VERSION "HNNBNNNYNNNNNNNNNNNNNNNNNNNNNNNNNNNNNNNNNN/4/%%%/4/'%**4NNN///"

NS_ :

BS_:

BU_: BAP_Tester BMS_NV_12V Gateway_Max Klima

BO_ 252 ESC_51_Auth: 64 Gateway_Max
 SG_ ESC_51_CRC : 0|8@1+ (1,0) [0|255] ""  Vector__XXX
 SG_ ESC_51_BZ : 8|4@1+ (1,0) [0|15] ""  Vector__XXX
 SG_ ESC_aktBR_Modus_02 : 12|2@1+ (1.0,0.0) [0.0|3] ""  Vector__XXX
 SG_ ESC_Blending_Solldruck : 14|10@1+ (0.25,0) [0.00|250.00] "Unit_Bar"  Vector__XXX
 SG_ ESC_aktBr_Volumenstrom : 24|16@1+ (0.0078125,-252) [-252.0000000|252.0000000] "Unit_MilliLiterPerSec"  Vector__XXX
 SG_ ESC_EBKV_Kraftblending_Modus : 40|2@1+ (1.0,0.0) [0.0|3] ""  Vector__XXX
 SG_ ESC_Bremsdruck_Modell : 42|10@1+ (0.25,0) [0.00|250.00] "Unit_Bar"  Vector__XXX
 SG_ ESC_Bremsdruck_02 : 52|10@1+ (0.3,-30) [-30.0|276.6] "Unit_Bar"  Vector__XXX
 SG_ ESC_QBit_Bremsdruck_02 : 62|1@1+ (1.0,0.0) [0.0|1] ""  Vector__XXX
 SG_ ESC_Allradverteilung_aktiv : 63|1@1+ (1.0,0.0) [0.0|1] ""  Vector__XXX
 SG_ ESP_HL_Radgeschw_02 : 64|16@1+ (0.0075,0) [0.0000|491.4900] "Unit_KiloMeterPerHour"  Vector__XXX
 SG_ ESP_HR_Radgeschw_02 : 80|16@1+ (0.0075,0) [0.0000|491.4900] "Unit_KiloMeterPerHour"  Vector__XXX
 SG_ ESP_VL_Radgeschw_02 : 96|16@1+ (0.0075,0) [0.0000|491.4900] "Unit_KiloMeterPerHour"  Vector__XXX
 SG_ ESP_VR_Radgeschw_02 : 112|16@1+ (0.0075,0) [0.0000|491.4900] "Unit_KiloMeterPerHour"  Vector__XXX
 SG_ ESP_FZR_uebersteuern : 128|8@1+ (0.004,0) [0.000|1.000] ""  Vector__XXX
 SG_ ESP_FZR_untersteuern : 136|8@1+ (0.004,0) [0.000|1.000] ""  Vector__XXX
 SG_ ESC_Anf_Mindestreku : 144|1@1+ (1.0,0.0) [0.0|1] ""  Vector__XXX
 SG_ ESC_GMV_aktiv : 145|3@1+ (1.0,0.0) [0.0|7] ""  Vector__XXX
 SG_ ESC_GMV_nicht_verfuegbar : 148|1@1+ (1.0,0.0) [0.0|1] ""  Vector__XXX
 SG_ ESC_Status_vRef_Stuetzeingriff : 149|1@1+ (1.0,0.0) [0.0|1] ""  Vector__XXX
 SG_ FDR_Allradverteilung_aktiv : 150|1@1+ (1.0,0.0) [0.0|1] ""  Vector__XXX
 SG_ FDR_Anf_Allradbetrieb : 151|1@1+ (1.0,0.0) [0.0|1] ""  Vector__XXX
 SG_ ESP_HL_Bremsmoment : 152|8@1+ (20,0) [0|5060] "Unit_NewtoMeter"  Vector__XXX
 SG_ ESP_HR_Bremsmoment : 160|8@1+ (20,0) [0|5060] "Unit_NewtoMeter"  Vector__XXX
 SG_ ESP_VR_Bremsmoment : 168|8@1+ (40,0) [0|10120] "Unit_NewtoMeter"  Vector__XXX
 SG_ ESP_VL_Bremsmoment : 176|8@1+ (40,0) [0|10120] "Unit_NewtoMeter"  Vector__XXX
 SG_ ESP_FDR_uebersteuern : 184|8@1+ (0.004,0) [0.000|1.000] ""  Vector__XXX
 SG_ ESP_FDR_untersteuern : 192|8@1+ (0.004,0) [0.000|1.000] ""  Vector__XXX
 SG_ TSMomBegrenzung : 268|12@1+ (3,-12279) [-12279|0] ""  Vector__XXX
 SG_ ESC_Allrad_Anteil_max_sek : 280|9@1+ (0.2,0) [0.0|100.0] "Unit_PerCent"  Vector__XXX
 SG_ ESC_Allrad_Anteil_min_sek : 289|9@1+ (0.2,0) [0.0|100.0] "Unit_PerCent"  Vector__XXX
 SG_ ESC_Status_Eingriff : 298|2@1+ (1.0,0.0) [0.0|3] ""  Vector__XXX
 SG_ ESC_Status_Eingriff_sek : 300|2@1+ (1.0,0.0) [0.0|3] ""  Vector__XXX
 SG_ ESC_MomRad_Eingriff : 302|13@1+ (3,-12279) [-12279|12279] "Unit_None"  Vector__XXX
 SG_ ESC_MomRad_Eingriff_sek : 315|13@1+ (3,-12279) [-12279|12279] "Unit_None"  Vector__XXX
 SG_ ESC_Achsdrehzahl_Max : 328|14@1+ (0.4,-800) [-800.0|5752.4] "Unit_MinutInver"  Vector__XXX
 SG_ ESC_Achsdrehzahl_Min : 342|14@1+ (0.4,-800) [-800.0|5752.4] "Unit_MinutInver"  Vector__XXX
 SG_ ESC_Achsdrehzahl_Max_sek : 356|14@1+ (0.4,-800) [-800.0|5752.4] "Unit_MinutInver"  Vector__XXX
 SG_ ESC_Achsdrehzahl_Min_sek : 370|14@1+ (0.4,-800) [-800.0|5752.4] "Unit_MinutInver"  Vector__XXX
 SG_ SOK_ESC_51_Signatur : 480|32@1+ (1,0) [0|4294967295] ""  Vector__XXX

BO_ 253 ESP_21: 8 Gateway_Max
 SG_ ESP_21_CRC : 0|8@1+ (1,0) [0|255] ""  Vector__XXX
 SG_ ESP_21_BZ : 8|4@1+ (1,0) [0|15] ""  Vector__XXX
 SG_ BR_Eingriffsmoment : 12|10@1+ (1,-509) [-509|509] ""  Vector__XXX
 SG_ ESP_PLA_Bremseingriff : 22|1@1+ (1.0,0.0) [0.0|1] ""  Vector__XXX
 SG_ ESP_Diagnose : 23|1@1+ (1.0,0.0) [0.0|1] ""  Vector__XXX
 SG_ ESC_Reku_Freigabe : 24|1@1+ (1.0,0.0) [0.0|1] ""  Vector__XXX
 SG_ ESC_v_Signal_Qualifier_High_Low : 25|3@1+ (1.0,0.0) [0.0|7] ""  Vector__XXX
 SG_ ESP_Vorsteuerung : 28|1@1+ (1.0,0.0) [0.0|1] ""  Vector__XXX
 SG_ ESP_AWV3_Brems_aktiv : 29|1@1+ (1.0,0.0) [0.0|1] ""  Vector__XXX
 SG_ OBD_Schlechtweg : 30|1@1+ (1.0,0.0) [0.0|1] ""  Vector__XXX
 SG_ OBD_QBit_Schlechtweg : 31|1@1+ (1.0,0.0) [0.0|1] ""  Vector__XXX
 SG_ ESP_v_Signal : 32|16@1+ (0.01,0) [0.00|655.32] "Unit_KiloMeterPerHour"  BMS_NV_12V,Klima
 SG_ ASR_Tastung_passiv : 48|1@1+ (1.0,0.0) [0.0|1] ""  Vector__XXX
 SG_ ESP_Tastung_passiv : 49|1@1+ (1.0,0.0) [0.0|1] ""  Vector__XXX
 SG_ ESP_Systemstatus : 50|1@1+ (1.0,0.0) [0.0|1] ""  Vector__XXX
 SG_ ASR_Schalteingriff : 51|2@1+ (1.0,0.0) [0.0|3] ""  Vector__XXX
 SG_ ESP_Haltebestaetigung : 53|1@1+ (1.0,0.0) [0.0|1] ""  Vector__XXX
 SG_ ESP_MKB_Abbruch_Geschw : 54|1@1+ (1.0,0.0) [0.0|1] ""  Vector__XXX
 SG_ ESP_QBit_v_Signal : 55|1@1+ (1.0,0.0) [0.0|1] ""  Klima
 SG_ ABS_Bremsung : 56|1@1+ (1.0,0.0) [0.0|1] ""  Vector__XXX
 SG_ ASR_Anf : 57|1@1+ (1.0,0.0) [0.0|1] ""  Vector__XXX
 SG_ MSR_Anf : 58|1@1+ (1.0,0.0) [0.0|1] ""  Vector__XXX
 SG_ EBV_Eingriff : 59|1@1+ (1.0,0.0) [0.0|1] ""  Vector__XXX
 SG_ EDS_Eingriff : 60|1@1+ (1.0,0.0) [0.0|1] ""  Vector__XXX
 SG_ ESP_Eingriff : 61|1@1+ (1.0,0.0) [0.0|1] ""  Vector__XXX
 SG_ ESP_ASP : 62|1@1+ (1.0,0.0) [0.0|1] ""  Vector__XXX
 SG_ ESP_Anhaltevorgang_ACC_aktiv : 63|1@1+ (1.0,0.0) [0.0|1] ""  Vector__XXX

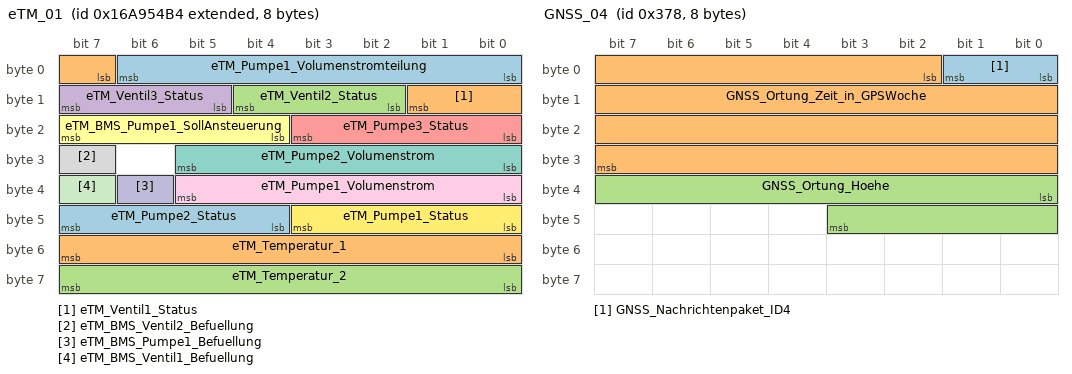
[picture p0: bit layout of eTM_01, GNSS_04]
BO_ 2527679668 eTM_01: 8 Gateway_Max
 SG_ eTM_Pumpe1_Volumenstromteilung : 0|7@1+ (0.01,0) [0.00|1.00] "Unit_None"  Vector__XXX
 SG_ eTM_Ventil1_Status : 7|3@1+ (1.0,0.0) [0.0|7] ""  Klima
 SG_ eTM_Ventil2_Status : 10|3@1+ (1.0,0.0) [0.0|7] ""  Klima
 SG_ eTM_Ventil3_Status : 13|3@1+ (1.0,0.0) [0.0|7] ""  Klima
 SG_ eTM_Pumpe3_Status : 16|4@1+ (10,0) [0|120] "Unit_PerCent"  Vector__XXX
 SG_ eTM_BMS_Pumpe1_SollAnsteuerung : 20|4@1+ (10,0) [0|130] "Unit_PerCent"  Klima
 SG_ eTM_Pumpe2_Volumenstrom : 24|6@1+ (0.5,0) [0.0|30.0] "Unit_LiterPerMinut"  Klima
 SG_ eTM_BMS_Ventil2_Befuellung : 31|1@1+ (1.0,0.0) [0.0|1] ""  Klima
 SG_ eTM_Pumpe1_Volumenstrom : 32|6@1+ (0.5,0) [0.0|30.0] "Unit_LiterPerMinut"  Klima
 SG_ eTM_BMS_Pumpe1_Befuellung : 38|1@1+ (1.0,0.0) [0.0|1] ""  Klima
 SG_ eTM_BMS_Ventil1_Befuellung : 39|1@1+ (1.0,0.0) [0.0|1] ""  Klima
 SG_ eTM_Pumpe1_Status : 40|4@1+ (10,0) [0|120] "Unit_PerCent"  Klima
 SG_ eTM_Pumpe2_Status : 44|4@1+ (10,0) [0|120] "Unit_PerCent"  Klima
 SG_ eTM_Temperatur_1 : 48|8@1+ (0.75,-40) [-40.00|149.75] "Unit_DegreCelsi"  Klima
 SG_ eTM_Temperatur_2 : 56|8@1+ (0.75,-40) [-40.00|149.00] "Unit_DegreCelsi"  Klima

BO_ 2589283684 FoD_01: 8 Gateway_Max
 SG_ GRA_FoD_Status : 58|2@1+ (1.0,0.0) [0.0|3] ""  Vector__XXX
 SG_ FoD_Transmission_Info : 60|2@1+ (1.0,0.0) [0.0|3] ""  Vector__XXX

BO_ 2549875526 FoD_Klima_Req: 8 Gateway_Max
 SG_ FoD_Klima_Req_Data : 0|64@1+ (1.0,0.0) [0.0|18446744073709551615] ""  Klima

BO_ 2550006598 FoD_Klima_Resp: 8 Klima
 SG_ FoD_Klima_Resp_Data : 0|64@1+ (1.0,0.0) [0.0|18446744073709551615] ""  Gateway_Max

BO_ 888 GNSS_04: 8 Gateway_Max
 SG_ GNSS_Nachrichtenpaket_ID4 : 0|2@1+ (1,0) [0|3] "Unit_Bit"  Vector__XXX
 SG_ GNSS_Ortung_Zeit_in_GPSWoche : 2|30@1+ (1,0) [0|604800001] "Unit_MilliSecon"  Vector__XXX
 SG_ GNSS_Ortung_Hoehe : 32|12@1+ (2,-500) [-500|7686] "Unit_Meter"  Klima

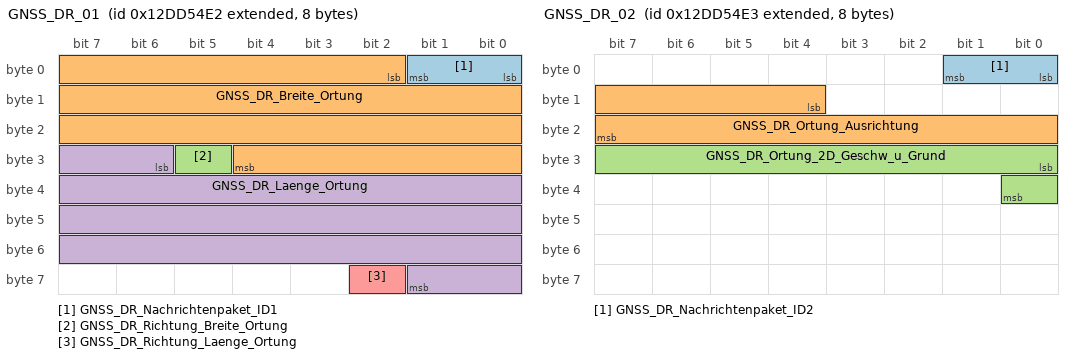
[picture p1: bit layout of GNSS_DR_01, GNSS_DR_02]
BO_ 2463978722 GNSS_DR_01: 8 Gateway_Max
 SG_ GNSS_DR_Nachrichtenpaket_ID1 : 0|2@1+ (1,0) [0|3] "Unit_Bit"  Vector__XXX
 SG_ GNSS_DR_Breite_Ortung : 2|27@1+ (0.000001,0) [0.000000|90.000000] "Unit_DegreOfArc"  Klima
 SG_ GNSS_DR_Richtung_Breite_Ortung : 29|1@1+ (1.0,0.0) [0.0|1] ""  Klima
 SG_ GNSS_DR_Laenge_Ortung : 30|28@1+ (0.000001,0) [0.000000|180.000000] "Unit_DegreOfArc"  Klima
 SG_ GNSS_DR_Richtung_Laenge_Ortung : 58|1@1+ (1.0,0.0) [0.0|1] ""  Klima

BO_ 2463978723 GNSS_DR_02: 8 Gateway_Max
 SG_ GNSS_DR_Nachrichtenpaket_ID2 : 0|2@1+ (1,0) [0|3] "Unit_Bit"  Vector__XXX
 SG_ GNSS_DR_Ortung_Ausrichtung : 12|12@1+ (0.1,0) [0.0|359.9] "Unit_DegreOfArc"  Klima
 SG_ GNSS_DR_Ortung_2D_Geschw_u_Grund : 24|9@1+ (0.25,0) [0.00|125.00] "Unit_MeterPerSecon"  Vector__XXX

BO_ 2463978726 GNSS_DR_05: 8 Gateway_Max
 SG_ GNSS_DR_UTC_Zeit : 0|32@1+ (1,0) [1|4294967295] "Unit_Secon"  Klima

BO_ 1410 HDSG_01: 4 Gateway_Max
 SG_ HD_Endstellung_oben : 0|1@1+ (1.0,0.0) [0.0|1] ""  Vector__XXX
 SG_ HD_Endstellung_unten : 1|1@1+ (1.0,0.0) [0.0|1] ""  Vector__XXX
 SG_ HD_Bewegung_auf : 2|1@1+ (1.0,0.0) [0.0|1] ""  Vector__XXX
 SG_ HD_Bewegung_zu : 3|1@1+ (1.0,0.0) [0.0|1] ""  Vector__XXX
 SG_ HD_Innentaster_betaetigt : 4|1@1+ (1.0,0.0) [0.0|1] ""  Vector__XXX
 SG_ HD_Kupp_Ma_aktiv : 5|1@1+ (1.0,0.0) [0.0|1] ""  Vector__XXX
 SG_ HD_Kupp_Sl_aktiv : 6|1@1+ (1.0,0.0) [0.0|1] ""  Vector__XXX
 SG_ HD_UeKB_erkannt : 7|1@1+ (1.0,0.0) [0.0|1] ""  Vector__XXX
 SG_ HD_Position : 8|8@1+ (1,0) [0|100] "Unit_PerCent"  Vector__XXX
 SG_ HD_SG_MA_KD_Fehler : 16|1@1+ (1.0,0.0) [0.0|1] ""  Vector__XXX
 SG_ HD_SG_SL_KD_Fehler : 17|1@1+ (1.0,0.0) [0.0|1] ""  Vector__XXX
 SG_ HD_Taster_defekt : 18|1@1+ (1.0,0.0) [0.0|1] ""  Vector__XXX
 SG_ HD_Spannung : 19|1@1+ (1.0,0.0) [0.0|1] ""  Vector__XXX
 SG_ HD_Rueckmeld_prog : 20|1@1+ (1.0,0.0) [0.0|1] ""  Vector__XXX
 SG_ HD_Verriegelungstaster_betaetigt : 21|1@1+ (1.0,0.0) [0.0|1] ""  Vector__XXX
 SG_ HD_Verr_Taster_betaetigt_inv : 22|1@1+ (1.0,0.0) [0.0|1] ""  Vector__XXX
 SG_ HD_ZZH_Schalter_S3 : 23|1@1+ (1.0,0.0) [0.0|1] ""  Vector__XXX
 SG_ HDSG_Anf_Umluftklappe : 31|1@1+ (1.0,0.0) [0.0|1] ""  Klima

BO_ 1016 HLR_02: 8 Gateway_Max
 SG_ HLR_FlHz_Freigabe_Ruhesitz : 14|2@1+ (1.0,0.0) [0.0|3] ""  Vector__XXX
 SG_ HLR_FlHz_Freigabe_VR : 16|2@1+ (1.0,0.0) [0.0|3] ""  Vector__XXX
 SG_ HLR_FlHz_Freigabe_VL : 18|2@1+ (1.0,0.0) [0.0|3] ""  Vector__XXX
 SG_ HLR_FlHz_Freigabe_HR : 20|2@1+ (1.0,0.0) [0.0|3] ""  Vector__XXX
 SG_ HLR_FlHz_Freigabe_HL : 22|2@1+ (1.0,0.0) [0.0|3] ""  Vector__XXX
 SG_ HLR_TCH_Freigabe : 24|1@1+ (1.0,0.0) [0.0|1] ""  Vector__XXX
 SG_ HLR_SIH_Freigabe_Fond : 25|1@1+ (1.0,0.0) [0.0|1] ""  Vector__XXX
 SG_ HLR_Sp_Heizung_Freigabe_BT : 26|1@1+ (1.0,0.0) [0.0|1] ""  Vector__XXX
 SG_ HLR_Sp_Heizung_Freigabe_FT : 27|1@1+ (1.0,0.0) [0.0|1] ""  Vector__XXX
 SG_ HLR_KRH_Freigabe_VL : 28|2@1+ (1.0,0.0) [0.0|3] ""  Klima
 SG_ HLR_KRH_Freigabe_VR : 30|2@1+ (1.0,0.0) [0.0|3] ""  Klima
 SG_ HLR_SIH_Freigabe_VL : 32|2@1+ (1.0,0.0) [0.0|3] ""  Klima
 SG_ HLR_SIH_Freigabe_VR : 34|2@1+ (1.0,0.0) [0.0|3] ""  Klima
 SG_ HLR_SIH_Freigabe_HL : 36|2@1+ (1.0,0.0) [0.0|3] ""  Klima
 SG_ HLR_SIH_Freigabe_HR : 38|2@1+ (1.0,0.0) [0.0|3] ""  Klima
 SG_ HLR_SIL_Freigabe_VL : 40|2@1+ (1.0,0.0) [0.0|3] ""  Klima
 SG_ HLR_SIL_Freigabe_VR : 42|2@1+ (1.0,0.0) [0.0|3] ""  Klima
 SG_ HLR_SIL_Freigabe_HL : 44|2@1+ (1.0,0.0) [0.0|3] ""  Klima
 SG_ HLR_SIL_Freigabe_HR : 46|2@1+ (1.0,0.0) [0.0|3] ""  Klima
 SG_ HLR_FSH_Freigabe : 48|6@1+ (20,0) [20|1240] "Unit_Watt"  Klima
 SG_ HLR_HSH_Freigabe : 54|1@1+ (1.0,0.0) [0.0|1] ""  Klima
 SG_ HLR_LRH_Freigabe : 55|1@1+ (1.0,0.0) [0.0|1] ""  Klima
 SG_ HLR_PTC_linear_Freigabe : 56|6@1+ (50,0) [0|3100] "Unit_Watt"  Klima
 SG_ HLR_PTC_Freigabe : 62|2@1+ (1.0,0.0) [0.0|3] ""  Klima

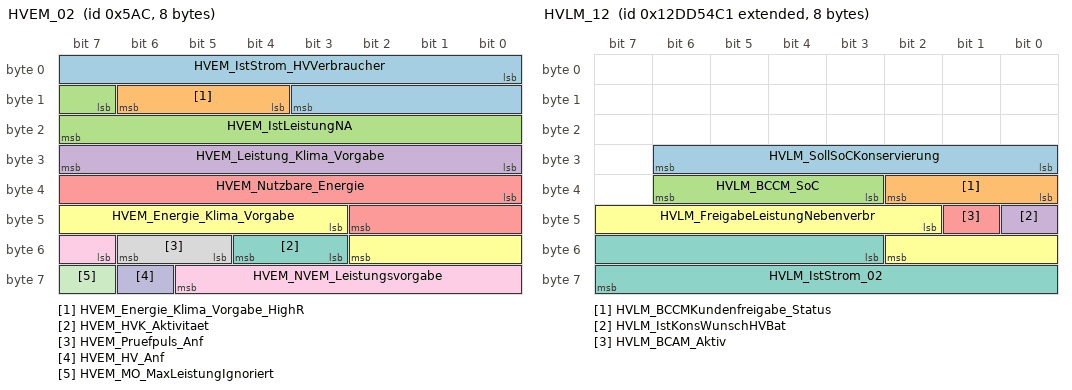
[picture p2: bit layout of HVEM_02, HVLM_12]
BO_ 1452 HVEM_02: 8 Gateway_Max
 SG_ HVEM_IstStrom_HVVerbraucher : 0|12@1+ (0.1,-204.7) [-204.7|204.6] "Unit_Amper"  Vector__XXX
 SG_ HVEM_Energie_Klima_Vorgabe_HighR : 12|3@1+ (10,0) [0|50] "Unit_WattHour"  Klima
 SG_ HVEM_IstLeistungNA : 15|9@1+ (50,0) [0|25450] "Unit_Watt"  Vector__XXX
 SG_ HVEM_Leistung_Klima_Vorgabe : 24|8@1+ (50,0) [0|12650] "Unit_Watt"  Klima
 SG_ HVEM_Nutzbare_Energie : 32|11@1+ (50,0) [0|102200] "Unit_WattHour"  Klima
 SG_ HVEM_Energie_Klima_Vorgabe : 43|8@1+ (50,0) [0|12650] "Unit_WattHour"  Klima
 SG_ HVEM_HVK_Aktivitaet : 51|2@1+ (1.0,0.0) [0.0|3] ""  Vector__XXX
 SG_ HVEM_Pruefpuls_Anf : 53|2@1+ (1.0,0.0) [0.0|3] ""  Vector__XXX
 SG_ HVEM_NVEM_Leistungsvorgabe : 55|7@1+ (50,0) [0|6250] "Unit_Watt"  Vector__XXX
 SG_ HVEM_HV_Anf : 62|1@1+ (1.0,0.0) [0.0|1] ""  Klima
 SG_ HVEM_MO_MaxLeistungIgnoriert : 63|1@1+ (1.0,0.0) [0.0|1] ""  Vector__XXX

BO_ 1385 HVEM_04: 8 Gateway_Max
 SG_ HVEM_ZusatzMinLeistungNA_Anf : 0|9@1+ (50,0) [0|25450] "Unit_Watt"  Vector__XXX
 SG_ HVEM_Betriebsart : 9|3@1+ (1.0,0.0) [0.0|7] ""  Vector__XXX
 SG_ HVEM_NVLeistungEmpf : 12|4@1+ (100,0) [0|1500] "Unit_Watt"  Vector__XXX
 SG_ HVEM_DCDC_Freigabe : 16|1@1+ (1.0,0.0) [0.0|1] ""  Vector__XXX
 SG_ HVEM_KlimaMaxHVStrom : 17|5@1+ (1,0) [0|31] "Unit_Amper"  Vector__XXX
 SG_ HVEM_Ladesteckerentr_Anf : 23|1@1+ (1.0,0.0) [0.0|1] ""  Vector__XXX
 SG_ HVEM_LeistungsAnf : 24|1@1+ (1.0,0.0) [0.0|1] ""  Vector__XXX
 SG_ HVEM_Nachlad_Status : 25|2@1+ (1.0,0.0) [0.0|3] ""  Vector__XXX
 SG_ HVEM_Abschaltstatus : 27|3@1+ (1.0,0.0) [0.0|7] ""  Vector__XXX
 SG_ HVEM_Anf_ReichweiteNV : 30|2@1+ (1.0,0.0) [0.0|3] ""  Vector__XXX
 SG_ HVEM_WunschLeistungNA_Anf : 32|9@1+ (50,0) [0|25450] "Unit_Watt"  Vector__XXX
 SG_ HVEM_Text_1 : 41|1@1+ (1.0,0.0) [0.0|1] ""  Vector__XXX
 SG_ HVEM_Nachladen_Anf : 42|1@1+ (1.0,0.0) [0.0|1] ""  Vector__XXX
 SG_ HVEM_FreigabeKlimatisierung : 43|2@1+ (1.0,0.0) [0.0|3] ""  Klima
 SG_ HVEM_FreigabeBattHeizung : 45|2@1+ (1.0,0.0) [0.0|3] ""  Vector__XXX
 SG_ HVEM_MinLeistungNA_Anf : 47|9@1+ (50,0) [0|25450] "Unit_Watt"  Vector__XXX
 SG_ HVEM_Leistung_Bat_Kond_Vorgabe : 56|8@1+ (50,0) [0|12650] "Unit_Watt"  Klima

BO_ 1283 HVK_01: 8 Gateway_Max
 SG_ HVK_01_CRC : 0|8@1+ (1,0) [0|255] ""  Klima
 SG_ HVK_01_BZ : 8|4@1+ (1,0) [0|15] ""  Klima
 SG_ HVK_Istmodus_Anf : 12|1@1+ (1.0,0.0) [0.0|1] ""  Vector__XXX
 SG_ HVK_TN1_Sollmodus : 13|2@1+ (1.0,0.0) [0.0|3] ""  Vector__XXX
 SG_ HVK_Vorladung_aktiv : 15|1@1+ (1.0,0.0) [0.0|1] ""  Klima
 SG_ HVK_BMS_Sollmodus : 24|3@1+ (1.0,0.0) [0.0|7] ""  Vector__XXX
 SG_ HVK_DCDC_Sollmodus : 27|3@1+ (1.0,0.0) [0.0|7] ""  Vector__XXX
 SG_ HVK_EKK_Sollmodus : 30|3@1+ (1.0,0.0) [0.0|7] ""  Vector__XXX
 SG_ HVK_HVPTC_Sollmodus : 33|3@1+ (1.0,0.0) [0.0|7] ""  Vector__XXX
 SG_ HVK_HVLM_Sollmodus : 36|3@1+ (1.0,0.0) [0.0|7] ""  Vector__XXX
 SG_ HVK_HV_Netz_Warnungen : 39|2@1+ (1.0,0.0) [0.0|3] ""  Klima
 SG_ HV_Bordnetz_aktiv : 41|1@1+ (1.0,0.0) [0.0|1] ""  Klima
 SG_ HV_Bordnetz_Fehler : 42|1@1+ (1.0,0.0) [0.0|1] ""  Klima
 SG_ HVK_Gesamtst_Spgfreiheit : 43|2@1+ (1.0,0.0) [0.0|3] ""  Vector__XXX
 SG_ HVK_AktiveEntladung_Anf : 45|1@1+ (1.0,0.0) [0.0|1] ""  Klima
 SG_ HVK_HVEM_Freigabe : 46|2@1+ (1.0,0.0) [0.0|3] ""  Vector__XXX
 SG_ HVK_Notabschaltung_Anf : 48|2@1+ (1.0,0.0) [0.0|3] ""  Klima
 SG_ HVK_Iso_Messung_Start : 50|3@1+ (1.0,0.0) [0.0|7] ""  Klima
 SG_ HVK_Ladebereit : 53|3@1+ (1.0,0.0) [0.0|7] ""  Vector__XXX
 SG_ HVK_PPulsFreigabe : 56|2@1+ (1.0,0.0) [0.0|3] ""  Vector__XXX

BO_ 2331595857 HVK_04: 24 Gateway_Max
 SG_ HVK_BMS_DC_Ladeschuetze_Soll : 12|3@1+ (1.0,0.0) [0.0|7] ""  Vector__XXX
 SG_ HVK_BMS_Hauptschuetze_Soll : 15|3@1+ (1.0,0.0) [0.0|7] ""  Vector__XXX
 SG_ HVK_DC_PruefpulsStatus : 18|2@1+ (1.0,0.0) [0.0|3] ""  Vector__XXX

BO_ 1428 HVLM_05: 8 Gateway_Max
 SG_ HVLM_Warnmeldungen : 0|5@1+ (1.0,0.0) [0.0|31] ""  Vector__XXX
 SG_ HVLM_Restladezeit_HV_Bat_02 : 12|9@1+ (5,0) [0|2545] "Unit_Minut"  Vector__XXX
 SG_ HVLM_Lademodus_HV_Bat : 21|2@1+ (1.0,0.0) [0.0|3] ""  Vector__XXX
 SG_ HVLM_VK_STH_Einsatz : 23|3@1+ (1.0,0.0) [0.0|7] ""  Vector__XXX
 SG_ HVLM_Anzeigetexte : 26|3@1+ (1.0,0.0) [0.0|7] ""  Vector__XXX
 SG_ HVLM_Bat_laden_aktiv : 29|1@1+ (1.0,0.0) [0.0|1] ""  Klima
 SG_ HVLM_HVEM_MaxLeistung : 30|9@1+ (50,0) [0|25450] "Unit_Watt"  Vector__XXX
 SG_ HVLM_Standklima_Timer_Status : 39|1@1+ (1.0,0.0) [0.0|1] ""  Vector__XXX
 SG_ HVLM_Fehler_Ladestecker : 40|1@1+ (1.0,0.0) [0.0|1] ""  Vector__XXX
 SG_ HVLM_Fehler_Verriegelung : 41|1@1+ (1.0,0.0) [0.0|1] ""  Vector__XXX
 SG_ HVLM_Ladeart : 42|2@1+ (1.0,0.0) [0.0|3] ""  Klima
 SG_ HVLM_Status_Netz : 44|1@1+ (1.0,0.0) [0.0|1] ""  Vector__XXX
 SG_ HVLM_HV_Anf : 45|2@1+ (1.0,0.0) [0.0|3] ""  Vector__XXX
 SG_ HVLM_VK_Anf : 47|1@1+ (1.0,0.0) [0.0|1] ""  Klima
 SG_ HVLM_Ladesystemhinweise : 48|2@1+ (1.0,0.0) [0.0|3] ""  Vector__XXX
 SG_ HVLM_VK_Modus : 50|2@1+ (1.0,0.0) [0.0|3] ""  Vector__XXX
 SG_ HVLM_Stecker_Status : 52|2@1+ (1.0,0.0) [0.0|3] ""  Vector__XXX
 SG_ HVLM_Langzeit_Laden : 54|2@1+ (1.0,0.0) [0.0|3] ""  Vector__XXX
 SG_ HVLM_Klima_Temp : 56|5@1+ (0.5,15.5) [15.5|29.5] "Unit_DegreCelsi"  Vector__XXX
 SG_ HVLM_HSH_Anf : 61|1@1+ (1.0,0.0) [0.0|1] ""  Vector__XXX
 SG_ HVLM_Bat_Konditionierung_Anf : 62|1@1+ (1.0,0.0) [0.0|1] ""  Vector__XXX
 SG_ HVLM_FSH_Anf : 63|1@1+ (1.0,0.0) [0.0|1] ""  Vector__XXX

BO_ 2463978689 HVLM_12: 8 Gateway_Max
 SG_ HVLM_SollSoCKonservierung : 24|7@1+ (1,0) [0|100] "Unit_PerCent"  Vector__XXX
 SG_ HVLM_BCCMKundenfreigabe_Status : 32|3@1+ (1.0,0.0) [0.0|7] ""  Vector__XXX
 SG_ HVLM_BCCM_SoC : 35|4@1+ (5,50) [50|100] "Unit_PerCent"  Vector__XXX
 SG_ HVLM_IstKonsWunschHVBat : 40|1@1+ (1.0,0.0) [0.0|1] ""  Vector__XXX
 SG_ HVLM_BCAM_Aktiv : 41|1@1+ (1.0,0.0) [0.0|1] ""  Vector__XXX
 SG_ HVLM_FreigabeLeistungNebenverbr : 42|9@1+ (50,0) [0|25500] "Unit_Watt"  Vector__XXX
 SG_ HVLM_IstStrom_02 : 51|13@1+ (0.1,-409.4) [-409.4|409.5] "Unit_Amper"  Vector__XXX

BO_ 625 HVLM_13: 32 Gateway_Max
 SG_ HVLM_13_CRC : 0|8@1+ (1,0) [0|255] ""  Vector__XXX
 SG_ HVLM_13_BZ : 8|4@1+ (1,0) [0|15] ""  Vector__XXX
 SG_ HVLM_Stecker_VerEntriegelnAnf_A : 12|2@1+ (1.0,0.0) [0.0|3] ""  Vector__XXX
 SG_ HVLM_Stecker_VerEntriegelnAnf_B : 14|2@1+ (1.0,0.0) [0.0|3] ""  Vector__XXX
 SG_ HVLM_DC_SollStrom : 16|11@1+ (0.1,0) [0.0|160.0] "Unit_Amper"  Vector__XXX
 SG_ HVLM_OBG_SollModus : 27|3@1+ (1.0,0.0) [0.0|7] ""  Vector__XXX
 SG_ HVLM_SF4OeffnenAnf_A : 30|1@1+ (1.0,0.0) [0.0|1] ""  Vector__XXX
 SG_ HVLM_SF4OeffnenAnf_B : 31|1@1+ (1.0,0.0) [0.0|1] ""  Vector__XXX
 SG_ HVLM_S2SchliessenAnf_A : 32|1@1+ (1.0,0.0) [0.0|1] ""  Vector__XXX
 SG_ HVLM_S2SchliessenAnf_B : 33|1@1+ (1.0,0.0) [0.0|1] ""  Vector__XXX
 SG_ HVLM_CP_Fehlerzustand_A : 34|3@1+ (1.0,0.0) [0.0|7] ""  Vector__XXX
 SG_ HVLM_CP_Fehlerzustand_B : 37|3@1+ (1.0,0.0) [0.0|7] ""  Vector__XXX
 SG_ HVLM_CP_MaxStrom_A : 40|10@1+ (0.1,0) [0.0|80.0] "Unit_Amper"  Vector__XXX
 SG_ HVLM_CP_KommProtokoll_A : 50|2@1+ (1.0,0.0) [0.0|3] ""  Vector__XXX
 SG_ HVLM_CP_State_A : 52|4@1+ (1.0,0.0) [0.0|15] ""  Vector__XXX
 SG_ HVLM_CP_MaxStrom_B : 56|10@1+ (0.1,0) [0.0|80.0] "Unit_Amper"  Vector__XXX
 SG_ HVLM_CP_KommProtokoll_B : 66|2@1+ (1.0,0.0) [0.0|3] ""  Vector__XXX
 SG_ HVLM_CP_State_B : 68|4@1+ (1.0,0.0) [0.0|15] ""  Vector__XXX
 SG_ HVLM_Max_Strom_Netz_L1 : 72|10@1+ (0.1,0) [0.0|63.0] "Unit_Amper"  Vector__XXX
 SG_ HVLM_Max_Strom_Netz_L2 : 82|10@1+ (0.1,0) [0.0|63.0] "Unit_Amper"  Vector__XXX
 SG_ HVLM_Max_Strom_Netz_L3 : 92|10@1+ (0.1,0) [0.0|63.0] "Unit_Amper"  Vector__XXX
 SG_ HVLM_MaxSpannung_OBG_HV : 102|10@1+ (1,0) [0|1021] "Unit_Volt"  Vector__XXX
 SG_ HVLM_Stecker_Notentriegeln_Anf_A : 112|2@1+ (1.0,0.0) [0.0|3] ""  Vector__XXX
 SG_ HVLM_Stecker_Notentriegeln_Anf_B : 114|2@1+ (1.0,0.0) [0.0|3] ""  Vector__XXX
 SG_ HVLM_Ladeklappe_VerEntriegeAnf_1 : 116|2@1+ (1.0,0.0) [0.0|3] ""  Vector__XXX
 SG_ HVLM_Ladeklappe_VerEntriegeAnf_2 : 118|2@1+ (1.0,0.0) [0.0|3] ""  Vector__XXX
 SG_ LVB_Ladegeschw : 120|13@1+ (1,0) [0|5000] "Unit_None"  Vector__XXX
 SG_ LVB_LadegeschwEinheit : 133|3@1+ (1.0,0.0) [0.0|7] ""  Vector__XXX
 SG_ LVB_StatusLadegeschw : 136|2@1+ (1.0,0.0) [0.0|3] ""  Vector__XXX
 SG_ LVB_StatusRestladezeit : 138|2@1+ (1.0,0.0) [0.0|3] ""  Vector__XXX
 SG_ LVB_Restladezeit : 140|12@1+ (1,0) [0|3000] "Unit_Minut"  Vector__XXX
 SG_ HVLM_LadedosenSuchlicht : 152|3@1+ (1.0,0.0) [0.0|7] ""  Vector__XXX
 SG_ LVB_Ladegeschw_VZ : 157|1@1+ (1.0,0.0) [0.0|1] ""  Vector__XXX
 SG_ HVLM_ReversierenFreigabe_Lk1 : 223|1@1+ (1.0,0.0) [0.0|1] ""  Vector__XXX
 SG_ HVLM_SchnellladeVokoManuell_Anf : 224|1@1+ (1.0,0.0) [0.0|1] ""  Vector__XXX
 SG_ HVLM_SchnellladeVokoAuto_Anf : 225|1@1+ (1.0,0.0) [0.0|1] ""  Vector__XXX
 SG_ HVLM_Ladeklappe_VerEntriegeAnf_3 : 229|2@1+ (1.0,0.0) [0.0|3] ""  Vector__XXX
 SG_ HVLM_ReversierenFreigabe_Lk2 : 231|1@1+ (1.0,0.0) [0.0|1] ""  Vector__XXX
 SG_ HVLM_elektrLk_Kommandierung_Lk2 : 232|3@1+ (1.0,0.0) [0.0|7] ""  Vector__XXX
 SG_ HVLM_elektrLk_Kommandierung_Lk1 : 235|3@1+ (1.0,0.0) [0.0|7] ""  Vector__XXX
 SG_ HVLM_elektrLk_Kommandierung_Lk3 : 240|3@1+ (1.0,0.0) [0.0|7] ""  Vector__XXX
 SG_ HVLM_ReversierenFreigabe_Lk3 : 243|1@1+ (1.0,0.0) [0.0|1] ""  Vector__XXX
 SG_ HVLM_Stecker_Notentriegeln_Anf_C : 250|2@1+ (1.0,0.0) [0.0|3] ""  Vector__XXX
 SG_ HVLM_Stecker_VerEntriegelnAnf_C : 252|2@1+ (1.0,0.0) [0.0|3] ""  Vector__XXX

BO_ 805 HVLM_13_SOK_Signatur: 4 Gateway_Max
 SG_ SOK_HVLM_13_Signatur : 0|32@1+ (1,0) [1|4294967295] "Unit_None"  Vector__XXX

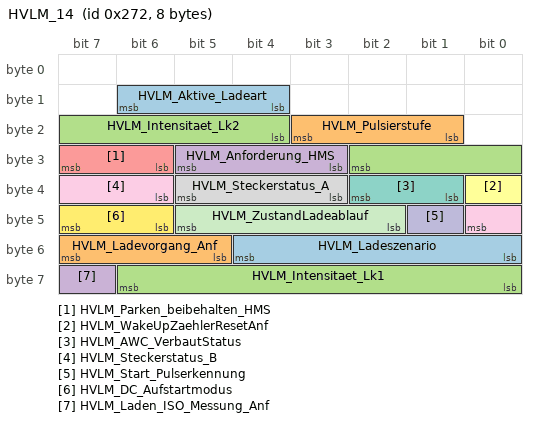
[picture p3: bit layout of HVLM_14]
BO_ 626 HVLM_14: 8 Gateway_Max
 SG_ HVLM_Aktive_Ladeart : 12|3@1+ (1.0,0.0) [0.0|7] ""  Vector__XXX
 SG_ HVLM_Pulsierstufe : 17|3@1+ (1.0,0.0) [0.0|7] ""  Vector__XXX
 SG_ HVLM_Intensitaet_Lk2 : 20|7@1+ (1,0) [0|100] "Unit_PerCent"  Vector__XXX
 SG_ HVLM_Anforderung_HMS : 27|3@1+ (1.0,0.0) [0.0|7] ""  Vector__XXX
 SG_ HVLM_Parken_beibehalten_HMS : 30|2@1+ (1.0,0.0) [0.0|3] ""  Vector__XXX
 SG_ HVLM_WakeUpZaehlerResetAnf : 32|1@1+ (1.0,0.0) [0.0|1] ""  Vector__XXX
 SG_ HVLM_AWC_VerbautStatus : 33|2@1+ (1.0,0.0) [0.0|3] ""  Vector__XXX
 SG_ HVLM_Steckerstatus_A : 35|3@1+ (1.0,0.0) [0.0|7] ""  Vector__XXX
 SG_ HVLM_Steckerstatus_B : 38|3@1+ (1.0,0.0) [0.0|7] ""  Vector__XXX
 SG_ HVLM_Start_Pulserkennung : 41|1@1+ (1.0,0.0) [0.0|1] ""  Vector__XXX
 SG_ HVLM_ZustandLadeablauf : 42|4@1+ (1.0,0.0) [0.0|15] ""  Vector__XXX
 SG_ HVLM_DC_Aufstartmodus : 46|2@1+ (1.0,0.0) [0.0|3] ""  Vector__XXX
 SG_ HVLM_Ladeszenario : 48|5@1+ (1.0,0.0) [0.0|31] ""  Vector__XXX
 SG_ HVLM_Ladevorgang_Anf : 53|3@1+ (1.0,0.0) [0.0|7] ""  Vector__XXX
 SG_ HVLM_Intensitaet_Lk1 : 56|7@1+ (1,0) [0|100] "Unit_PerCent"  Vector__XXX
 SG_ HVLM_Laden_ISO_Messung_Anf : 63|1@1+ (1.0,0.0) [0.0|1] ""  Vector__XXX

BO_ 2463978708 HVLM_CDO_01: 32 Gateway_Max
 SG_ HVLM_CDO_LsNachrichtSendenAnf : 13|1@1+ (1.0,0.0) [0.0|1] ""  Vector__XXX
 SG_ HVLM_CDO_LadeerlaubnisLm : 14|1@1+ (1.0,0.0) [0.0|1] ""  Vector__XXX
 SG_ HVLM_CDO_SteckerVerEntr_Status : 37|1@1+ (1.0,0.0) [0.0|1] ""  Vector__XXX
 SG_ HVLM_CDO_DynamischLaden_Status : 40|1@1+ (1.0,0.0) [0.0|1] ""  Vector__XXX
 SG_ HVLM_CDO_StromExt_Status : 41|1@1+ (1.0,0.0) [0.0|1] ""  Vector__XXX
 SG_ HVLM_CDO_SpannungExt_Status : 42|1@1+ (1.0,0.0) [0.0|1] ""  Vector__XXX
 SG_ HVLM_CDO_SollStromFzg_ext : 48|16@1+ (1,0) [0|1023] "Unit_Amper"  Vector__XXX
 SG_ HVLM_CDO_HvMinSpannungFzg : 72|16@1+ (1,0) [0|1200] "Unit_Volt"  Vector__XXX
 SG_ HVLM_CDO_HvMinStromFzg : 88|8@1+ (1,-1) [0|254] "Unit_Amper"  Vector__XXX
 SG_ HVLM_CDO_HvMaxSpannungFzg : 96|16@1+ (1,0) [0|1200] "Unit_Volt"  Vector__XXX
 SG_ HVLM_CDO_ReferenzLadezustandFzg : 112|8@1+ (1,0) [0|255] "Unit_PerCent"  Vector__XXX
 SG_ HVLM_CDO_MaxLadezeitFzg : 136|8@1+ (10,0) [0|2550] "Unit_Secon"  Vector__XXX
 SG_ HVLM_CDO_MaxLadezeitFzg_ext : 144|8@1+ (1,0) [0|255] "Unit_Minut"  Vector__XXX
 SG_ HVLM_CDO_RestLadedauerFzg : 152|8@1+ (1,-1) [0|254] "Unit_Minut"  Vector__XXX
 SG_ HVLM_CDO_GesamtKapazitaetHvBatt : 160|16@1+ (0.1,0) [0.0|6553.5] "Unit_KiloWattHour"  Vector__XXX
 SG_ HVLM_CDO_ProtokollVersionFzg : 192|8@1+ (1.0,0.0) [0.0|255] ""  Vector__XXX
 SG_ HVLM_CDO_ZielLadespannungFzg : 200|16@1+ (1,0) [0|1200] "Unit_Volt"  Vector__XXX
 SG_ HVLM_CDO_SollStromFzg : 216|8@1+ (1,0) [0|255] "Unit_Amper"  Vector__XXX
 SG_ HVLM_CDO_Fehler_HVBatUeberspgFzg : 224|1@1+ (1.0,0.0) [0.0|1] ""  Vector__XXX
 SG_ HVLM_CDO_Fehler_HVBatUnterspFzg : 225|1@1+ (1.0,0.0) [0.0|1] ""  Vector__XXX
 SG_ HVLM_CDO_Fehler_HVStromDiffFzg : 226|1@1+ (1.0,0.0) [0.0|1] ""  Vector__XXX
 SG_ HVLM_CDO_Fehler_HVBatUebertemp : 227|1@1+ (1.0,0.0) [0.0|1] ""  Vector__XXX
 SG_ HVLM_CDO_Fehler_HVBatSpgDiffFzg : 228|1@1+ (1.0,0.0) [0.0|1] ""  Vector__XXX
 SG_ HVLM_CDO_LadebereitFzg : 232|1@1+ (1.0,0.0) [0.0|1] ""  Vector__XXX
 SG_ HVLM_CDO_WahlhebelPosition_P_Fzg : 233|1@1+ (1.0,0.0) [0.0|1] ""  Vector__XXX
 SG_ HVLM_CDO_Fehler_Fahrzeug : 234|1@1+ (1.0,0.0) [0.0|1] ""  Vector__XXX
 SG_ HVLM_CDO_Status_Fahrzeug : 235|1@1+ (1.0,0.0) [0.0|1] ""  Vector__XXX
 SG_ HVLM_CDO_LadenBeendenAnfFzg : 236|1@1+ (1.0,0.0) [0.0|1] ""  Vector__XXX
 SG_ HVLM_CDO_HvBatIstLadezustandFzg : 240|8@1+ (1,0) [0|255] "Unit_PerCent"  Vector__XXX

BO_ 2331596000 HVLM_CJ_01: 48 Gateway_Max
 SG_ HVLM_CJ_01_Sendestatus : 12|1@1+ (1.0,0.0) [0.0|1] ""  Vector__XXX
 SG_ HVLM_CdoCj_SvsSchliessenAnf : 13|1@1+ (1.0,0.0) [0.0|1] ""  Vector__XXX
 SG_ HVLM_CJ_SendeAnf_LongMessage : 16|1@1+ (1.0,0.0) [0.0|1] ""  Vector__XXX
 SG_ HVLM_CJ_SendeAnf_Pausieren : 17|1@1+ (1.0,0.0) [0.0|1] ""  Vector__XXX
 SG_ HVLM_CJ_SendeAnf_Stoppen : 18|1@1+ (1.0,0.0) [0.0|1] ""  Vector__XXX
 SG_ HVLM_CJ_SendeAnf_EndACK : 19|1@1+ (1.0,0.0) [0.0|1] ""  Vector__XXX
 SG_ HVLM_CJ_SendeAnf_SMURM : 20|1@1+ (1.0,0.0) [0.0|1] ""  Vector__XXX
 SG_ HVLM_CJ_VerbindungAnf : 21|1@1+ (1.0,0.0) [0.0|1] ""  Vector__XXX
 SG_ HVLM_CJ_SendeAnf_ACK : 22|2@1+ (1.0,0.0) [0.0|3] ""  Vector__XXX
 SG_ HVLM_CJ_SendeAnf_SMRM : 24|1@1+ (1.0,0.0) [0.0|1] ""  Vector__XXX
 SG_ HVLM_CdoCj_SvSchliessenAnf : 25|1@1+ (1.0,0.0) [0.0|1] ""  Vector__XXX
 SG_ HVLM_CJ_SteckerVerEntr_Status : 26|1@1+ (1.0,0.0) [0.0|1] ""  Vector__XXX
 SG_ HVLM_CJ_FC1_FDC_Selection : 28|8@1+ (1,0) [0|255] "Unit_None"  Vector__XXX
 SG_ HVLM_CJ_FC2_FDC_Selection : 36|8@1+ (1,0) [0|255] "Unit_None"  Vector__XXX
 SG_ HVLM_CJ_FC3_FDC_Selection : 44|8@1+ (1,0) [0|255] "Unit_None"  Vector__XXX
 SG_ HVLM_CJ_FC4_FDC_Selection : 52|8@1+ (1,0) [0|255] "Unit_None"  Vector__XXX
 SG_ HVLM_CJ_FC5_FDC_Selection : 60|8@1+ (1,0) [0|255] "Unit_None"  Vector__XXX
 SG_ HVLM_CJ_FC6_FDC_Selection : 68|8@1+ (1,0) [0|255] "Unit_None"  Vector__XXX
 SG_ HVLM_CJ_FCFDC_CheckFzg : 76|8@1+ (1.0,0.0) [0.0|255] ""  Vector__XXX
 SG_ HVLM_CJ_IstSOC : 84|16@1+ (0.1,0) [0.0|100.0] "Unit_PerCent"  Vector__XXX
 SG_ HVLM_CJ_Lademodus : 100|8@1+ (1.0,0.0) [0.0|255] ""  Vector__XXX
 SG_ HVLM_CJ_CheckcodeFzg : 108|8@1+ (1,0) [0|255] "Unit_None"  Vector__XXX
 SG_ HVLM_CJ_CanTypFzg : 116|8@1+ (1.0,0.0) [0.0|255] ""  Vector__XXX
 SG_ HVLM_CJ_Restladezeit : 124|16@1+ (1,0) [0|600] "Unit_Minut"  Vector__XXX
 SG_ HVLM_CJ_PgiFzg : 140|8@1+ (1.0,0.0) [0.0|255] ""  Vector__XXX
 SG_ HVLM_CJ_GrundLadeendeFzg : 148|8@1+ (1.0,0.0) [0.0|255] ""  Vector__XXX
 SG_ HVLM_CJ_ProtokollVersionFzg : 156|24@1+ (1,0) [0|1] "Unit_None"  Vector__XXX
 SG_ HVLM_CJ_LadebereitschaftFzg : 180|8@1+ (1.0,0.0) [0.0|255] ""  Vector__XXX
 SG_ HVLM_CJ_StatusProtokollVerh : 188|8@1+ (1.0,0.0) [0.0|255] ""  Vector__XXX
 SG_ HVLM_CJ_MaxLadestromFzg : 196|16@1+ (0.1,0) [0.0|6553.3] "Unit_Amper"  Vector__XXX
 SG_ HVLM_CJ_SollspannungFzg : 212|16@1+ (0.1,0) [0.0|6553.3] "Unit_Volt"  Vector__XXX
 SG_ HVLM_CJ_MaxLadeernergieFzg : 228|16@1+ (0.1,0) [0.0|1000.0] "Unit_KiloWattHour"  Vector__XXX
 SG_ HVLM_CJ_IstSpannungFzg : 244|16@1+ (0.1,0) [0.0|6553.3] "Unit_Volt"  Vector__XXX
 SG_ HVLM_CJ_MaxLadspannungFzg : 260|16@1+ (0.1,0) [0.0|6553.3] "Unit_Volt"  Vector__XXX
 SG_ HVLM_CJ_SollstromFzg : 276|16@1+ (0.1,0) [0.0|6553.3] "Unit_Amper"  Vector__XXX
 SG_ HVLM_CdoCj_S2UmschaltenAnf : 292|3@1+ (1.0,0.0) [0.0|7] ""  Vector__XXX
 SG_ HVLM_CJ_LadeendeTimeoutFzg : 296|8@1+ (1.0,0.0) [0.0|255] ""  Vector__XXX
 SG_ HVLM_CJ_LadeendeFehlerFzg : 304|8@1+ (1.0,0.0) [0.0|255] ""  Vector__XXX
 SG_ HVLM_CJ_LadeendeFzg : 312|8@1+ (1.0,0.0) [0.0|255] ""  Vector__XXX

CM_ BO_ 253 "Neue Momente im MQB
Struktur ab MQB mit CRC8 entstanden aus ESP_01";
CM_ BO_ 888 "Nachricht 4 für Ortung:
Zeitstempel der Ortung.";
CM_ BO_ 1016 "Heizleistungsregelung 
MLBevo (NVEM im Gateway)";
CM_ BO_ 2463978708 "Gesendet vom HVLM";

CM_ SG_ 252 ESC_51_BZ "4bit Botschaftszähler, wird mit jeder Sendebotschaft inkrementiert";
CM_ SG_ 252 ESC_51_CRC "Für MLB:
Berechnung siehe Lastenheft 'Kommunikationsabsicherung für FlexRay und CAN'
Ab MQB und MLBevo:
Berechnung siehe Lastenheft 'End-to-End Kommunikationsabsicherung'

Endwerte siehe Begleitdokument 'S-PDU Kennungsfolgen'";
CM_ SG_ 252 ESC_Achsdrehzahl_Max "Limit Achsdrehzahl für die Primärachse";
CM_ SG_ 252 ESC_Achsdrehzahl_Max_sek "Limit Achsdrehzahl für die Sekundärachse";
CM_ SG_ 252 ESC_Achsdrehzahl_Min "Limit Achsdrehzahl für die Primärachse";
CM_ SG_ 252 ESC_Achsdrehzahl_Min_sek "Limit Achsdrehzahl für die Sekundärachse";
CM_ SG_ 252 ESC_aktBR_Modus_02 "Kontext des Signals ESC_aktBr_Modus_02:
0: AktivBremsung per eBKV nicht aktiv
1: ESC fordert eine schnelle Initialisierung vom eBKV beim Wecken
2: Aktivbremsung per eBKV aktiv
3: Aktivbremsung per eBKV aktiv ohne Begrenzung durch 'Fahrer bremst' Erken";
CM_ SG_ 252 ESC_aktBr_Volumenstrom "Volumenstromvorgabe für Aktivbremsung per eBKV,
Kontext des Volumenstroms wird im Signal ESC_aktBr_Modus übertragen";
CM_ SG_ 252 ESC_Allrad_Anteil_max_sek "Maximaler prozentualer Anteil der sekundären Antriebsachse am Gesamtmoment - wird soweit dies durch die Leistungsfähigkeit der Achse möglich ist eingehalten";
CM_ SG_ 252 ESC_Allrad_Anteil_min_sek "Minimaler prozentualer Anteil der sekundären Antriebsachse am Gesamtmoment - wird soweit dies durch die Leistungsfähigkeit der Achse möglich ist eingehalten";
CM_ SG_ 252 ESC_Allradverteilung_aktiv "Allradumverteilung aus BRS aktiv und vom ASG umzusetzen";
CM_ SG_ 252 ESC_Anf_Mindestreku "Bei Wert == 1 soll durch den Antrieb eine im Projekt definierte Mindestrekuperationsleistung des E-Antriebs zur Anforderung durch das Bremssystem schnellst möglich frei gegeben werden. Dies dient zur Entlastung der Reibbremse.";
CM_ SG_ 252 ESC_Blending_Solldruck "Zieldruck während Rekuperation. Das Signal ist spezifisch aufbereitet und wird für die Pedakraftkompensation im eBKV genutzt.

MQB/MQB2020: Wird nur von einem blendfähigen ESC unterstützt, wie es in mHEV und pHEV Fahrzeugen eingesetzt wird.";
CM_ SG_ 252 ESC_Bremsdruck_02 "Rohwert des Bremsdrucks
Für Fahrzeuge mit elektrischem Bremskraftverstärker gilt: Aus dem Signal ESC_Bremsdruck_02 lässt sich kein Fahrerbremswunsch ableiten. Das Signal bildet lediglich den hydraulischen Anteil der Fahrzeugverzögerung ab. Der Rohwert de";
CM_ SG_ 252 ESC_Bremsdruck_Modell "Virtueller, aus dem Wert 'EBKV_Stangenweg_Fahrerwunsch' berechneter Hauptzylinderdruck. Während einer hydraulischen Bremsung entspricht dieser Druck nahezu dem 'ESC_Bremsdruck_02'. Während einer Bremsung mit Rekuperation ist es ein berechneter Wert, der d";
CM_ SG_ 252 ESC_EBKV_Kraftblending_Modus "Freigabe der Pedalkraftkompensation (Funktion des eBKV)

MQB/MQB2020: Wird nur von einem blendfähigen ESC unterstützt, wie es in mHEV und pHEV Fahrzeugen eingesetzt wird.";
CM_ SG_ 252 ESC_GMV_aktiv "Rueckmeldung Giermomentvorgabe aktiv";
CM_ SG_ 252 ESC_GMV_nicht_verfuegbar "Rueckmeldung Giermomentvorgabe nicht verfuegbar";
CM_ SG_ 252 ESC_MomRad_Eingriff "Eingriffs-Momenten-Anforderung vom ESC an das ASG für die primäre Achse; auf Bezugsebene „Moment am Rad; Faktor in TS_Faktor_Radmomente beachten!";
CM_ SG_ 252 ESC_MomRad_Eingriff_sek "Eingriffs-Momenten-Anforderung vom ESC an das ASG für die sekundäre Achse; auf Bezugsebene „Moment am Rad; Faktor in TS_Faktor_Radmomente beachten! Signal ist nur relevant für mechanisch getrennte Achsantriebe (z. B. equattro)";
CM_ SG_ 252 ESC_QBit_Bremsdruck_02 "QBit des ESC_Bremsdruck_02. Gesetzt bei Ersatzwert, Init oder Fehler.";
CM_ SG_ 252 ESC_Status_Eingriff "Das Signal qualifiziert „ESC_MomRad_Eingriff“ und gibt an, wie dieses Signal umzusetzen ist";
CM_ SG_ 252 ESC_Status_Eingriff_sek "Das Signal qualifiziert „ESC_MomRad_Eingriff_sek“ und gibt an, wie dieses Signal umzusetzen ist";
CM_ SG_ 252 ESC_Status_vRef_Stuetzeingriff "Das Signal qualifiziert eine Momentenreduzierung an der Hinterachse zur Stützung der ESC Referenzgeschwindigkeit. Die Reduzierung erfolgt über die Signale ESC_MomRad_Eingriff bzw ESC_MomRad_Eingriff_sek";
CM_ SG_ 252 ESP_FDR_uebersteuern "Modularer Fahrdynamikregler erkennt Übersteuern.
Bei Integration modularer Fahrdynamikregler in ESC MEB: Verwendung durch eAllradfunktion in MSG.";
CM_ SG_ 252 ESP_FDR_untersteuern "Modularer Fahrdynamikregler erkennt Untersteuern.
Bei Integration modularer Fahrdynamikregler in ESC MEB: Verwendung durch eAllradfunktion in MSG.";
CM_ SG_ 252 ESP_FZR_uebersteuern "Fahrzeug erkennt uebersteuern";
CM_ SG_ 252 ESP_FZR_untersteuern "Fahrzeug erkennt untersteuern";
CM_ SG_ 252 ESP_HL_Bremsmoment "Bremsmoment HL
Ausgabe nach LAH: Ausgabe der internen Radbremsmomente / Radbremsdrücke / durch das ESP";
CM_ SG_ 252 ESP_HL_Radgeschw_02 "Radgeschwindigkeit hinten links";
CM_ SG_ 252 ESP_HR_Bremsmoment "Bremsmoment HR
Ausgabe nach LAH: Ausgabe der internen Radbremsmomente / Radbremsdrücke / durch das ESP";
CM_ SG_ 252 ESP_HR_Radgeschw_02 "Radgeschwindigkeit hinten rechts";
CM_ SG_ 252 ESP_VL_Bremsmoment "Bremsmoment VL
Ausgabe nach LAH: Ausgabe der internen Radbremsmomente / Radbremsdrücke / durch das ESP";
CM_ SG_ 252 ESP_VL_Radgeschw_02 "Radgeschwindigkeit vorne links";
CM_ SG_ 252 ESP_VR_Bremsmoment "Bremsmoment VR
Ausgabe nach LAH: Ausgabe der internen Radbremsmomente / Radbremsdrücke / durch das ESP";
CM_ SG_ 252 ESP_VR_Radgeschw_02 "Radgeschwindigkeit vorne rechts";
CM_ SG_ 252 FDR_Allradverteilung_aktiv "Allradumverteilung aus FDR aktiv und vom MSG umzusetzen";
CM_ SG_ 252 FDR_Anf_Allradbetrieb "Anforderung des Fahrdynamikreglers an MSG zur Aktivierung des Allradbetriebs.";
CM_ SG_ 252 SOK_ESC_51_Signatur "Signatur im Rahmen des SOK Authentic-Broadcast-Protokolls.

Geschützte Funktion: Lenkunterstützung
Geschützte Botschaft: ESC_51";
CM_ SG_ 252 TSMomBegrenzung "In MLBevo Faktor in TS_Faktor_Radmomente beachten!

Begrenzung des verzögernd wirkenden Antriebsstrangsollmomentenanteil auf Summenradebene";

CM_ SG_ 253 ABS_Bremsung "Antiblockiersystem, Bit zeigt auch Druckabbau an (z.B. ESP hat zuviel Druck aufgebaut oder ungebremste Regelung auf Bahnübergang)
Weiterführende Informationen im Lastenheft spezifiziert und in der entsprechenden Fachabteilung zu erfragen.";
CM_ SG_ 253 ASR_Anf "MLB: Die Momentenanforderung 'ASR_MSR_Moment_schnell' und 'ASR_Moment_langsam' sind auszuführen
MQB: Die Momentenanforderung 'BR_Eingriffsmoment' ist auszuführen";
CM_ SG_ 253 ASR_Schalteingriff "Wunsch an das Getriebe während einer ASR Regelung

MLB: Es wird nur 0x0 und 0x1 genutzt

";
CM_ SG_ 253 ASR_Tastung_passiv "ASR deaktiviert oder Schwellen geändert (projektabhängig)
Weiterführende Informationen im Lastenheft spezifiziert und in der entsprechenden Fachabteilung zu erfragen.
";
CM_ SG_ 253 BR_Eingriffsmoment "Einheitenloser Wert! Faktor in MO_Faktor_Momente_02 in Motor_Code_01 beachten!
Schnelle reduzierende (ASR) oder erhöhende (MSR) Momentanforderung an den Motor.";
CM_ SG_ 253 EBV_Eingriff "Elektronische Bremskraftverteilung, aktueller Eingriff (Druckhalten, Druckabbau)

Im MLB: kein ABS / ESP-Eingriff ???";
CM_ SG_ 253 EDS_Eingriff "Elektronische Differentialsperre";
CM_ SG_ 253 ESC_Reku_Freigabe "Mit diesem Bit wird die Rekuperation im Motorsteuergerät erlaubt. Bei Ausfall ESC wird Rekuperation nicht freigegeben.

MQB/MQB2020: Wird nur von einem blendfähigen ESC unterstützt, wie es in mHEV und pHEV Fahrzeugen eingesetzt wird.";
CM_ SG_ 253 ESC_v_Signal_Qualifier_High_Low "Das Qualifizerungssignal ESC_v_Signal_Qualifier_High_Low gibt eine Information über die Güte der vom Bremsregelsystem ausgegebenen Geschwindigkeitsinformation 'mittlere Geschwindigkeit', wobei Vertrauensbereiche für das ausgegebene Geschwindigkeitssignal ";
CM_ SG_ 253 ESP_21_CRC "Für MLB:
'Berechnung siehe Lastenheft 'Kommunikationsabsicherung für FlexRay und CAN''

Ab MQB und MLBevo:
'Berechnung siehe Lastenheft 'End-to-End Kommunikationsabsicherung''

Endwerte siehe Begleitdokument 'S-PDU Kennungsfolgen'";
CM_ SG_ 253 ESP_Anhaltevorgang_ACC_aktiv "Zeigt an, ob ACC-Anhaltevorgang aktiv";
CM_ SG_ 253 ESP_ASP "MLB: Anhaenger-Stabilisierungs-Programm
MQB: Gespannstabilisierung";
CM_ SG_ 253 ESP_AWV3_Brems_aktiv "Teil-, Ziel- oder Notbremsung wird im ESP für AWV3 umgesetzt (das MSG nutzt diese Info für den Abwurf der GRA-Regelung).";
CM_ SG_ 253 ESP_Diagnose "MLB: Nach Diagnoseende wird ein SW-Reset ausgelöst welcher einen Kommunikatiosausfall für max. 150ms verursacht. Dies ist bei SG mit verschärfter Timeoutüberwachung (nicht nach Konzern-LH) zu beachten.

MQB: Weiterführende Informationen im Lastenheft sp";
CM_ SG_ 253 ESP_Eingriff "Eingriff des Fahrdynamikreglers";
CM_ SG_ 253 ESP_Haltebestaetigung "Rückmeldung vom ESP-SG, dass das Fahrzeug aufgrund einer externen Bremsanforderung (z. B. ACC, PLA, ANB, o. ä.) abgebremst wurde und im Stillstand gehalten wird.";
CM_ SG_ 253 ESP_MKB_Abbruch_Geschw "Im Falle einer Multikollisionsbremsung teilt das ESP den Abbruch der MKB aufgrund der unteren Geschwindigkeitsschwelle mit.";
CM_ SG_ 253 ESP_PLA_Bremseingriff "Signalisierung des aktiven Bremseingriffes des ESP aufgrund einer Bremsanforderung vom PLA.";
CM_ SG_ 253 ESP_QBit_v_Signal "Geschwindigkeit wird vom ABS/ASR oder ESP aus Ersatzwerten errechnet, wenn Bit gesetzt ist. Güte des Signals ist verändert.";
CM_ SG_ 253 ESP_Systemstatus "Fehler steht für Stillegung ESP mit Fehlereintrag.

MLB: Flag wird bei Unterspannung im Stand bis einmalig 6km/h (AU48x) oder 10 km/h (AU641, AU57x) überschritten nicht gesetzt (Ausblendung Startvorgang)
Im AU64x, AU57x gilt ESP D4 Funktionsanforderung";
CM_ SG_ 253 ESP_Tastung_passiv "ESP deaktiviert oder Schwellen geändert (projektabhängig)
Weiterführende Informationen im Lastenheft spezifiziert und in der entsprechenden Fachabteilung zu erfragen.";
CM_ SG_ 253 ESP_v_Signal "Geschwindigkeitssignal vom ABS/ASR oder ESP. Mittelwert der angetriebenen Räder.
Bei MSR oder ABS Eingriffen wird die ABS-Referenzgeschwindigkeit für >= 200ms eingespiegelt (Zeit wird mit Aktiv-Flanke der Funktionsbits getriggert)

MQB: Bei Frontantrie";
CM_ SG_ 253 ESP_Vorsteuerung "zur Unterscheidung zwischen ESP-Vorsteuermaßnahmen und ESP-Regeleingriffen";
CM_ SG_ 253 MSR_Anf "MLB: Die Momentenanforderung 'ASR_MSR_Moment_schnell' ist auszuführen.
MQB: Die Momentenanforderung 'BR_Eingriffsmoment' ist auszuführen";
CM_ SG_ 253 OBD_Schlechtweg "Für Ausblendung der Zündaussetzererkennung im Motorsteuergerät (Otto). Bit wird gesetzt, wenn Rad-Drehbeschleunigung im ESP > Grenzwert ist. Vorteil gegenüber Radgeschwindigkeiten, dass ESP alle 2 ms dynamisch die Rad-Drehbeschleunigung errechnet und dem ";

CM_ SG_ 2527679668 eTM_BMS_Pumpe1_Befuellung "Ansteuerung BMS Pumpe1 für Befüllung aktiv";
CM_ SG_ 2527679668 eTM_BMS_Pumpe1_SollAnsteuerung "Sollwert Ansteuerung BMS Pumpe1 für Befüllung";
CM_ SG_ 2527679668 eTM_BMS_Ventil1_Befuellung "Ansteuerung BMS Ventil1 für Befüllung";
CM_ SG_ 2527679668 eTM_BMS_Ventil2_Befuellung "Ansteuerung BMS Ventil2 für Befüllung";
CM_ SG_ 2527679668 eTM_Pumpe1_Status "Ansteuerung Pumpe 1 Kühlkreis HV Komponenten";
CM_ SG_ 2527679668 eTM_Pumpe1_Volumenstrom "Soll- Kühlwasservolumenstrom von Pumpe 1 Kühlkreis HV Komponenten";
CM_ SG_ 2527679668 eTM_Pumpe1_Volumenstromteilung "Volumenstrom Aufteilungsfaktor für den Hauptzweig in der Parallelschaltung nach der Pumpe 1 im Kühlkreis HV Komponenten.

Aufteilungsfaktor für den Zusatzzweig lässt sich durch '1.0 - Verteilungsfaktor Hauptzweig' bestimmen.

Rohwert 126: init
Rohwer";
CM_ SG_ 2527679668 eTM_Pumpe2_Status "Ansteuerung Pumpe 2 Kühlkreis HV Komponenten";
CM_ SG_ 2527679668 eTM_Pumpe2_Volumenstrom "Soll- Kühlwasservolumenstrom von Pumpe 2 Kühlkreis HV Komponenten";
CM_ SG_ 2527679668 eTM_Pumpe3_Status "Ansteuerung Pumpe NT1 (Kühlkreis NT Komponenten)";
CM_ SG_ 2527679668 eTM_Temperatur_1 "Wassertemperatur 1 Kühlkreis HV Komponenten";
CM_ SG_ 2527679668 eTM_Temperatur_2 "Wassertemperatur 2 Kühlkreis HV Komponenten";
CM_ SG_ 2527679668 eTM_Ventil1_Status "Ansteuerung NT2 Kuehler-Bypassventil im Kuehlkreis HV-Komponenten";
CM_ SG_ 2527679668 eTM_Ventil2_Status "Ansteuerung Heizkreisabsperrventil im Kühlkreis HT Kreis";
CM_ SG_ 2527679668 eTM_Ventil3_Status "Ansteuerung Getriebeölkühler-Absperrventil im Kühlkreis HT Kreis";

CM_ SG_ 2589283684 FoD_Transmission_Info "Mit dem Signal zeigt der FoD-Master allen FoD-Slaves den Beginn und das Ende eines Freischaltuebertragungszykluses (FS-ID-Zyklus) an.";
CM_ SG_ 2589283684 GRA_FoD_Status "Verortung des FOD-Slaves für die Funktion GRA erfolgt im Gateway. Signal übermittelt den FOD-Status an das MSG.";

CM_ SG_ 2549875526 FoD_Klima_Req_Data "FoD - Function On Demand
ISO-TP Datenkanal - FID2NA
Request Funktion 0x03 FoD-Master

FoD-Master an Klima";

CM_ SG_ 2550006598 FoD_Klima_Resp_Data "FoD - Function On Demand
ISO-TP Datenkanal - FID2NA
Response Knoten 0x46 Klima

Klima an FoD Master";

CM_ SG_ 888 GNSS_Nachrichtenpaket_ID4 "+1 für jedes neue Paket. Zyklische ID-Vergabe (Zähler). Zur Identifizierung zusammenhängender Nachrichten, die die Daten derselben GNSS-Ortung enthalten und somit zum selben Zyklus gehören. D.h. Daten in den Nachrichten wurden zur selben Zeit erzeugt. Der";
CM_ SG_ 888 GNSS_Ortung_Hoehe "Höhe über dem Meeresspiegel";
CM_ SG_ 888 GNSS_Ortung_Zeit_in_GPSWoche "Zeitstempel für die Jitter-Prüfung aso. Zeit muss sychron zur Zeit der GNSS-Ortung sein.";

CM_ SG_ 2463978722 GNSS_DR_Breite_Ortung "Dead Reckoning Breitengrad des Ortungsergebnisses nach WGS84 als Kombination von mehreren GNSSen";
CM_ SG_ 2463978722 GNSS_DR_Laenge_Ortung "Dead Reckoning Längengrad des Ortungsergebnisses nach WGS84 als Kombination von mehreren GNSSen";
CM_ SG_ 2463978722 GNSS_DR_Nachrichtenpaket_ID1 "+1 für jedes neue Paket. Zyklische ID-Vergabe (Zähler). Zur Identifizierung zusammenhängender Nachrichten, die die Daten derselben GNSS-Ortung enthalten und somit zum selben Zyklus gehören. D.h. Daten in den Nachrichten wurden zur selben Zeit erzeugt. Der";
CM_ SG_ 2463978722 GNSS_DR_Richtung_Breite_Ortung "Dead Reckoning Richtung des Breitengrads des Ortungsergebnisses nach WGS84 als Kombination von mehreren GNSSen";
CM_ SG_ 2463978722 GNSS_DR_Richtung_Laenge_Ortung "Dead Reckoning Richtung des Längengrads des Ortungsergebnisses nach WGS84 als Kombination von mehreren GNSSen";

CM_ SG_ 2463978723 GNSS_DR_Nachrichtenpaket_ID2 "+1 für jedes neue Paket. Zyklische ID-Vergabe (Zähler). Zur Identifizierung zusammenhängender Nachrichten, die die Daten derselben GNSS-Ortung enthalten und somit zum selben Zyklus gehören. D.h. Daten in den Nachrichten wurden zur selben Zeit erzeugt. Der";
CM_ SG_ 2463978723 GNSS_DR_Ortung_2D_Geschw_u_Grund "Dead Reckoning Geschwindigkeit in m pro Sekunde";
CM_ SG_ 2463978723 GNSS_DR_Ortung_Ausrichtung "Dead Reckoning Ausrichtung (Kurswinkel) der GNSS-Messung";

CM_ SG_ 2463978726 GNSS_DR_UTC_Zeit "Dead Reckoning UTC-Zeit, Sekunden seit dem 01.01.1970 00:00";

CM_ SG_ 1410 HD_Bewegung_auf "Bewegung HD (öffnen)";
CM_ SG_ 1410 HD_Bewegung_zu "Bewegung HD (schließen)";
CM_ SG_ 1410 HD_Endstellung_oben "obere Endstellung HD
";
CM_ SG_ 1410 HD_Endstellung_unten "untere Endstellung HD";
CM_ SG_ 1410 HD_Innentaster_betaetigt "Betätigung Innentaster HD
";
CM_ SG_ 1410 HD_Position "HD Position von 0 bis 100 %";
CM_ SG_ 1410 HD_Rueckmeld_prog "Programmierung Endstellung HD 
";
CM_ SG_ 1410 HD_Taster_defekt "Anzeige ob Heckdeckeltaster defekt ist";
CM_ SG_ 1410 HD_UeKB_erkannt "Erkennung Einklemmschutz";
CM_ SG_ 1410 HD_Verr_Taster_betaetigt_inv "Inverses Bit (Fusi-Anforderung) Betätigung des Verriegelungstaster für Heckdeckel";
CM_ SG_ 1410 HD_Verriegelungstaster_betaetigt "Betätigung des Verriegelungstaster für Heckdeckel";
CM_ SG_ 1410 HD_ZZH_Schalter_S3 "Teilt den Zustand des Statusschalters in einer unidirektionalen ZZH mit.";
CM_ SG_ 1410 HDSG_Anf_Umluftklappe "Signal zur Ansteuerung der Umluftklappe Klima.";

CM_ SG_ 1016 HLR_FlHz_Freigabe_HL "Freigabe des NVEM für die Flächenheizung hinten links";
CM_ SG_ 1016 HLR_FlHz_Freigabe_HR "Freigabe des NVEM für die Flächenheizung hinten rechts";
CM_ SG_ 1016 HLR_FlHz_Freigabe_Ruhesitz "Freigabe des NVEM für die Flächenheizung des Ruhesitzes";
CM_ SG_ 1016 HLR_FlHz_Freigabe_VL "Freigabe des NVEM für die Flächenheizung vorne links";
CM_ SG_ 1016 HLR_FlHz_Freigabe_VR "Freigabe des NVEM für die Flächenheizung vorne rechts";
CM_ SG_ 1016 HLR_FSH_Freigabe "Freigabe des EEM für die Frontscheibenheizung";
CM_ SG_ 1016 HLR_HSH_Freigabe "Freigabe des EEM für die Heckscheibenheizung";
CM_ SG_ 1016 HLR_KRH_Freigabe_VL "Freigabe des EEM für die Kopfraumheizung vorne links";
CM_ SG_ 1016 HLR_KRH_Freigabe_VR "Freigabe des EEM für die Kopfraumheizung vorne rechts";
CM_ SG_ 1016 HLR_LRH_Freigabe "Freigabe für die Lenkradheizung";
CM_ SG_ 1016 HLR_PTC_Freigabe "Freigabe des elektrischen Energiemanagements für das gestufte/geregelte PTC";
CM_ SG_ 1016 HLR_PTC_linear_Freigabe "Freigabe des EEM für den linearen PTC-Zuheizer";
CM_ SG_ 1016 HLR_SIH_Freigabe_Fond "Freigabe des EM für Sitzheizungen hinten";
CM_ SG_ 1016 HLR_SIH_Freigabe_HL "Freigabe des EEM für die Sitzheizung hinten links";
CM_ SG_ 1016 HLR_SIH_Freigabe_HR "Freigabe des EEM für die Sitzheizung hinten rechts";
CM_ SG_ 1016 HLR_SIH_Freigabe_VL "Freigabe des EEM für die Sitzheizung vorne links";
CM_ SG_ 1016 HLR_SIH_Freigabe_VR "Freigabe des EEM für die Sitzheizung vorne rechts";
CM_ SG_ 1016 HLR_SIL_Freigabe_HL "Freigabe des EEM für die Sitzbelüftung hinten links";
CM_ SG_ 1016 HLR_SIL_Freigabe_HR "Freigabe des EEM für die Sitzlüftung hinten rechts";
CM_ SG_ 1016 HLR_SIL_Freigabe_VL "Freigabe des EEM für die Sitzlüftung Vorne Links";
CM_ SG_ 1016 HLR_SIL_Freigabe_VR "Freigabe des EEM für die Sitzlüftung vorne Rechts";
CM_ SG_ 1016 HLR_Sp_Heizung_Freigabe_BT "Freigabe der Außenspiegelheizung Beifahrerseite";
CM_ SG_ 1016 HLR_Sp_Heizung_Freigabe_FT "Freigabe des EEM für die Außenspiegelheizung rechtsFreigabe der Außenspiegelheizung Fahrerseite";
CM_ SG_ 1016 HLR_TCH_Freigabe "Freigabe des NVEM für den Thermocupholder";

CM_ SG_ 1452 HVEM_Energie_Klima_Vorgabe "HVEM-Energievorgabe für Klima-Vorkonditionierung";
CM_ SG_ 1452 HVEM_Energie_Klima_Vorgabe_HighR "Erweiterte Auflösung von 10Wh für Signal HVEM_Energie_Klima_Vorgabe.
Signalwert wird zu HVEM_Energie_Klima_Vorgabe Addiert";
CM_ SG_ 1452 HVEM_HV_Anf "HV Anforderung des HV Energiemanagements an das MSG";
CM_ SG_ 1452 HVEM_HVK_Aktivitaet "Dem HVEM sind HV-Komponenten zugeordnet.  Das HVEM übermittelt an den HVK ein 
Hochvolt –Aktivitätsstatus dieser HV-Komponenten.";
CM_ SG_ 1452 HVEM_IstLeistungNA "aktuelle Leistungsaufnahme der Nebenaggregate";
CM_ SG_ 1452 HVEM_IstStrom_HVVerbraucher "Iststromaufnahme der elektrischen Nebenaggregate aus dem HV Zwischenkreis";
CM_ SG_ 1452 HVEM_Leistung_Klima_Vorgabe "Leistungsvorgabe Thermo (für Kühlen und Heizen)";
CM_ SG_ 1452 HVEM_MO_MaxLeistungIgnoriert "Rueckmeldung des HVEM ob die vorgegebene MaxLeistung vom MSG eingehalten wird.";
CM_ SG_ 1452 HVEM_Nutzbare_Energie "Nutzbare Energie welche für Komfortfunktionen vom HVEM freigegeben wird.";
CM_ SG_ 1452 HVEM_NVEM_Leistungsvorgabe "Leistungsvorgabe des HVEM an das NVEM";
CM_ SG_ 1452 HVEM_Pruefpuls_Anf "Prüfpulsanforderung an den HV-Koordinator";

CM_ SG_ 1385 HVEM_Abschaltstatus "Status der Reduzierungsstufen der Klimakomponenten beim Laden

0 = 100% (keine Reduzierung)
1 = 75%
2 = 50%
3 = 25%
7 = Init";
CM_ SG_ 1385 HVEM_Anf_ReichweiteNV "Anforderung an NV-EM zur Erhöhung der Reichweite den Energieverbrauch auf der NV-Seite zu reduzieren.";
CM_ SG_ 1385 HVEM_Betriebsart "Information über die seitens HVEM aktive Betriebsart für die Leistungsverteilung";
CM_ SG_ 1385 HVEM_DCDC_Freigabe "Freigabe des DCDC wenn das Fzg nicht Fahrbereit ist.";
CM_ SG_ 1385 HVEM_FreigabeBattHeizung "Freigabe des HVEM für die Batterieheizung";
CM_ SG_ 1385 HVEM_FreigabeKlimatisierung "Klimatisierung freigeben";
CM_ SG_ 1385 HVEM_KlimaMaxHVStrom "Kommuniziert dem Klimasteuergerät den max. Aufnahmestrom";
CM_ SG_ 1385 HVEM_Ladesteckerentr_Anf "Anforderung Ladestecker entriegeln nach ZV Auf Befehl";
CM_ SG_ 1385 HVEM_Leistung_Bat_Kond_Vorgabe "elektr. Leistungsvorgabe Thermo Batterie";
CM_ SG_ 1385 HVEM_LeistungsAnf "Anforderung an NV-EM zur Erhöhung der Performance den Energieverbrauch auf der NV-Seite zu reduzieren.";
CM_ SG_ 1385 HVEM_MinLeistungNA_Anf "Leistungsanforderung des HVEM in Richtung Antrieb. Diese Leistung muss der Antrieb für hochpriorisierte HV-Funktionen vorhalten.";
CM_ SG_ 1385 HVEM_Nachlad_Status "Status der Umsetzung der Nachladeanforderung der NV-Seite.";
CM_ SG_ 1385 HVEM_Nachladen_Anf "Anforderung für HV Laden bei gestecktem Stecker und deaktivierter Ladeanforderung";
CM_ SG_ 1385 HVEM_NVLeistungEmpf "Maximaler Sollwert der aktuellen Leistung der NV-Seite des DCDC-Wandlers.";
CM_ SG_ 1385 HVEM_Text_1 "Meldung bei einem Anzeige SOC<10% ('Achtung Batterie laden. Funktionen eingeschränkt')";
CM_ SG_ 1385 HVEM_WunschLeistungNA_Anf "Niederpriorisierte Leistungsanforderung an das Antriebssystem.
Diese Wunsch-Leistung ist immer größer gleich der geforderten Min-Leistung.";
CM_ SG_ 1385 HVEM_ZusatzMinLeistungNA_Anf "Zusätzliche Leistungsanfrage des HVEM an das Antriebsystem in kritischen Energiezuständen für hoch priorisierte Systemanforderungen während der Fahrbereitschaft.";

CM_ SG_ 1283 HV_Bordnetz_aktiv "Signalisiert ein aktives Hochvoltbordnetz. Für die Belastbarkeit des HV-Netzes müssen Strom- bzw. Leistungsgrenzen eingehalten werden";
CM_ SG_ 1283 HV_Bordnetz_Fehler "Status ob im  HV-Netz ein Fehler detektiert wurde.";
CM_ SG_ 1283 HVK_01_CRC "Für MLB:
'Berechnung siehe Lastenheft 'Kommunikationsabsicherung für FlexRay und CAN''

Ab MQB und MLBevo:
'Berechnung siehe Lastenheft 'End-to-End Kommunikationsabsicherung''

Endwerte siehe Begleitdokument 'S-PDU Kennungsfolgen'";
CM_ SG_ 1283 HVK_AktiveEntladung_Anf "Anforderung zum aktiven Entladen des HV-Netzes, während der Abschaltung des HV-Netz.";
CM_ SG_ 1283 HVK_BMS_Sollmodus "Angeforderter Sollmodus der HV-Batterie:
0 : HV_Off                                
1 : HV_On (HS geschlossen)                
2 : nicht belegbar                        
3 : AC-Laden_erw (HS +AC_2-Schütze geschlossen)                         
4 : AC-";
CM_ SG_ 1283 HVK_DCDC_Sollmodus "angeforderte Soll-Betriebsart des DC/DC-Wandlers: 
0: Standby; Kommunikation aktiv
1: Zwischenkreis des HV-Netzes wird vorgeladen; HV-Netz wird aktiviert und darf nicht  
    belastet werden.
2: Tiefsetzen (HV --> BN 14,4V)
    Sollwertvorgabe projek";
CM_ SG_ 1283 HVK_EKK_Sollmodus "Sollmodus elektrischer Klimakompressor";
CM_ SG_ 1283 HVK_Gesamtst_Spgfreiheit "Status des HV-Systems";
CM_ SG_ 1283 HVK_HV_Netz_Warnungen "Anforderung Warnung/Fehler HV-System im Kombi
0: Keine Warnung/Init
1:Anforderung_Anzeige_Warnung_HV-Netz (gelbes Symbol)
2:Anforderung_Anzeige_Fehler_HV-Netz (rotes Symbol)
3:Anforderung_Anzeige_Warnung_Kein_Wiederstart_möglich";
CM_ SG_ 1283 HVK_HVEM_Freigabe "Der HVK gibt das HVEM frei, um das HV-Netz unter Einhaltung von Leistungsgrenzen in Anspruch zu nehmen.";
CM_ SG_ 1283 HVK_HVLM_Sollmodus "Angeforderter Sollmodus des Lademanagers.";
CM_ SG_ 1283 HVK_HVPTC_Sollmodus "Sollmodus HV-PTC
0 : keine Freigabe
1 : Freigabe
2 : Freigabe_ausgesetzt
3 : nicht belegbar
4 : nicht belegbar
5 : nicht belegbar
6 : nicht belegbar
7 : Init   (CAN-Initialisierung)   

Info: 'nicht belegbar' d.h. Sollmodus nicht relevant für HV";
CM_ SG_ 1283 HVK_Iso_Messung_Start "Anforderung an die isolationswiderstandsüberwachenden HV-Komponenten zur Durchführung der Isolations-Widerstandsmessung.";
CM_ SG_ 1283 HVK_Istmodus_Anf "HVK-Anforderung an alle HV-Komponenten deren Istmodus im schnellen Zyklus (Inhibitzeit) zu senden.";
CM_ SG_ 1283 HVK_Ladebereit "Information an das Lademanagement, dass das HV-System aus Sicht des HVKs bereitgestellt werden kann.";
CM_ SG_ 1283 HVK_Notabschaltung_Anf "Aufforderung zur schnellstmöglichen Abschaltung des HV-Netzes aufgrund HV-Sicherheit";
CM_ SG_ 1283 HVK_PPulsFreigabe "Prüfpuls-Freigabe seitens Hochvoltkoordinator";
CM_ SG_ 1283 HVK_TN1_Sollmodus "Angeforderter Sollmodus der Steuereinheit für das Schütze des Teilnetz1 'Ladepfad':
0 : HV_Off                                
1 : HV_On (Schütz geschlossen)                
2 : reserviert
3 : Init   (CAN-Initialisierung)";
CM_ SG_ 1283 HVK_Vorladung_aktiv "Systeminformation, dass aktiv vorgeladen wird";

CM_ SG_ 2331595857 HVK_BMS_DC_Ladeschuetze_Soll "Sollmodus DC-Ladeschütze";
CM_ SG_ 2331595857 HVK_BMS_Hauptschuetze_Soll "Sollmodus der Hauptschuetze";
CM_ SG_ 2331595857 HVK_DC_PruefpulsStatus "0 = DCDC Pruefpuls inaktiv
1 = DCDC stellt Pruefpuls ein
2 = DCDC Pruefspannung erreicht";

CM_ SG_ 1428 HVLM_Anzeigetexte "Anzeige einer offenen Ladedosenklappe";
CM_ SG_ 1428 HVLM_Bat_Konditionierung_Anf "Anforderung HV-Netz für Batteriekonditionierung (Motorsteuergerät aktiviert HV-Netz).";
CM_ SG_ 1428 HVLM_Bat_laden_aktiv "Anzeige ob die HV-Batterie geladen wird.";
CM_ SG_ 1428 HVLM_Fehler_Ladestecker "Fehler am Ladestecker erkannt";
CM_ SG_ 1428 HVLM_Fehler_Verriegelung "Fehler bei der Steckerverriegelung erkannt";
CM_ SG_ 1428 HVLM_FSH_Anf "Frontscheibenheizung anfordern";
CM_ SG_ 1428 HVLM_HSH_Anf "Heckscheibenheizung anfordern";
CM_ SG_ 1428 HVLM_HV_Anf "HV-Aktivierung Anforderung und Grund der Anforderung";
CM_ SG_ 1428 HVLM_HVEM_MaxLeistung "Maximal zulässige Leistung, die das HVEM vom Lader nutzen darf. Wenn das Fzg nicht über einen Lader mit dem AC Netz verbunden ist ist dieser Wert 0.";
CM_ SG_ 1428 HVLM_Klima_Temp "MLBevo: Gewünschte Innenraumtemperatur, auf die bei der Standklimatisierung geregelt werden soll.
MQB: Temperatur die vom Nutzer vorgewählt wurde (VW: low=15,5 °C/ high=30,0°C)";
CM_ SG_ 1428 HVLM_Ladeart "Anzeige, ob Strom in das Fzg. fließt und wofür er verwendet wird.";
CM_ SG_ 1428 HVLM_Lademodus_HV_Bat "Gibt den aktuell eingestellten Lademodus an.";
CM_ SG_ 1428 HVLM_Ladesystemhinweise "Anzeigen von Hinweisen zum Ladesystem.
Anzeigen, dass das Ladesystem defekt ist.";
CM_ SG_ 1428 HVLM_Langzeit_Laden "Anforderung den Ladezustand der HV-Batterie bis langen Standzeiten zu reduzieren";
CM_ SG_ 1428 HVLM_Restladezeit_HV_Bat_02 "Zeit, bis HV-Batterie vollständig geladen ist. Angabe in 5 Minuten Schritten. Maximum 42h 25Min";
CM_ SG_ 1428 HVLM_Standklima_Timer_Status "Signalisierung an das KBT ob mind. ein Timer zur Standklimatisierung programmiert ist";
CM_ SG_ 1428 HVLM_Status_Netz "Information, ob das Fahrzeug mit einem Stromnetz verbunden ist.";
CM_ SG_ 1428 HVLM_Stecker_Status "Status der Steckererkennung unabhängig vom Lademodus (AC oder DC)";
CM_ SG_ 1428 HVLM_VK_Anf "Anforderung des Konditionierungsmanagers (im Lademanager) zur Aktivierung der Vorkonditionierung Innenraum";
CM_ SG_ 1428 HVLM_VK_Modus "Übermittlung des aktuellen Konditionierungs-Status für HMI, Mobile Online Dienste";
CM_ SG_ 1428 HVLM_VK_STH_Einsatz "Auswahl der PHEV Standheizung";
CM_ SG_ 1428 HVLM_Warnmeldungen "Dieses Signal übermittelt Kundeninformationen vom HV-Laden zur Kombianzeige";

CM_ SG_ 2463978689 HVLM_BCAM_Aktiv "Dieses Signal gibt den Aktivierungsstatus des Battery Charging Care Modes an und gehört zum HV-Laden";
CM_ SG_ 2463978689 HVLM_BCCM_SoC "Dieser Parameter bestimmt die Ladeschwelle des Battery Charging Care Modes und gehört zum HV-Laden";
CM_ SG_ 2463978689 HVLM_BCCMKundenfreigabe_Status "Dieses Signal zeigt an, ob der Kunde der Konditionierung seiner HV-Batterie und der damit verbundenen Reduzierung deren Ladezustands zugestimmt hat.";
CM_ SG_ 2463978689 HVLM_FreigabeLeistungNebenverbr "gibt die Leistung an die durch das HVEM verteilt werden kann";
CM_ SG_ 2463978689 HVLM_IstKonsWunschHVBat "Dieses Signal zeigt an, ob der Kunde wünscht, dass die HV-Batterie für eine lange Standzeit auf einen sehr batterieschonenden Ladezustand entladen wird.";
CM_ SG_ 2463978689 HVLM_IstStrom_02 "Momentaner Ladestrom unabhängig vom Lademodus (AC oder DC) in 0,1A";
CM_ SG_ 2463978689 HVLM_SollSoCKonservierung "Dieser Parameter bestimmt den Ladezustand, auf den die HV-Batterie entladen wird, wenn der Kunde die Konservierung für eine sehr lange Standzeit wünscht.";

CM_ SG_ 625 HVLM_13_BZ "4bit Botschaftszähler, wird mit jeder Sendebotschaft inkrementiert";
CM_ SG_ 625 HVLM_13_CRC "Für MLB:
Berechnung siehe Lastenheft 'Kommunikationsabsicherung für FlexRay und CAN'
Ab MQB und MLBevo:
Berechnung siehe Lastenheft 'End-to-End Kommunikationsabsicherung'

Endwerte siehe Begleitdokument 'S-PDU Kennungsfolgen'";
CM_ SG_ 625 HVLM_CP_Fehlerzustand_A "Fehler in der CP-Kommunikation";
CM_ SG_ 625 HVLM_CP_Fehlerzustand_B "Fehler in der CP-Kommunikation";
CM_ SG_ 625 HVLM_CP_KommProtokoll_A "Kommunikationsart vom CP signalisiert";
CM_ SG_ 625 HVLM_CP_KommProtokoll_B "Kommunikationsart vom CP signalisiert";
CM_ SG_ 625 HVLM_CP_MaxStrom_A "maximaler AC-Aufnahmestrom, durch die Ladesäule vorgegeben";
CM_ SG_ 625 HVLM_CP_MaxStrom_B "maximaler AC-Aufnahmestrom, durch die Ladesäule vorgegeben";
CM_ SG_ 625 HVLM_CP_State_A "Zustand der CP-Kommunikation der Ladedose A";
CM_ SG_ 625 HVLM_CP_State_B "Zustand der CP-Kommunikation der Ladedose B";
CM_ SG_ 625 HVLM_DC_SollStrom "Sollstromanforderung für DC-Laden
0.. 160A";
CM_ SG_ 625 HVLM_elektrLk_Kommandierung_Lk1 "Ansteuerung der elektrischen Ladeklappe.";
CM_ SG_ 625 HVLM_elektrLk_Kommandierung_Lk2 "Ansteuerung der elektrischen Ladeklappe.";
CM_ SG_ 625 HVLM_elektrLk_Kommandierung_Lk3 "Ansteuerung der elektrischen Ladeklappe. Suffix 3 bezieht sich auf virtuelle Ladeklappe 3, welche die zweite Ladeklappe bei einer Ansteuerung beider Ladeklappen durch ein Steuergerät ist.";
CM_ SG_ 625 HVLM_LadedosenSuchlicht "Signal zur Ansteuerung des Suchlichtes in der Ladedose";
CM_ SG_ 625 HVLM_Ladeklappe_VerEntriegeAnf_1 "Anforderung die Ladeklappe der Ladedose 1 zu verriegeln oder zu entriegeln.";
CM_ SG_ 625 HVLM_Ladeklappe_VerEntriegeAnf_2 "Anforderung die Ladeklappe der Ladedose 2 zu verriegeln oder zu entriegeln.";
CM_ SG_ 625 HVLM_Ladeklappe_VerEntriegeAnf_3 "Anforderung die Ladeklappe der Ladedose 2 zu verriegeln oder zu entriegeln. Suffix 3 bezieht sich auf virtuelle Ladeklappe 3, welche die zweite Ladeklappe bei einer Ansteuerung beider Ladeklappen durch ein Steuergerät ist.";
CM_ SG_ 625 HVLM_Max_Strom_Netz_L1 "Gibt den maximal zulässigen Aufnahmestrom aus der Infrastruktur auf L1 an.";
CM_ SG_ 625 HVLM_Max_Strom_Netz_L2 "Gibt den maximal zulässigen Aufnahmestrom aus der Infrastruktur auf L2 an.";
CM_ SG_ 625 HVLM_Max_Strom_Netz_L3 "Gibt den maximal zulässigen Aufnahmestrom aus der Infrastruktur auf L3 an.";
CM_ SG_ 625 HVLM_MaxSpannung_OBG_HV "Maximal zulässige Ausgangsspannung des Onboardgleichrichters";
CM_ SG_ 625 HVLM_OBG_SollModus "Anforderung des Sollmodus an das Ladegerät.";
CM_ SG_ 625 HVLM_ReversierenFreigabe_Lk1 "Gibt an, ob eine Reversierung der elektrischen Ladeklappe erlaubt ist.";
CM_ SG_ 625 HVLM_ReversierenFreigabe_Lk2 "Gibt an, ob eine Reversierung der elektrischen Ladeklappe erlaubt ist.";
CM_ SG_ 625 HVLM_ReversierenFreigabe_Lk3 "Gibt an, ob eine Reversierung der elektrischen Ladeklappe erlaubt ist. Suffix 3 bezieht sich auf virtuelle Ladeklappe 3, welche die zweite Ladeklappe bei einer Ansteuerung beider Ladeklappen durch ein Steuergerät ist.";
CM_ SG_ 625 HVLM_S2SchliessenAnf_A "Anforderung zum Öffnen/Schliessen des Schalters S2 am ControlPilot Pin am Verbauort A
0= oeffnen
1= schliessen";
CM_ SG_ 625 HVLM_S2SchliessenAnf_B "Anforderung zum Öffnen/Schliessen des Schalters S2 am ControlPilot Pin am Verbauort B
0= oeffnen
1= schliessen";
CM_ SG_ 625 HVLM_SchnellladeVokoAuto_Anf "Dieses Signal dient zur Aktivierung der automatischen Batterievorkonditionierung vor Ladesäulenankunft und gehört zum HV-Laden. Die Batterievorkonditionierung bezieht sich auf den Fahrbetrieb.";
CM_ SG_ 625 HVLM_SchnellladeVokoManuell_Anf "Dieses Signal dient zur Aktivierung der manuellen Batterievorkonditionierung (Schnellladevorkonditonierung) vor Ladesäulenankunft und gehört zum HV-Laden. Die Batterievorkonditionierung bezieht sich auf den Fahrbetrieb.";
CM_ SG_ 625 HVLM_SF4OeffnenAnf_A "Anforderung zum Öffnen/Schliessen des Schalters SF4 am ControlPilot Pin am Verbauort A
0= schliessen
1= oeffnen";
CM_ SG_ 625 HVLM_SF4OeffnenAnf_B "Anforderung zum Öffnen/Schliessen des Schalters SF4 am ControlPilot Pin am Verbauort B
0= schliessen
1= oeffnen";
CM_ SG_ 625 HVLM_Stecker_Notentriegeln_Anf_A "Anforderung zur Notentriegelung des Ladesteckers in Ladedose A";
CM_ SG_ 625 HVLM_Stecker_Notentriegeln_Anf_B "Anforderung zur Notentriegelung des Ladesteckers in Ladedose B";
CM_ SG_ 625 HVLM_Stecker_Notentriegeln_Anf_C "Anforderung zur Notentriegelung des Ladesteckers in Ladedose C";
CM_ SG_ 625 HVLM_Stecker_VerEntriegelnAnf_A "Anforderung Ladestecker zu verriegeln für Ladedose A";
CM_ SG_ 625 HVLM_Stecker_VerEntriegelnAnf_B "Anforderung Ladestecker zu verriegeln für Ladedose B";
CM_ SG_ 625 HVLM_Stecker_VerEntriegelnAnf_C "Anforderung Ladestecker zu verriegeln fuer Ladedose C";
CM_ SG_ 625 LVB_Ladegeschw "Gibt die Geschwindigkeit des Ladevorgangs an. Einheit siehe Signal LVB_LadegeschwEinheit.";
CM_ SG_ 625 LVB_Ladegeschw_VZ "Vorzeichen Bit zur Wertebereichseinstellung des Signals LVB_Ladegeschw. Als Hilfsgröße zur Umschaltung in einen positiven oder negativen Wertebereich";
CM_ SG_ 625 LVB_LadegeschwEinheit "Einheit der Ladegeschwindigkeit";
CM_ SG_ 625 LVB_Restladezeit "Restladezeit des Ladevorgangs bis gewünschter Ladezustand erreicht ist.";
CM_ SG_ 625 LVB_StatusLadegeschw "Gibt Informationen über die Gültigkeit der Ladegeschwindigkeit.";
CM_ SG_ 625 LVB_StatusRestladezeit "Gibt Informationen über die Gültigkeit der Restladezeit.";

CM_ SG_ 805 SOK_HVLM_13_Signatur "Signatur im Rahmen der durch SOK geschützen Broadcast-Kommunikation

Geschützte Funktion: HV-Laden
Geschützte Signale: HVLM_DC_SollStrom
Geschützte Botschaft: HVLM_13";

CM_ SG_ 626 HVLM_Aktive_Ladeart "informs about the used charging infrastructure - AC - DC - AWC.";
CM_ SG_ 626 HVLM_Anforderung_HMS "Anforderung zur Verriegelung des Triebstrangs";
CM_ SG_ 626 HVLM_AWC_VerbautStatus "Verbausignalisierung vom HVLM der optionalen Komponente AWC";
CM_ SG_ 626 HVLM_DC_Aufstartmodus "Aufstartmodus zum Aktivieren des HV-Modus für DC-Laden";
CM_ SG_ 626 HVLM_Intensitaet_Lk1 "Über dieses Signal wird eine Information über die Beleuchtungsintensität an der LED der Ladeklappe 1 gesendet.";
CM_ SG_ 626 HVLM_Intensitaet_Lk2 "Über dieses Signal wird eine Information über die Beleuchtungsintensität an der LED der Ladeklappe 2 gesendet.";
CM_ SG_ 626 HVLM_Laden_ISO_Messung_Anf "Messung des Isolationswiderstandes des Ladesystems (Fzg und Ladesäule) während des Ladevorganges durch das Fahrzeug
0= Anforderung
1= keine_Anforderung";
CM_ SG_ 626 HVLM_Ladeszenario "Über dieses Signal wird das einzustellende Szenario für die Visualisierung gesendet.";
CM_ SG_ 626 HVLM_Ladevorgang_Anf "Art der angeforderten Ladeart 
0 = Laden_nicht_angefordert
1 = AC_Laden_Angefordert
2 = DC_Laden_Angefordert
3 = AC_und_DC_Angefordert
4 = Induktiv_Laden_Angef
5 = AC_und_Induktiv_Angef
6 = DC_und_Induktiv_Angef
7 = AC_DC_und_Induktiv_Angef";
CM_ SG_ 626 HVLM_Parken_beibehalten_HMS "Anforderung den Triebstrang verriegelt zu halten";
CM_ SG_ 626 HVLM_Pulsierstufe "Über dieses Signal wird eine Information über die Frequenz der Ladedosen LED bei verschiedenen Leuchtmustern gesendet.";
CM_ SG_ 626 HVLM_Start_Pulserkennung "Startanforderung für die Pulserkennung";
CM_ SG_ 626 HVLM_Steckerstatus_A "Gibt den Steckerstatus aus der Ladedose A an";
CM_ SG_ 626 HVLM_Steckerstatus_B "Gibt den Steckerstatus aus der Ladedose B an";
CM_ SG_ 626 HVLM_WakeUpZaehlerResetAnf "Dieses Signal kann den Wakeup-Verhinderungszähler zurücksetzen";
CM_ SG_ 626 HVLM_ZustandLadeablauf "Zustand im Ablauf des Ladevorganges
0 = Init
1 = Standby_Ladevorbedingungen erfuellt
2 = Standby_Ladevorbedingungen_nicht_erfuellt
3 = Fehler
4 = Laden_starten
5 = Laden_beenden
6 = HVBatterie_Laden
7 = HVBatterie_Entladen
8 = Erhaltungsladen";

CM_ SG_ 2463978708 HVLM_CDO_DynamischLaden_Status "Das Signal beschreibt, ob Fzg fähig ist, sich an verändertem Maxladestrom LS während des Ladens anpassen zu können (H'110.0.0)";
CM_ SG_ 2463978708 HVLM_CDO_Fehler_Fahrzeug "Anzeigen sonstiger Fehler die zum Ladeabbruch führen wenn die Normversion <=0.9 ist
0 = keine sonstigen Fehler
1 = Fehler
CAN ID (#102.5.2)";
CM_ SG_ 2463978708 HVLM_CDO_Fehler_HVBatSpgDiffFzg "Anzeige eines Fehlers aufgrund einer zu hohen Abweichung  zwischen Batterie-Istspannung und der Ladesäulen-IstSpannung über eine bestimmte Zeit 
0 = keine_Spannungsabweichung
1 = Spannungsabweichung
CAN ID (#102.4.4)";
CM_ SG_ 2463978708 HVLM_CDO_Fehler_HVBatUeberspgFzg "Anzeige eines Fehlers der zum Ladeabbruch führt.  
Batterie-Überspannung erkannt 
0 = keine Batterieüberspannung
1 = Batterieüberspannung
CAN ID (#102.4.0)";
CM_ SG_ 2463978708 HVLM_CDO_Fehler_HVBatUebertemp "Anzeige eines Fehlers aufgrund einer zu hohen Batterietemperatur
0 = keine_Batterieuebertemperatur
1 = Batterieuebertemperatur
CAN ID (#102.4.3)";
CM_ SG_ 2463978708 HVLM_CDO_Fehler_HVBatUnterspFzg "Anzeige eines Fehlers der zum Ladeabbruch führt. 
Batterie-Unterspannung erkannt
0 = keine Batterieunterspannung
1 = Batterieunterspannung
CAN ID (#102.4.1)";
CM_ SG_ 2463978708 HVLM_CDO_Fehler_HVStromDiffFzg "Anzeige eines Fehlers aufgrund einer zu hohen Abweichung  zwischen Batterie-Iststrom und Sollstromvorgabe des Fahrzeuges über eine bestimmte Zeit
0 = keine Batterie-Iststromabweichung
1 = Batterie-Iststromabweichung
CAN ID (#102.4.2)";
CM_ SG_ 2463978708 HVLM_CDO_GesamtKapazitaetHvBatt "wird benötigt, um den Wert an der Ladesäule anzuzeigen (Norm 1.1 ID: H’101.5, 101.6)";
CM_ SG_ 2463978708 HVLM_CDO_HvBatIstLadezustandFzg "aktueller Ladezustand der HV Batterie / Charged rate 
REV0.9:
aktueller Ladezustand als Energieinhalt
1 Bit = 0,1kWh
REV1.0:
aktueller Ladezustand in Prozent
1 Bit = 1%
CAN ID (#102.6)";
CM_ SG_ 2463978708 HVLM_CDO_HvMaxSpannungFzg "Maximale Ladespannung des Fahrzeugs die zum Beenden des Ladevorgangs führ (ID: H'100.4, 100.5)";
CM_ SG_ 2463978708 HVLM_CDO_HvMinSpannungFzg "Das Signal zeigt die minimale Ladespannnnung der Batterie (H'100.2, 100.3)";
CM_ SG_ 2463978708 HVLM_CDO_HvMinStromFzg "Minimale Stromanforderung an die Ladesäule, um Entladen der HV-Batterie zu vermeiden(Norm 1.1 ID: H‘100.0)
0=Leistung gleich 1,5 kW
1= keine Anforderung
2= 1A
…";
CM_ SG_ 2463978708 HVLM_CDO_LadebereitFzg "Status der Ladebereitschaft des Fahrzeugs
0 = keine Ladebereitschaft
1 = Ladebereitschaft
CAN ID (#102.5.0)";
CM_ SG_ 2463978708 HVLM_CDO_LadeerlaubnisLm "Melden der Ladebereitschaft des Fahrzeugs bei Chademo über Hardware Signal / Notify of completion of vehicle-side setup
0 = Laden nicht erlaubt
1 = Laden erlaubt
(Schalter k)";
CM_ SG_ 2463978708 HVLM_CDO_LadenBeendenAnfFzg "REV1.0:
Laden nicht anstarten bzw. normales Beenden anfordern
0 = keine Anforderung
1 = Beenden anfordern
CAN ID (#102.5.4)";
CM_ SG_ 2463978708 HVLM_CDO_LsNachrichtSendenAnf "Anforderung zur Start der CAN Kommunikation mit der Chademo Ladesäule
0 = Kein CAN-Kommunikation anfordern
1 = CAN-Kommunikation anfordern";
CM_ SG_ 2463978708 HVLM_CDO_MaxLadezeitFzg "Zur Ladesäule gesendete maximale Ladezeit in Sekunden des Fahrzeugs 
CAN ID (#101.1)";
CM_ SG_ 2463978708 HVLM_CDO_MaxLadezeitFzg_ext "Zur Ladesäule gesendete maximale erweiterte Ladezeit in Minuten des Fahrzeugs 
 CAN ID (#101.2)";
CM_ SG_ 2463978708 HVLM_CDO_ProtokollVersionFzg "CHAdeMO Protokoll- Version 
CAN ID (#102.0)";
CM_ SG_ 2463978708 HVLM_CDO_ReferenzLadezustandFzg "Referenz zum aktuellen Ladezustand des Fahrzeugs (Kundenladezustand)
REV0.9:
Gesamtladezustand als Energieinhalt
1 Bit = 0,1kWh
REV1.0:
Gesamtladezustand in Prozent
1 Bit = 1% (fest 100%)
CAN ID (#100.6)'";
CM_ SG_ 2463978708 HVLM_CDO_RestLadedauerFzg "REV1.0:
Verbleibende Zeit bis zum Ladeende
0 = Restladezeit nicht unterstützt
1 .. 255 = 0 .. 254min
CAN ID (#101.3)";
CM_ SG_ 2463978708 HVLM_CDO_SollStromFzg "Sollstromanforderung während des Ladevorgangs DC-Laden/ Charging current command value
(#102.3)";
CM_ SG_ 2463978708 HVLM_CDO_SollStromFzg_ext "Das Signal zeigt den Sollstrom an die Ladesäule (H'110.1, 110.2)";
CM_ SG_ 2463978708 HVLM_CDO_SpannungExt_Status "Das Signal beschreibt ob Fzg fähig ist, mit höherer Spannung zu laden (H'110.0.2)";
CM_ SG_ 2463978708 HVLM_CDO_Status_Fahrzeug "REV1.0:
HV-Schütz Status des Fahrzeugs bzw. 
0 = HV-Schütze geschlossen oder Welding Detection aktiv
1 = HV-Schütze offen oder Welding Detection beendet
CAN ID (#102.5.3)";
CM_ SG_ 2463978708 HVLM_CDO_SteckerVerEntr_Status "Zeigt den Status des Verriegelungsaktors des Steckers fuer die LS-Kommunikation bei ChaoJi-2";
CM_ SG_ 2463978708 HVLM_CDO_StromExt_Status "Das Signal beschreibt ob Fzg fähig ist, mit höherem Strom zu laden (H'110.0.1)";
CM_ SG_ 2463978708 HVLM_CDO_WahlhebelPosition_P_Fzg "Status ob sich der Wahlhebel für die Fahrstufe in der P Position (Parken) befindet
0 = Wahlhebel auf P (parken)
1 = Wahlhebel nicht auf P
CAN ID (#102.5.1)";
CM_ SG_ 2463978708 HVLM_CDO_ZielLadespannungFzg "Zielladespannung die zum Beenden des Ladevorgangs führt
CAN ID (#102.1, #102.2)";

CM_ SG_ 2331596000 HVLM_CdoCj_S2UmschaltenAnf "Das Signal fordert das Umschalten von S2 an";
CM_ SG_ 2331596000 HVLM_CdoCj_SvSchliessenAnf "Das Signal fordert das Oeffen oder Schliessen von Sv an";
CM_ SG_ 2331596000 HVLM_CdoCj_SvsSchliessenAnf "Das Signal fordert das Oeffen oder Schliessen von S2' an";
CM_ SG_ 2331596000 HVLM_CJ_01_Sendestatus "Gibt den Sendestatus der ChaoJi-1 Botschaft vom HVLM an (notwendig fuer IL-Unterstuetzung)";
CM_ SG_ 2331596000 HVLM_CJ_CanTypFzg "Das Signal gibt an, welche CAN Typ das Fahrzeug verwendet fuer Chaoji China";
CM_ SG_ 2331596000 HVLM_CJ_CheckcodeFzg "Gibt den Checkcode des Fahrzeugs an";
CM_ SG_ 2331596000 HVLM_CJ_FC1_FDC_Selection "Vom Fahrzeug ausgewaehlte FDC im FC1  (Authentication)";
CM_ SG_ 2331596000 HVLM_CJ_FC2_FDC_Selection "Vom Fahrzeug ausgewaehlte FDC im FC2 (Reservation)";
CM_ SG_ 2331596000 HVLM_CJ_FC3_FDC_Selection "Vom Fahrzeug ausgewaehlte FDC im FC3  (Selfcheck)";
CM_ SG_ 2331596000 HVLM_CJ_FC4_FDC_Selection "Vom Fahrzeug ausgewaehlte FDC im FC4  (Powersupplymode)";
CM_ SG_ 2331596000 HVLM_CJ_FC5_FDC_Selection "Vom Fahrzeug ausgewaehlte FDC im FC5  (Charging)";
CM_ SG_ 2331596000 HVLM_CJ_FC6_FDC_Selection "Vom Fahrzeug ausgewaehlte FDC im FC6  (End of Charging)";
CM_ SG_ 2331596000 HVLM_CJ_FCFDC_CheckFzg "Bestaetigung des Fahrzeugs fuer das naechste Funktionsmodul und Function Description Code der Ladesaeule";
CM_ SG_ 2331596000 HVLM_CJ_GrundLadeendeFzg "Das Signale gibt den Ladeendegrund des Fahrzeugs an";
CM_ SG_ 2331596000 HVLM_CJ_IstSOC "Das Signal gibt den aktuellen Ladezustnd im Laden an";
CM_ SG_ 2331596000 HVLM_CJ_IstSpannungFzg "Das Signal gibt die aktuelle Spannung der Batterie an";
CM_ SG_ 2331596000 HVLM_CJ_LadebereitschaftFzg "Das Signal zeigt, ob das Fahrzeug bereit fuers Laden ist";
CM_ SG_ 2331596000 HVLM_CJ_LadeendeFehlerFzg "Das Signal gibt den Ladeendegrund für fehlgeschlagene Funktionsmodule des Fahrzeugs an";
CM_ SG_ 2331596000 HVLM_CJ_LadeendeFzg "Das Signal gibt den Ladeendegrund für fehlgeschlagene Funktionsmodule des Fahrzeugs an";
CM_ SG_ 2331596000 HVLM_CJ_LadeendeTimeoutFzg "Das Signal gibt den Ladeendegrund für Timeout Funktionsmodule des Fahrzeugs an";
CM_ SG_ 2331596000 HVLM_CJ_Lademodus "Das Signal gibt den vom Fahrzeug ausgewaehlten Lademodus der Batterie (vor Ladebeginn) an";
CM_ SG_ 2331596000 HVLM_CJ_MaxLadeernergieFzg "Das Signal gibt die  maximale aufnimmbare Leistung des Fahrzug an";
CM_ SG_ 2331596000 HVLM_CJ_MaxLadestromFzg "Das Signal gibt den maximalen Ladestrom des Fahrzeugs an";
CM_ SG_ 2331596000 HVLM_CJ_MaxLadspannungFzg "Das Signal gibt die  maximale Ladespannung des Fahrzeugs an";
CM_ SG_ 2331596000 HVLM_CJ_PgiFzg "Das Signal kennzeichet die zu sendene Botschaft des Fahrzuegs fuer Chaoji China:";
CM_ SG_ 2331596000 HVLM_CJ_ProtokollVersionFzg "Das Signal beschreibt das Ergebnis der Versionverhandlung mit der Ladesaeule";
CM_ SG_ 2331596000 HVLM_CJ_Restladezeit "Das Signal zeigt die restliche Ladezeit bis gewuenschte Ladezsutand";
CM_ SG_ 2331596000 HVLM_CJ_SendeAnf_ACK "Das Signal fordert Senden von ACK Message an";
CM_ SG_ 2331596000 HVLM_CJ_SendeAnf_EndACK "Das Signal fordert das Senden von EndACK (bei long message) an";
CM_ SG_ 2331596000 HVLM_CJ_SendeAnf_LongMessage "Das Signal fordert Senden von LM (long message) Signale an";
CM_ SG_ 2331596000 HVLM_CJ_SendeAnf_Pausieren "Das Signal fordert Kommunikationspause an";
CM_ SG_ 2331596000 HVLM_CJ_SendeAnf_SMRM "Das Signal fordert Senden von SMRM (short message reliable message) an";
CM_ SG_ 2331596000 HVLM_CJ_SendeAnf_SMURM "Das Signal fordert Senden von SMURM (short message unreliable message) an";
CM_ SG_ 2331596000 HVLM_CJ_SendeAnf_Stoppen "Das Signal fordert Kommunikationsende";
CM_ SG_ 2331596000 HVLM_CJ_SollspannungFzg "Das Signal zeigt die Sollspannung des Ladevorgangs";
CM_ SG_ 2331596000 HVLM_CJ_SollstromFzg "Das Signal zeigt den Sollstrom des Ladevorgangs";
CM_ SG_ 2331596000 HVLM_CJ_StatusProtokollVerh "Status der Versionsverhandelung fuer Chaoji China";
CM_ SG_ 2331596000 HVLM_CJ_SteckerVerEntr_Status "Zeigt den Status des Verriegelungsaktors des Steckers fuer die LS-Kommunikation bei ChaoJi-1";
CM_ SG_ 2331596000 HVLM_CJ_VerbindungAnf "Das Signal fordert eine Verbindungsaufbau der Kommunikation an";
BA_DEF_REL_ BU_SG_REL_  "GenSigTimeoutTime" INT 0 65535;
BA_DEF_ BO_  "DiagRequest" ENUM "No", "Yes";
BA_DEF_ BO_  "DiagResponse" ENUM "No", "Yes";
BA_DEF_ BO_  "DiagState" ENUM "No", "Yes";
BA_DEF_ BO_  "GenMsgChkConstant" HEX 0 4095;
BA_DEF_ BO_  "GenMsgCycleTime" INT 0 65535;
BA_DEF_ BO_  "GenMsgCycleTimeFast" INT 0 65535;
BA_DEF_ BO_  "GenMsgDelayTime" INT 0 100000;
BA_DEF_ BO_  "GenMsgILSupport" ENUM "No", "Yes";
BA_DEF_ BO_  "GenMsgNrOfRepetition" INT 0 100;
BA_DEF_ BO_  "GenMsgPDUConstants" STRING;
BA_DEF_ BO_  "GenMsgSendType" ENUM "Cyclic", "not_used", "not_used", "not_used", "not_used", "not_used", "not_used", "IfActive", "NoMsgSendType";
BA_DEF_ BO_  "GenMsgStartDelayTime" INT 0 100000;
BA_DEF_ BO_  "NmMessage" ENUM "No", "Yes";
BA_DEF_ BO_  "NmhMessage" ENUM "No", "Yes";
BA_DEF_ BO_  "MsgType" ENUM "Application", "NM ", "NMH", "TP2.0", "ISO-TP ", "BAP", "EID", "KS", "XCP_PRE_CONFIGURED", "XCP_RUNTIME_CONFIGURED";
BA_DEF_ BO_  "VAGTP20_API" HEX 0 255;
BA_DEF_ BO_  "VAGTP20_DynConnection" ENUM "No", "Yes";
BA_DEF_ BO_  "VAGTP20_DynSetup" ENUM "No", "Yes";
BA_DEF_ BO_  "VAGTP20_StatConnection" ENUM "No", "Yes";
BA_DEF_ BO_  "CANFD_BRS" ENUM "0", "1";
BA_DEF_ BO_  "VFrameFormat" ENUM "StandardCAN", "ExtendedCAN", "reserved", "reserved", "reserved", "reserved", "reserved", "reserved", "reserved", "reserved", "reserved", "reserved", "reserved", "reserved", "StandardCAN_FD", "ExtendedCAN_FD";
BA_DEF_ SG_  "GenSigActiveRepetitions" INT -2147483648 2147483647;
BA_DEF_ SG_  "GenSigInactiveValue" INT -2147483648 2147483647;
BA_DEF_ SG_  "GenSigSendType" ENUM "Cyclic", "OnWrite", "OnWriteWithRepetition", "OnChange", "OnChangeWithRepetition", "IfActive", "IfActiveWithRepetition", "NoSigSendType", "OnChangeAndIfActive", "OnChangeAndIfActiveWithRepetition";
BA_DEF_ SG_  "GenSigStartValue" INT -2147483648 2147483647;
BA_DEF_ SG_  "NWM-WakeupAllowed" ENUM "No", "Yes";
BA_DEF_ SG_  "GenSigFuncType" ENUM "NoFunction", "MsgCounter", "CRC-8", "XOR", "XOR-2", "DatedBit", "SW-Kl15", "CHK", "Constant", "Protocol", "CRC-8-SAE_J1850", "CRC-32", "DataLength", "DataID", "MsgCounter16", "SOK-Signatur", "Cluster";
BA_DEF_ SG_  "GenSigSwitchedByIgnition" ENUM "No", "Yes";
BA_DEF_ SG_  "Fehlerwert" HEX 0 2147483647;
BA_DEF_ SG_  "GenSigMissingSourceValue" HEX 0 2147483647;
BA_DEF_DEF_REL_  "GenSigTimeoutTime" 0;
BA_DEF_DEF_  "DiagRequest" "No";
BA_DEF_DEF_  "DiagResponse" "No";
BA_DEF_DEF_  "DiagState" "No";
BA_DEF_DEF_  "GenMsgChkConstant" 0;
BA_DEF_DEF_  "GenMsgCycleTime" 0;
BA_DEF_DEF_  "GenMsgCycleTimeFast" 0;
BA_DEF_DEF_  "GenMsgDelayTime" 0;
BA_DEF_DEF_  "GenMsgILSupport" "No";
BA_DEF_DEF_  "GenMsgNrOfRepetition" 0;
BA_DEF_DEF_  "GenMsgPDUConstants" "";
BA_DEF_DEF_  "GenMsgSendType" "NoMsgSendType";
BA_DEF_DEF_  "GenMsgStartDelayTime" 0;
BA_DEF_DEF_  "NmMessage" "No";
BA_DEF_DEF_  "NmhMessage" "No";
BA_DEF_DEF_  "MsgType" "Application";
BA_DEF_DEF_  "VAGTP20_API" 0;
BA_DEF_DEF_  "VAGTP20_DynConnection" "No";
BA_DEF_DEF_  "VAGTP20_DynSetup" "No";
BA_DEF_DEF_  "VAGTP20_StatConnection" "No";
BA_DEF_DEF_  "CANFD_BRS" "1";
BA_DEF_DEF_  "VFrameFormat" "StandardCAN";
BA_DEF_DEF_  "GenSigActiveRepetitions" 0;
BA_DEF_DEF_  "GenSigInactiveValue" 0;
BA_DEF_DEF_  "GenSigSendType" "NoSigSendType";
BA_DEF_DEF_  "GenSigStartValue" 0;
BA_DEF_DEF_  "NWM-WakeupAllowed" "No";
BA_DEF_DEF_  "GenSigFuncType" "NoFunction";
BA_DEF_DEF_  "GenSigSwitchedByIgnition" "Yes";
BA_DEF_DEF_  "Fehlerwert" 0;
BA_DEF_DEF_  "GenSigMissingSourceValue" 0;
BA_ "GenMsgCycleTime" BO_ 252 10;
BA_ "GenMsgILSupport" BO_ 252 1;
BA_ "GenMsgPDUConstants" BO_ 252 "0x69,0xdc,0xf9,0x64,0x6a,0xce,0x55,0x2c,0xc4,0x38,0x8f,0xd1,0xc6,0x43,0xb4,0xb1";
BA_ "GenMsgSendType" BO_ 252 0;
BA_ "VFrameFormat" BO_ 252 14;
BA_ "GenMsgCycleTime" BO_ 253 20;
BA_ "GenMsgILSupport" BO_ 253 1;
BA_ "GenMsgPDUConstants" BO_ 253 "0xb4,0xef,0xf8,0x49,0x1e,0xe5,0xc2,0xc0,0x97,0x19,0x3c,0xc9,0xf1,0x98,0xd6,0x61";
BA_ "GenMsgSendType" BO_ 253 0;
BA_ "VFrameFormat" BO_ 253 14;
BA_ "GenMsgCycleTime" BO_ 2527679668 500;
BA_ "GenMsgDelayTime" BO_ 2527679668 100;
BA_ "GenMsgILSupport" BO_ 2527679668 1;
BA_ "GenMsgSendType" BO_ 2527679668 0;
BA_ "VFrameFormat" BO_ 2527679668 15;
BA_ "GenMsgCycleTime" BO_ 2589283684 1000;
BA_ "GenMsgCycleTimeFast" BO_ 2589283684 100;
BA_ "GenMsgDelayTime" BO_ 2589283684 100;
BA_ "GenMsgILSupport" BO_ 2589283684 1;
BA_ "GenMsgNrOfRepetition" BO_ 2589283684 3;
BA_ "GenMsgSendType" BO_ 2589283684 0;
BA_ "VFrameFormat" BO_ 2589283684 15;
BA_ "MsgType" BO_ 2549875526 4;
BA_ "VFrameFormat" BO_ 2549875526 15;
BA_ "MsgType" BO_ 2550006598 4;
BA_ "VFrameFormat" BO_ 2550006598 15;
BA_ "GenMsgCycleTime" BO_ 888 1000;
BA_ "GenMsgILSupport" BO_ 888 1;
BA_ "GenMsgSendType" BO_ 888 0;
BA_ "VFrameFormat" BO_ 888 14;
BA_ "GenMsgCycleTime" BO_ 2463978722 100;
BA_ "GenMsgILSupport" BO_ 2463978722 1;
BA_ "GenMsgSendType" BO_ 2463978722 0;
BA_ "VFrameFormat" BO_ 2463978722 15;
BA_ "GenMsgCycleTime" BO_ 2463978723 100;
BA_ "GenMsgILSupport" BO_ 2463978723 1;
BA_ "GenMsgSendType" BO_ 2463978723 0;
BA_ "VFrameFormat" BO_ 2463978723 15;
BA_ "GenMsgCycleTime" BO_ 2463978726 100;
BA_ "GenMsgILSupport" BO_ 2463978726 1;
BA_ "GenMsgSendType" BO_ 2463978726 0;
BA_ "VFrameFormat" BO_ 2463978726 15;
BA_ "GenMsgCycleTime" BO_ 1410 200;
BA_ "GenMsgDelayTime" BO_ 1410 20;
BA_ "GenMsgILSupport" BO_ 1410 1;
BA_ "GenMsgSendType" BO_ 1410 0;
BA_ "VFrameFormat" BO_ 1410 14;
BA_ "GenMsgCycleTime" BO_ 1016 500;
BA_ "GenMsgDelayTime" BO_ 1016 50;
BA_ "GenMsgILSupport" BO_ 1016 1;
BA_ "GenMsgSendType" BO_ 1016 0;
BA_ "VFrameFormat" BO_ 1016 14;
BA_ "GenMsgCycleTime" BO_ 1452 100;
BA_ "GenMsgILSupport" BO_ 1452 1;
BA_ "GenMsgSendType" BO_ 1452 0;
BA_ "VFrameFormat" BO_ 1452 14;
BA_ "GenMsgCycleTime" BO_ 1385 500;
BA_ "GenMsgDelayTime" BO_ 1385 50;
BA_ "GenMsgILSupport" BO_ 1385 1;
BA_ "GenMsgSendType" BO_ 1385 0;
BA_ "VFrameFormat" BO_ 1385 14;
BA_ "GenMsgCycleTime" BO_ 1283 100;
BA_ "GenMsgDelayTime" BO_ 1283 10;
BA_ "GenMsgILSupport" BO_ 1283 1;
BA_ "GenMsgPDUConstants" BO_ 1283 "0xed,0xd6,0x96,0x63,0xa5,0x12,0xd5,0x9a,0x1e,0x0d,0x24,0xcd,0x8c,0xa6,0x2f,0x41";
BA_ "GenMsgSendType" BO_ 1283 0;
BA_ "VFrameFormat" BO_ 1283 14;
BA_ "GenMsgCycleTime" BO_ 2331595857 100;
BA_ "GenMsgDelayTime" BO_ 2331595857 10;
BA_ "GenMsgILSupport" BO_ 2331595857 1;
BA_ "GenMsgSendType" BO_ 2331595857 0;
BA_ "VFrameFormat" BO_ 2331595857 15;
BA_ "GenMsgCycleTime" BO_ 1428 500;
BA_ "GenMsgDelayTime" BO_ 1428 50;
BA_ "GenMsgILSupport" BO_ 1428 1;
BA_ "GenMsgSendType" BO_ 1428 0;
BA_ "VFrameFormat" BO_ 1428 14;
BA_ "GenMsgCycleTime" BO_ 2463978689 100;
BA_ "GenMsgILSupport" BO_ 2463978689 1;
BA_ "GenMsgSendType" BO_ 2463978689 0;
BA_ "VFrameFormat" BO_ 2463978689 15;
BA_ "GenMsgCycleTime" BO_ 625 100;
BA_ "GenMsgDelayTime" BO_ 625 10;
BA_ "GenMsgILSupport" BO_ 625 1;
BA_ "GenMsgPDUConstants" BO_ 625 "0x5f,0x18,0xf5,0x71,0x82,0x10,0x93,0x8d,0x4c,0xd7,0x6e,0xaa,0xd6,0xb0,0xb7,0x78";
BA_ "GenMsgSendType" BO_ 625 0;
BA_ "VFrameFormat" BO_ 625 14;
BA_ "GenMsgCycleTime" BO_ 805 100;
BA_ "GenMsgDelayTime" BO_ 805 10;
BA_ "GenMsgSendType" BO_ 805 0;
BA_ "VFrameFormat" BO_ 805 14;
BA_ "GenMsgCycleTime" BO_ 626 100;
BA_ "GenMsgDelayTime" BO_ 626 10;
BA_ "GenMsgILSupport" BO_ 626 1;
BA_ "GenMsgSendType" BO_ 626 0;
BA_ "VFrameFormat" BO_ 626 14;
BA_ "GenMsgCycleTime" BO_ 2463978708 1000;
BA_ "GenMsgCycleTimeFast" BO_ 2463978708 50;
BA_ "GenMsgILSupport" BO_ 2463978708 1;
BA_ "GenMsgNrOfRepetition" BO_ 2463978708 5;
BA_ "GenMsgSendType" BO_ 2463978708 0;
BA_ "VFrameFormat" BO_ 2463978708 15;
BA_ "GenMsgCycleTime" BO_ 2331596000 1000;
BA_ "GenMsgCycleTimeFast" BO_ 2331596000 50;
BA_ "GenMsgDelayTime" BO_ 2331596000 10;
BA_ "GenMsgILSupport" BO_ 2331596000 1;
BA_ "GenMsgNrOfRepetition" BO_ 2331596000 5;
BA_ "GenMsgPDUConstants" BO_ 2331596000 "0xa2,0xc6,0x6d,0x40,0xa3,0x32,0x7e,0xbe,0xa4,0xc7,0x0d,0x76,0x98,0x16,0xb0,0x17";
BA_ "GenMsgSendType" BO_ 2331596000 0;
BA_ "VFrameFormat" BO_ 2331596000 15;
BA_ "GenSigSendType" SG_ 252 ESC_51_BZ 0;
BA_ "GenSigFuncType" SG_ 252 ESC_51_BZ 1;
BA_ "GenSigSwitchedByIgnition" SG_ 252 ESC_51_BZ 0;
BA_ "GenSigSendType" SG_ 252 ESC_51_CRC 0;
BA_ "GenSigFuncType" SG_ 252 ESC_51_CRC 2;
BA_ "GenSigSwitchedByIgnition" SG_ 252 ESC_51_CRC 0;
BA_ "GenSigSendType" SG_ 252 ESC_Achsdrehzahl_Max 0;
BA_ "GenSigStartValue" SG_ 252 ESC_Achsdrehzahl_Max 16382;
BA_ "GenSigSwitchedByIgnition" SG_ 252 ESC_Achsdrehzahl_Max 0;
BA_ "Fehlerwert" SG_ 252 ESC_Achsdrehzahl_Max 16383;
BA_ "GenSigSendType" SG_ 252 ESC_Achsdrehzahl_Max_sek 0;
BA_ "GenSigStartValue" SG_ 252 ESC_Achsdrehzahl_Max_sek 16382;
BA_ "GenSigSwitchedByIgnition" SG_ 252 ESC_Achsdrehzahl_Max_sek 0;
BA_ "Fehlerwert" SG_ 252 ESC_Achsdrehzahl_Max_sek 16383;
BA_ "GenSigSendType" SG_ 252 ESC_Achsdrehzahl_Min 0;
BA_ "GenSigStartValue" SG_ 252 ESC_Achsdrehzahl_Min 16382;
BA_ "GenSigSwitchedByIgnition" SG_ 252 ESC_Achsdrehzahl_Min 0;
BA_ "Fehlerwert" SG_ 252 ESC_Achsdrehzahl_Min 16383;
BA_ "GenSigSendType" SG_ 252 ESC_Achsdrehzahl_Min_sek 0;
BA_ "GenSigStartValue" SG_ 252 ESC_Achsdrehzahl_Min_sek 16382;
BA_ "GenSigSwitchedByIgnition" SG_ 252 ESC_Achsdrehzahl_Min_sek 0;
BA_ "Fehlerwert" SG_ 252 ESC_Achsdrehzahl_Min_sek 16383;
BA_ "GenSigSendType" SG_ 252 ESC_aktBR_Modus_02 0;
BA_ "GenSigSwitchedByIgnition" SG_ 252 ESC_aktBR_Modus_02 0;
BA_ "GenSigSendType" SG_ 252 ESC_aktBr_Volumenstrom 0;
BA_ "GenSigStartValue" SG_ 252 ESC_aktBr_Volumenstrom 32256;
BA_ "GenSigSwitchedByIgnition" SG_ 252 ESC_aktBr_Volumenstrom 0;
BA_ "GenSigSendType" SG_ 252 ESC_Allrad_Anteil_max_sek 0;
BA_ "GenSigStartValue" SG_ 252 ESC_Allrad_Anteil_max_sek 510;
BA_ "GenSigSwitchedByIgnition" SG_ 252 ESC_Allrad_Anteil_max_sek 0;
BA_ "Fehlerwert" SG_ 252 ESC_Allrad_Anteil_max_sek 511;
BA_ "GenSigSendType" SG_ 252 ESC_Allrad_Anteil_min_sek 0;
BA_ "GenSigStartValue" SG_ 252 ESC_Allrad_Anteil_min_sek 510;
BA_ "GenSigSwitchedByIgnition" SG_ 252 ESC_Allrad_Anteil_min_sek 0;
BA_ "Fehlerwert" SG_ 252 ESC_Allrad_Anteil_min_sek 511;
BA_ "GenSigSendType" SG_ 252 ESC_Allradverteilung_aktiv 0;
BA_ "GenSigSwitchedByIgnition" SG_ 252 ESC_Allradverteilung_aktiv 0;
BA_ "GenSigSendType" SG_ 252 ESC_Anf_Mindestreku 0;
BA_ "GenSigSwitchedByIgnition" SG_ 252 ESC_Anf_Mindestreku 0;
BA_ "GenSigSendType" SG_ 252 ESC_Blending_Solldruck 0;
BA_ "GenSigStartValue" SG_ 252 ESC_Blending_Solldruck 1022;
BA_ "GenSigSwitchedByIgnition" SG_ 252 ESC_Blending_Solldruck 0;
BA_ "Fehlerwert" SG_ 252 ESC_Blending_Solldruck 1023;
BA_ "GenSigSendType" SG_ 252 ESC_Bremsdruck_02 0;
BA_ "GenSigStartValue" SG_ 252 ESC_Bremsdruck_02 100;
BA_ "GenSigSwitchedByIgnition" SG_ 252 ESC_Bremsdruck_02 0;
BA_ "Fehlerwert" SG_ 252 ESC_Bremsdruck_02 1023;
BA_ "GenSigSendType" SG_ 252 ESC_Bremsdruck_Modell 0;
BA_ "GenSigStartValue" SG_ 252 ESC_Bremsdruck_Modell 1022;
BA_ "GenSigSwitchedByIgnition" SG_ 252 ESC_Bremsdruck_Modell 0;
BA_ "Fehlerwert" SG_ 252 ESC_Bremsdruck_Modell 1023;
BA_ "GenSigSendType" SG_ 252 ESC_EBKV_Kraftblending_Modus 0;
BA_ "GenSigSwitchedByIgnition" SG_ 252 ESC_EBKV_Kraftblending_Modus 0;
BA_ "GenSigSendType" SG_ 252 ESC_GMV_aktiv 0;
BA_ "GenSigSwitchedByIgnition" SG_ 252 ESC_GMV_aktiv 0;
BA_ "GenSigSendType" SG_ 252 ESC_GMV_nicht_verfuegbar 0;
BA_ "GenSigSwitchedByIgnition" SG_ 252 ESC_GMV_nicht_verfuegbar 0;
BA_ "GenSigSendType" SG_ 252 ESC_MomRad_Eingriff 0;
BA_ "GenSigStartValue" SG_ 252 ESC_MomRad_Eingriff 8190;
BA_ "GenSigSwitchedByIgnition" SG_ 252 ESC_MomRad_Eingriff 0;
BA_ "Fehlerwert" SG_ 252 ESC_MomRad_Eingriff 8191;
BA_ "GenSigSendType" SG_ 252 ESC_MomRad_Eingriff_sek 0;
BA_ "GenSigStartValue" SG_ 252 ESC_MomRad_Eingriff_sek 8190;
BA_ "GenSigSwitchedByIgnition" SG_ 252 ESC_MomRad_Eingriff_sek 0;
BA_ "Fehlerwert" SG_ 252 ESC_MomRad_Eingriff_sek 8191;
BA_ "GenSigSendType" SG_ 252 ESC_QBit_Bremsdruck_02 0;
BA_ "GenSigStartValue" SG_ 252 ESC_QBit_Bremsdruck_02 1;
BA_ "GenSigSwitchedByIgnition" SG_ 252 ESC_QBit_Bremsdruck_02 0;
BA_ "GenSigSendType" SG_ 252 ESC_Status_Eingriff 0;
BA_ "GenSigSwitchedByIgnition" SG_ 252 ESC_Status_Eingriff 0;
BA_ "GenSigSendType" SG_ 252 ESC_Status_Eingriff_sek 0;
BA_ "GenSigSwitchedByIgnition" SG_ 252 ESC_Status_Eingriff_sek 0;
BA_ "GenSigSendType" SG_ 252 ESC_Status_vRef_Stuetzeingriff 0;
BA_ "GenSigSwitchedByIgnition" SG_ 252 ESC_Status_vRef_Stuetzeingriff 0;
BA_ "GenSigSendType" SG_ 252 ESP_FDR_uebersteuern 0;
BA_ "GenSigStartValue" SG_ 252 ESP_FDR_uebersteuern 254;
BA_ "GenSigSwitchedByIgnition" SG_ 252 ESP_FDR_uebersteuern 0;
BA_ "Fehlerwert" SG_ 252 ESP_FDR_uebersteuern 255;
BA_ "GenSigSendType" SG_ 252 ESP_FDR_untersteuern 0;
BA_ "GenSigStartValue" SG_ 252 ESP_FDR_untersteuern 254;
BA_ "GenSigSwitchedByIgnition" SG_ 252 ESP_FDR_untersteuern 0;
BA_ "Fehlerwert" SG_ 252 ESP_FDR_untersteuern 255;
BA_ "GenSigSendType" SG_ 252 ESP_FZR_uebersteuern 0;
BA_ "GenSigStartValue" SG_ 252 ESP_FZR_uebersteuern 254;
BA_ "NWM-WakeupAllowed" SG_ 252 ESP_FZR_uebersteuern 1;
BA_ "GenSigSwitchedByIgnition" SG_ 252 ESP_FZR_uebersteuern 0;
BA_ "Fehlerwert" SG_ 252 ESP_FZR_uebersteuern 255;
BA_ "GenSigMissingSourceValue" SG_ 252 ESP_FZR_uebersteuern 254;
BA_ "GenSigSendType" SG_ 252 ESP_FZR_untersteuern 0;
BA_ "GenSigStartValue" SG_ 252 ESP_FZR_untersteuern 254;
BA_ "NWM-WakeupAllowed" SG_ 252 ESP_FZR_untersteuern 1;
BA_ "GenSigSwitchedByIgnition" SG_ 252 ESP_FZR_untersteuern 0;
BA_ "Fehlerwert" SG_ 252 ESP_FZR_untersteuern 255;
BA_ "GenSigMissingSourceValue" SG_ 252 ESP_FZR_untersteuern 254;
BA_ "GenSigSendType" SG_ 252 ESP_HL_Bremsmoment 0;
BA_ "GenSigStartValue" SG_ 252 ESP_HL_Bremsmoment 254;
BA_ "Fehlerwert" SG_ 252 ESP_HL_Bremsmoment 255;
BA_ "GenSigSendType" SG_ 252 ESP_HL_Radgeschw_02 0;
BA_ "GenSigStartValue" SG_ 252 ESP_HL_Radgeschw_02 65534;
BA_ "GenSigSwitchedByIgnition" SG_ 252 ESP_HL_Radgeschw_02 0;
BA_ "Fehlerwert" SG_ 252 ESP_HL_Radgeschw_02 65535;
BA_ "GenSigSendType" SG_ 252 ESP_HR_Bremsmoment 0;
BA_ "GenSigStartValue" SG_ 252 ESP_HR_Bremsmoment 254;
BA_ "Fehlerwert" SG_ 252 ESP_HR_Bremsmoment 255;
BA_ "GenSigSendType" SG_ 252 ESP_HR_Radgeschw_02 0;
BA_ "GenSigStartValue" SG_ 252 ESP_HR_Radgeschw_02 65534;
BA_ "GenSigSwitchedByIgnition" SG_ 252 ESP_HR_Radgeschw_02 0;
BA_ "Fehlerwert" SG_ 252 ESP_HR_Radgeschw_02 65535;
BA_ "GenSigSendType" SG_ 252 ESP_VL_Bremsmoment 0;
BA_ "GenSigStartValue" SG_ 252 ESP_VL_Bremsmoment 254;
BA_ "Fehlerwert" SG_ 252 ESP_VL_Bremsmoment 255;
BA_ "GenSigSendType" SG_ 252 ESP_VL_Radgeschw_02 0;
BA_ "GenSigStartValue" SG_ 252 ESP_VL_Radgeschw_02 65534;
BA_ "GenSigSwitchedByIgnition" SG_ 252 ESP_VL_Radgeschw_02 0;
BA_ "Fehlerwert" SG_ 252 ESP_VL_Radgeschw_02 65535;
BA_ "GenSigSendType" SG_ 252 ESP_VR_Bremsmoment 0;
BA_ "GenSigStartValue" SG_ 252 ESP_VR_Bremsmoment 254;
BA_ "Fehlerwert" SG_ 252 ESP_VR_Bremsmoment 255;
BA_ "GenSigSendType" SG_ 252 ESP_VR_Radgeschw_02 0;
BA_ "GenSigStartValue" SG_ 252 ESP_VR_Radgeschw_02 65534;
BA_ "GenSigSwitchedByIgnition" SG_ 252 ESP_VR_Radgeschw_02 0;
BA_ "Fehlerwert" SG_ 252 ESP_VR_Radgeschw_02 65535;
BA_ "GenSigSendType" SG_ 252 FDR_Allradverteilung_aktiv 0;
BA_ "GenSigSwitchedByIgnition" SG_ 252 FDR_Allradverteilung_aktiv 0;
BA_ "GenSigSendType" SG_ 252 FDR_Anf_Allradbetrieb 0;
BA_ "GenSigSwitchedByIgnition" SG_ 252 FDR_Anf_Allradbetrieb 0;
BA_ "GenSigSendType" SG_ 252 SOK_ESC_51_Signatur 0;
BA_ "GenSigFuncType" SG_ 252 SOK_ESC_51_Signatur 15;
BA_ "GenSigSendType" SG_ 252 TSMomBegrenzung 0;
BA_ "GenSigStartValue" SG_ 252 TSMomBegrenzung 4094;
BA_ "GenSigSwitchedByIgnition" SG_ 252 TSMomBegrenzung 0;
BA_ "Fehlerwert" SG_ 252 TSMomBegrenzung 4095;
BA_ "GenSigSendType" SG_ 253 ABS_Bremsung 0;
BA_ "GenSigSwitchedByIgnition" SG_ 253 ABS_Bremsung 0;
BA_ "GenSigSendType" SG_ 253 ASR_Anf 0;
BA_ "GenSigSwitchedByIgnition" SG_ 253 ASR_Anf 0;
BA_ "GenSigSendType" SG_ 253 ASR_Schalteingriff 0;
BA_ "GenSigSwitchedByIgnition" SG_ 253 ASR_Schalteingriff 0;
BA_ "GenSigSendType" SG_ 253 ASR_Tastung_passiv 0;
BA_ "GenSigSwitchedByIgnition" SG_ 253 ASR_Tastung_passiv 0;
BA_ "GenSigSendType" SG_ 253 BR_Eingriffsmoment 0;
BA_ "GenSigStartValue" SG_ 253 BR_Eingriffsmoment 1022;
BA_ "GenSigSwitchedByIgnition" SG_ 253 BR_Eingriffsmoment 0;
BA_ "Fehlerwert" SG_ 253 BR_Eingriffsmoment 1023;
BA_ "GenSigSendType" SG_ 253 EBV_Eingriff 0;
BA_ "GenSigSwitchedByIgnition" SG_ 253 EBV_Eingriff 0;
BA_ "GenSigSendType" SG_ 253 EDS_Eingriff 0;
BA_ "GenSigSwitchedByIgnition" SG_ 253 EDS_Eingriff 0;
BA_ "GenSigSendType" SG_ 253 ESC_Reku_Freigabe 0;
BA_ "GenSigSwitchedByIgnition" SG_ 253 ESC_Reku_Freigabe 0;
BA_ "GenSigSendType" SG_ 253 ESC_v_Signal_Qualifier_High_Low 0;
BA_ "GenSigStartValue" SG_ 253 ESC_v_Signal_Qualifier_High_Low 6;
BA_ "GenSigSwitchedByIgnition" SG_ 253 ESC_v_Signal_Qualifier_High_Low 0;
BA_ "Fehlerwert" SG_ 253 ESC_v_Signal_Qualifier_High_Low 7;
BA_ "GenSigSendType" SG_ 253 ESP_21_BZ 0;
BA_ "GenSigFuncType" SG_ 253 ESP_21_BZ 1;
BA_ "GenSigSwitchedByIgnition" SG_ 253 ESP_21_BZ 0;
BA_ "GenSigSendType" SG_ 253 ESP_21_CRC 0;
BA_ "GenSigFuncType" SG_ 253 ESP_21_CRC 2;
BA_ "GenSigSwitchedByIgnition" SG_ 253 ESP_21_CRC 0;
BA_ "GenSigSendType" SG_ 253 ESP_Anhaltevorgang_ACC_aktiv 0;
BA_ "GenSigSwitchedByIgnition" SG_ 253 ESP_Anhaltevorgang_ACC_aktiv 0;
BA_ "GenSigSendType" SG_ 253 ESP_ASP 0;
BA_ "GenSigSwitchedByIgnition" SG_ 253 ESP_ASP 0;
BA_ "GenSigSendType" SG_ 253 ESP_AWV3_Brems_aktiv 0;
BA_ "GenSigSwitchedByIgnition" SG_ 253 ESP_AWV3_Brems_aktiv 0;
BA_ "GenSigSendType" SG_ 253 ESP_Diagnose 0;
BA_ "GenSigSwitchedByIgnition" SG_ 253 ESP_Diagnose 0;
BA_ "GenSigSendType" SG_ 253 ESP_Eingriff 0;
BA_ "GenSigSwitchedByIgnition" SG_ 253 ESP_Eingriff 0;
BA_ "GenSigSendType" SG_ 253 ESP_Haltebestaetigung 0;
BA_ "GenSigSwitchedByIgnition" SG_ 253 ESP_Haltebestaetigung 0;
BA_ "GenSigSendType" SG_ 253 ESP_MKB_Abbruch_Geschw 0;
BA_ "GenSigSwitchedByIgnition" SG_ 253 ESP_MKB_Abbruch_Geschw 0;
BA_ "GenSigSendType" SG_ 253 ESP_PLA_Bremseingriff 0;
BA_ "GenSigSwitchedByIgnition" SG_ 253 ESP_PLA_Bremseingriff 0;
BA_ "GenSigSendType" SG_ 253 ESP_QBit_v_Signal 0;
BA_ "GenSigStartValue" SG_ 253 ESP_QBit_v_Signal 1;
BA_ "GenSigSwitchedByIgnition" SG_ 253 ESP_QBit_v_Signal 0;
BA_ "GenSigSendType" SG_ 253 ESP_Systemstatus 0;
BA_ "GenSigSwitchedByIgnition" SG_ 253 ESP_Systemstatus 0;
BA_ "GenSigSendType" SG_ 253 ESP_Tastung_passiv 0;
BA_ "GenSigSwitchedByIgnition" SG_ 253 ESP_Tastung_passiv 0;
BA_ "GenSigSendType" SG_ 253 ESP_v_Signal 0;
BA_ "GenSigStartValue" SG_ 253 ESP_v_Signal 65534;
BA_ "GenSigSwitchedByIgnition" SG_ 253 ESP_v_Signal 0;
BA_ "Fehlerwert" SG_ 253 ESP_v_Signal 65535;
BA_ "GenSigMissingSourceValue" SG_ 253 ESP_v_Signal 65534;
BA_ "GenSigSendType" SG_ 253 ESP_Vorsteuerung 0;
BA_ "GenSigSwitchedByIgnition" SG_ 253 ESP_Vorsteuerung 0;
BA_ "GenSigSendType" SG_ 253 MSR_Anf 0;
BA_ "GenSigSwitchedByIgnition" SG_ 253 MSR_Anf 0;
BA_ "GenSigSendType" SG_ 253 OBD_QBit_Schlechtweg 0;
BA_ "GenSigStartValue" SG_ 253 OBD_QBit_Schlechtweg 1;
BA_ "GenSigSwitchedByIgnition" SG_ 253 OBD_QBit_Schlechtweg 0;
BA_ "GenSigSendType" SG_ 253 OBD_Schlechtweg 0;
BA_ "GenSigSwitchedByIgnition" SG_ 253 OBD_Schlechtweg 0;
BA_ "GenSigSendType" SG_ 2527679668 eTM_BMS_Pumpe1_Befuellung 0;
BA_ "GenSigSwitchedByIgnition" SG_ 2527679668 eTM_BMS_Pumpe1_Befuellung 0;
BA_ "GenSigSendType" SG_ 2527679668 eTM_BMS_Pumpe1_SollAnsteuerung 0;
BA_ "GenSigStartValue" SG_ 2527679668 eTM_BMS_Pumpe1_SollAnsteuerung 14;
BA_ "GenSigSwitchedByIgnition" SG_ 2527679668 eTM_BMS_Pumpe1_SollAnsteuerung 0;
BA_ "Fehlerwert" SG_ 2527679668 eTM_BMS_Pumpe1_SollAnsteuerung 15;
BA_ "GenSigSendType" SG_ 2527679668 eTM_BMS_Ventil1_Befuellung 0;
BA_ "GenSigSwitchedByIgnition" SG_ 2527679668 eTM_BMS_Ventil1_Befuellung 0;
BA_ "GenSigSendType" SG_ 2527679668 eTM_BMS_Ventil2_Befuellung 0;
BA_ "GenSigSwitchedByIgnition" SG_ 2527679668 eTM_BMS_Ventil2_Befuellung 0;
BA_ "GenSigSendType" SG_ 2527679668 eTM_Pumpe1_Status 3;
BA_ "GenSigStartValue" SG_ 2527679668 eTM_Pumpe1_Status 14;
BA_ "GenSigSwitchedByIgnition" SG_ 2527679668 eTM_Pumpe1_Status 0;
BA_ "Fehlerwert" SG_ 2527679668 eTM_Pumpe1_Status 15;
BA_ "GenSigSendType" SG_ 2527679668 eTM_Pumpe1_Volumenstrom 0;
BA_ "GenSigStartValue" SG_ 2527679668 eTM_Pumpe1_Volumenstrom 62;
BA_ "GenSigSwitchedByIgnition" SG_ 2527679668 eTM_Pumpe1_Volumenstrom 0;
BA_ "Fehlerwert" SG_ 2527679668 eTM_Pumpe1_Volumenstrom 63;
BA_ "GenSigSendType" SG_ 2527679668 eTM_Pumpe1_Volumenstromteilung 0;
BA_ "GenSigStartValue" SG_ 2527679668 eTM_Pumpe1_Volumenstromteilung 126;
BA_ "GenSigSwitchedByIgnition" SG_ 2527679668 eTM_Pumpe1_Volumenstromteilung 0;
BA_ "GenSigSendType" SG_ 2527679668 eTM_Pumpe2_Status 3;
BA_ "GenSigStartValue" SG_ 2527679668 eTM_Pumpe2_Status 14;
BA_ "GenSigSwitchedByIgnition" SG_ 2527679668 eTM_Pumpe2_Status 0;
BA_ "Fehlerwert" SG_ 2527679668 eTM_Pumpe2_Status 15;
BA_ "GenSigSendType" SG_ 2527679668 eTM_Pumpe2_Volumenstrom 0;
BA_ "GenSigStartValue" SG_ 2527679668 eTM_Pumpe2_Volumenstrom 62;
BA_ "GenSigSwitchedByIgnition" SG_ 2527679668 eTM_Pumpe2_Volumenstrom 0;
BA_ "Fehlerwert" SG_ 2527679668 eTM_Pumpe2_Volumenstrom 63;
BA_ "GenSigSendType" SG_ 2527679668 eTM_Pumpe3_Status 3;
BA_ "GenSigStartValue" SG_ 2527679668 eTM_Pumpe3_Status 14;
BA_ "GenSigSwitchedByIgnition" SG_ 2527679668 eTM_Pumpe3_Status 0;
BA_ "Fehlerwert" SG_ 2527679668 eTM_Pumpe3_Status 15;
BA_ "GenSigSendType" SG_ 2527679668 eTM_Temperatur_1 0;
BA_ "GenSigStartValue" SG_ 2527679668 eTM_Temperatur_1 254;
BA_ "GenSigSwitchedByIgnition" SG_ 2527679668 eTM_Temperatur_1 0;
BA_ "Fehlerwert" SG_ 2527679668 eTM_Temperatur_1 255;
BA_ "GenSigSendType" SG_ 2527679668 eTM_Temperatur_2 0;
BA_ "GenSigStartValue" SG_ 2527679668 eTM_Temperatur_2 254;
BA_ "GenSigSwitchedByIgnition" SG_ 2527679668 eTM_Temperatur_2 0;
BA_ "Fehlerwert" SG_ 2527679668 eTM_Temperatur_2 255;
BA_ "GenSigSendType" SG_ 2527679668 eTM_Ventil1_Status 3;
BA_ "GenSigStartValue" SG_ 2527679668 eTM_Ventil1_Status 6;
BA_ "GenSigSwitchedByIgnition" SG_ 2527679668 eTM_Ventil1_Status 0;
BA_ "Fehlerwert" SG_ 2527679668 eTM_Ventil1_Status 7;
BA_ "GenSigSendType" SG_ 2527679668 eTM_Ventil2_Status 3;
BA_ "GenSigStartValue" SG_ 2527679668 eTM_Ventil2_Status 6;
BA_ "GenSigSwitchedByIgnition" SG_ 2527679668 eTM_Ventil2_Status 0;
BA_ "Fehlerwert" SG_ 2527679668 eTM_Ventil2_Status 7;
BA_ "GenSigSendType" SG_ 2527679668 eTM_Ventil3_Status 3;
BA_ "GenSigStartValue" SG_ 2527679668 eTM_Ventil3_Status 6;
BA_ "GenSigSwitchedByIgnition" SG_ 2527679668 eTM_Ventil3_Status 0;
BA_ "Fehlerwert" SG_ 2527679668 eTM_Ventil3_Status 7;
BA_ "GenSigSendType" SG_ 2589283684 FoD_Transmission_Info 3;
BA_ "GenSigSwitchedByIgnition" SG_ 2589283684 FoD_Transmission_Info 0;
BA_ "GenSigSendType" SG_ 2589283684 GRA_FoD_Status 4;
BA_ "GenSigSwitchedByIgnition" SG_ 2589283684 GRA_FoD_Status 0;
BA_ "GenSigSendType" SG_ 2549875526 FoD_Klima_Req_Data 3;
BA_ "GenSigFuncType" SG_ 2549875526 FoD_Klima_Req_Data 9;
BA_ "GenSigSwitchedByIgnition" SG_ 2549875526 FoD_Klima_Req_Data 0;
BA_ "GenSigSendType" SG_ 2550006598 FoD_Klima_Resp_Data 3;
BA_ "GenSigFuncType" SG_ 2550006598 FoD_Klima_Resp_Data 9;
BA_ "GenSigSwitchedByIgnition" SG_ 2550006598 FoD_Klima_Resp_Data 0;
BA_ "GenSigSendType" SG_ 888 GNSS_Nachrichtenpaket_ID4 0;
BA_ "GenSigSwitchedByIgnition" SG_ 888 GNSS_Nachrichtenpaket_ID4 0;
BA_ "GenSigSendType" SG_ 888 GNSS_Ortung_Hoehe 0;
BA_ "GenSigStartValue" SG_ 888 GNSS_Ortung_Hoehe 4094;
BA_ "GenSigSwitchedByIgnition" SG_ 888 GNSS_Ortung_Hoehe 0;
BA_ "Fehlerwert" SG_ 888 GNSS_Ortung_Hoehe 4095;
BA_ "GenSigSendType" SG_ 888 GNSS_Ortung_Zeit_in_GPSWoche 0;
BA_ "GenSigStartValue" SG_ 888 GNSS_Ortung_Zeit_in_GPSWoche 1073741822;
BA_ "GenSigSwitchedByIgnition" SG_ 888 GNSS_Ortung_Zeit_in_GPSWoche 0;
BA_ "Fehlerwert" SG_ 888 GNSS_Ortung_Zeit_in_GPSWoche 1073741823;
BA_ "GenSigSendType" SG_ 2463978722 GNSS_DR_Breite_Ortung 0;
BA_ "GenSigStartValue" SG_ 2463978722 GNSS_DR_Breite_Ortung 134217726;
BA_ "GenSigSwitchedByIgnition" SG_ 2463978722 GNSS_DR_Breite_Ortung 0;
BA_ "Fehlerwert" SG_ 2463978722 GNSS_DR_Breite_Ortung 134217727;
BA_ "GenSigSendType" SG_ 2463978722 GNSS_DR_Laenge_Ortung 0;
BA_ "GenSigStartValue" SG_ 2463978722 GNSS_DR_Laenge_Ortung 268435454;
BA_ "GenSigSwitchedByIgnition" SG_ 2463978722 GNSS_DR_Laenge_Ortung 0;
BA_ "Fehlerwert" SG_ 2463978722 GNSS_DR_Laenge_Ortung 268435455;
BA_ "GenSigSendType" SG_ 2463978722 GNSS_DR_Nachrichtenpaket_ID1 0;
BA_ "GenSigSwitchedByIgnition" SG_ 2463978722 GNSS_DR_Nachrichtenpaket_ID1 0;
BA_ "GenSigSendType" SG_ 2463978722 GNSS_DR_Richtung_Breite_Ortung 0;
BA_ "GenSigStartValue" SG_ 2463978722 GNSS_DR_Richtung_Breite_Ortung 1;
BA_ "GenSigSwitchedByIgnition" SG_ 2463978722 GNSS_DR_Richtung_Breite_Ortung 0;
BA_ "GenSigSendType" SG_ 2463978722 GNSS_DR_Richtung_Laenge_Ortung 0;
BA_ "GenSigStartValue" SG_ 2463978722 GNSS_DR_Richtung_Laenge_Ortung 1;
BA_ "GenSigSwitchedByIgnition" SG_ 2463978722 GNSS_DR_Richtung_Laenge_Ortung 0;
BA_ "GenSigSendType" SG_ 2463978723 GNSS_DR_Nachrichtenpaket_ID2 0;
BA_ "GenSigSwitchedByIgnition" SG_ 2463978723 GNSS_DR_Nachrichtenpaket_ID2 0;
BA_ "GenSigSendType" SG_ 2463978723 GNSS_DR_Ortung_2D_Geschw_u_Grund 0;
BA_ "GenSigStartValue" SG_ 2463978723 GNSS_DR_Ortung_2D_Geschw_u_Grund 510;
BA_ "GenSigSwitchedByIgnition" SG_ 2463978723 GNSS_DR_Ortung_2D_Geschw_u_Grund 0;
BA_ "Fehlerwert" SG_ 2463978723 GNSS_DR_Ortung_2D_Geschw_u_Grund 511;
BA_ "GenSigSendType" SG_ 2463978723 GNSS_DR_Ortung_Ausrichtung 0;
BA_ "GenSigStartValue" SG_ 2463978723 GNSS_DR_Ortung_Ausrichtung 4094;
BA_ "GenSigSwitchedByIgnition" SG_ 2463978723 GNSS_DR_Ortung_Ausrichtung 0;
BA_ "Fehlerwert" SG_ 2463978723 GNSS_DR_Ortung_Ausrichtung 4095;
BA_ "GenSigSendType" SG_ 2463978726 GNSS_DR_UTC_Zeit 0;
BA_ "GenSigSwitchedByIgnition" SG_ 2463978726 GNSS_DR_UTC_Zeit 0;
BA_ "GenSigSendType" SG_ 1410 HD_Bewegung_auf 0;
BA_ "GenSigSwitchedByIgnition" SG_ 1410 HD_Bewegung_auf 0;
BA_ "GenSigSendType" SG_ 1410 HD_Bewegung_zu 0;
BA_ "GenSigSwitchedByIgnition" SG_ 1410 HD_Bewegung_zu 0;
BA_ "GenSigSendType" SG_ 1410 HD_Endstellung_oben 0;
BA_ "GenSigSwitchedByIgnition" SG_ 1410 HD_Endstellung_oben 0;
BA_ "GenSigSendType" SG_ 1410 HD_Endstellung_unten 0;
BA_ "GenSigSwitchedByIgnition" SG_ 1410 HD_Endstellung_unten 0;
BA_ "GenSigSendType" SG_ 1410 HD_Innentaster_betaetigt 0;
BA_ "GenSigSwitchedByIgnition" SG_ 1410 HD_Innentaster_betaetigt 0;
BA_ "GenSigSendType" SG_ 1410 HD_Kupp_Ma_aktiv 0;
BA_ "GenSigSwitchedByIgnition" SG_ 1410 HD_Kupp_Ma_aktiv 0;
BA_ "GenSigSendType" SG_ 1410 HD_Kupp_Sl_aktiv 0;
BA_ "GenSigSwitchedByIgnition" SG_ 1410 HD_Kupp_Sl_aktiv 0;
BA_ "GenSigSendType" SG_ 1410 HD_Position 0;
BA_ "GenSigSwitchedByIgnition" SG_ 1410 HD_Position 0;
BA_ "GenSigSendType" SG_ 1410 HD_Rueckmeld_prog 0;
BA_ "GenSigSwitchedByIgnition" SG_ 1410 HD_Rueckmeld_prog 0;
BA_ "GenSigSendType" SG_ 1410 HD_SG_MA_KD_Fehler 0;
BA_ "GenSigSwitchedByIgnition" SG_ 1410 HD_SG_MA_KD_Fehler 0;
BA_ "GenSigSendType" SG_ 1410 HD_SG_SL_KD_Fehler 0;
BA_ "GenSigSwitchedByIgnition" SG_ 1410 HD_SG_SL_KD_Fehler 0;
BA_ "GenSigSendType" SG_ 1410 HD_Spannung 0;
BA_ "GenSigSwitchedByIgnition" SG_ 1410 HD_Spannung 0;
BA_ "GenSigSendType" SG_ 1410 HD_Taster_defekt 0;
BA_ "GenSigSwitchedByIgnition" SG_ 1410 HD_Taster_defekt 0;
BA_ "GenSigSendType" SG_ 1410 HD_UeKB_erkannt 0;
BA_ "GenSigSwitchedByIgnition" SG_ 1410 HD_UeKB_erkannt 0;
BA_ "GenSigSendType" SG_ 1410 HD_Verr_Taster_betaetigt_inv 0;
BA_ "GenSigSwitchedByIgnition" SG_ 1410 HD_Verr_Taster_betaetigt_inv 0;
BA_ "GenSigSendType" SG_ 1410 HD_Verriegelungstaster_betaetigt 0;
BA_ "GenSigSwitchedByIgnition" SG_ 1410 HD_Verriegelungstaster_betaetigt 0;
BA_ "GenSigSendType" SG_ 1410 HD_ZZH_Schalter_S3 3;
BA_ "GenSigSwitchedByIgnition" SG_ 1410 HD_ZZH_Schalter_S3 0;
BA_ "GenSigSendType" SG_ 1410 HDSG_Anf_Umluftklappe 3;
BA_ "GenSigSwitchedByIgnition" SG_ 1410 HDSG_Anf_Umluftklappe 0;
BA_ "GenSigSendType" SG_ 1016 HLR_FlHz_Freigabe_HL 3;
BA_ "GenSigSwitchedByIgnition" SG_ 1016 HLR_FlHz_Freigabe_HL 0;
BA_ "GenSigSendType" SG_ 1016 HLR_FlHz_Freigabe_HR 3;
BA_ "GenSigSwitchedByIgnition" SG_ 1016 HLR_FlHz_Freigabe_HR 0;
BA_ "GenSigSendType" SG_ 1016 HLR_FlHz_Freigabe_Ruhesitz 3;
BA_ "GenSigSwitchedByIgnition" SG_ 1016 HLR_FlHz_Freigabe_Ruhesitz 0;
BA_ "GenSigSendType" SG_ 1016 HLR_FlHz_Freigabe_VL 3;
BA_ "GenSigSwitchedByIgnition" SG_ 1016 HLR_FlHz_Freigabe_VL 0;
BA_ "GenSigSendType" SG_ 1016 HLR_FlHz_Freigabe_VR 3;
BA_ "GenSigSwitchedByIgnition" SG_ 1016 HLR_FlHz_Freigabe_VR 0;
BA_ "GenSigSendType" SG_ 1016 HLR_FSH_Freigabe 3;
BA_ "GenSigSwitchedByIgnition" SG_ 1016 HLR_FSH_Freigabe 0;
BA_ "Fehlerwert" SG_ 1016 HLR_FSH_Freigabe 63;
BA_ "GenSigSendType" SG_ 1016 HLR_HSH_Freigabe 3;
BA_ "GenSigSwitchedByIgnition" SG_ 1016 HLR_HSH_Freigabe 0;
BA_ "GenSigSendType" SG_ 1016 HLR_KRH_Freigabe_VL 3;
BA_ "GenSigSwitchedByIgnition" SG_ 1016 HLR_KRH_Freigabe_VL 0;
BA_ "GenSigSendType" SG_ 1016 HLR_KRH_Freigabe_VR 3;
BA_ "GenSigSwitchedByIgnition" SG_ 1016 HLR_KRH_Freigabe_VR 0;
BA_ "GenSigSendType" SG_ 1016 HLR_LRH_Freigabe 3;
BA_ "GenSigSwitchedByIgnition" SG_ 1016 HLR_LRH_Freigabe 0;
BA_ "GenSigSendType" SG_ 1016 HLR_PTC_Freigabe 3;
BA_ "GenSigStartValue" SG_ 1016 HLR_PTC_Freigabe 3;
BA_ "GenSigSwitchedByIgnition" SG_ 1016 HLR_PTC_Freigabe 0;
BA_ "GenSigSendType" SG_ 1016 HLR_PTC_linear_Freigabe 3;
BA_ "GenSigSwitchedByIgnition" SG_ 1016 HLR_PTC_linear_Freigabe 0;
BA_ "Fehlerwert" SG_ 1016 HLR_PTC_linear_Freigabe 63;
BA_ "GenSigSendType" SG_ 1016 HLR_SIH_Freigabe_Fond 3;
BA_ "GenSigSwitchedByIgnition" SG_ 1016 HLR_SIH_Freigabe_Fond 0;
BA_ "GenSigSendType" SG_ 1016 HLR_SIH_Freigabe_HL 3;
BA_ "GenSigSwitchedByIgnition" SG_ 1016 HLR_SIH_Freigabe_HL 0;
BA_ "GenSigSendType" SG_ 1016 HLR_SIH_Freigabe_HR 3;
BA_ "GenSigSwitchedByIgnition" SG_ 1016 HLR_SIH_Freigabe_HR 0;
BA_ "GenSigSendType" SG_ 1016 HLR_SIH_Freigabe_VL 3;
BA_ "GenSigSwitchedByIgnition" SG_ 1016 HLR_SIH_Freigabe_VL 0;
BA_ "GenSigSendType" SG_ 1016 HLR_SIH_Freigabe_VR 3;
BA_ "GenSigSwitchedByIgnition" SG_ 1016 HLR_SIH_Freigabe_VR 0;
BA_ "GenSigSendType" SG_ 1016 HLR_SIL_Freigabe_HL 3;
BA_ "GenSigSwitchedByIgnition" SG_ 1016 HLR_SIL_Freigabe_HL 0;
BA_ "GenSigSendType" SG_ 1016 HLR_SIL_Freigabe_HR 3;
BA_ "GenSigSwitchedByIgnition" SG_ 1016 HLR_SIL_Freigabe_HR 0;
BA_ "GenSigSendType" SG_ 1016 HLR_SIL_Freigabe_VL 3;
BA_ "GenSigSwitchedByIgnition" SG_ 1016 HLR_SIL_Freigabe_VL 0;
BA_ "GenSigSendType" SG_ 1016 HLR_SIL_Freigabe_VR 3;
BA_ "GenSigSwitchedByIgnition" SG_ 1016 HLR_SIL_Freigabe_VR 0;
BA_ "GenSigSendType" SG_ 1016 HLR_Sp_Heizung_Freigabe_BT 3;
BA_ "GenSigSwitchedByIgnition" SG_ 1016 HLR_Sp_Heizung_Freigabe_BT 0;
BA_ "GenSigSendType" SG_ 1016 HLR_Sp_Heizung_Freigabe_FT 3;
BA_ "GenSigSwitchedByIgnition" SG_ 1016 HLR_Sp_Heizung_Freigabe_FT 0;
BA_ "GenSigSendType" SG_ 1016 HLR_TCH_Freigabe 3;
BA_ "GenSigSwitchedByIgnition" SG_ 1016 HLR_TCH_Freigabe 0;
BA_ "GenSigSendType" SG_ 1452 HVEM_Energie_Klima_Vorgabe 0;
BA_ "GenSigStartValue" SG_ 1452 HVEM_Energie_Klima_Vorgabe 254;
BA_ "GenSigSwitchedByIgnition" SG_ 1452 HVEM_Energie_Klima_Vorgabe 0;
BA_ "Fehlerwert" SG_ 1452 HVEM_Energie_Klima_Vorgabe 255;
BA_ "GenSigSendType" SG_ 1452 HVEM_Energie_Klima_Vorgabe_HighR 0;
BA_ "GenSigStartValue" SG_ 1452 HVEM_Energie_Klima_Vorgabe_HighR 6;
BA_ "GenSigSwitchedByIgnition" SG_ 1452 HVEM_Energie_Klima_Vorgabe_HighR 0;
BA_ "Fehlerwert" SG_ 1452 HVEM_Energie_Klima_Vorgabe_HighR 7;
BA_ "GenSigSendType" SG_ 1452 HVEM_HV_Anf 0;
BA_ "GenSigSwitchedByIgnition" SG_ 1452 HVEM_HV_Anf 0;
BA_ "GenSigSendType" SG_ 1452 HVEM_HVK_Aktivitaet 0;
BA_ "GenSigStartValue" SG_ 1452 HVEM_HVK_Aktivitaet 2;
BA_ "GenSigSwitchedByIgnition" SG_ 1452 HVEM_HVK_Aktivitaet 0;
BA_ "GenSigSendType" SG_ 1452 HVEM_IstLeistungNA 0;
BA_ "GenSigStartValue" SG_ 1452 HVEM_IstLeistungNA 510;
BA_ "GenSigSwitchedByIgnition" SG_ 1452 HVEM_IstLeistungNA 0;
BA_ "Fehlerwert" SG_ 1452 HVEM_IstLeistungNA 511;
BA_ "GenSigSendType" SG_ 1452 HVEM_IstStrom_HVVerbraucher 0;
BA_ "GenSigStartValue" SG_ 1452 HVEM_IstStrom_HVVerbraucher 4094;
BA_ "GenSigSwitchedByIgnition" SG_ 1452 HVEM_IstStrom_HVVerbraucher 0;
BA_ "Fehlerwert" SG_ 1452 HVEM_IstStrom_HVVerbraucher 4095;
BA_ "GenSigSendType" SG_ 1452 HVEM_Leistung_Klima_Vorgabe 0;
BA_ "GenSigStartValue" SG_ 1452 HVEM_Leistung_Klima_Vorgabe 254;
BA_ "GenSigSwitchedByIgnition" SG_ 1452 HVEM_Leistung_Klima_Vorgabe 0;
BA_ "Fehlerwert" SG_ 1452 HVEM_Leistung_Klima_Vorgabe 255;
BA_ "GenSigSendType" SG_ 1452 HVEM_MO_MaxLeistungIgnoriert 0;
BA_ "GenSigSwitchedByIgnition" SG_ 1452 HVEM_MO_MaxLeistungIgnoriert 0;
BA_ "GenSigSendType" SG_ 1452 HVEM_Nutzbare_Energie 0;
BA_ "GenSigStartValue" SG_ 1452 HVEM_Nutzbare_Energie 2046;
BA_ "GenSigSwitchedByIgnition" SG_ 1452 HVEM_Nutzbare_Energie 0;
BA_ "Fehlerwert" SG_ 1452 HVEM_Nutzbare_Energie 2047;
BA_ "GenSigSendType" SG_ 1452 HVEM_NVEM_Leistungsvorgabe 0;
BA_ "GenSigStartValue" SG_ 1452 HVEM_NVEM_Leistungsvorgabe 126;
BA_ "GenSigSwitchedByIgnition" SG_ 1452 HVEM_NVEM_Leistungsvorgabe 0;
BA_ "Fehlerwert" SG_ 1452 HVEM_NVEM_Leistungsvorgabe 127;
BA_ "GenSigSendType" SG_ 1452 HVEM_Pruefpuls_Anf 0;
BA_ "GenSigStartValue" SG_ 1452 HVEM_Pruefpuls_Anf 3;
BA_ "GenSigSwitchedByIgnition" SG_ 1452 HVEM_Pruefpuls_Anf 0;
BA_ "GenSigSendType" SG_ 1385 HVEM_Abschaltstatus 3;
BA_ "GenSigStartValue" SG_ 1385 HVEM_Abschaltstatus 7;
BA_ "GenSigSwitchedByIgnition" SG_ 1385 HVEM_Abschaltstatus 0;
BA_ "GenSigSendType" SG_ 1385 HVEM_Anf_ReichweiteNV 3;
BA_ "GenSigSwitchedByIgnition" SG_ 1385 HVEM_Anf_ReichweiteNV 0;
BA_ "Fehlerwert" SG_ 1385 HVEM_Anf_ReichweiteNV 3;
BA_ "GenSigSendType" SG_ 1385 HVEM_Betriebsart 0;
BA_ "GenSigSwitchedByIgnition" SG_ 1385 HVEM_Betriebsart 0;
BA_ "GenSigSendType" SG_ 1385 HVEM_DCDC_Freigabe 0;
BA_ "GenSigSwitchedByIgnition" SG_ 1385 HVEM_DCDC_Freigabe 0;
BA_ "GenSigSendType" SG_ 1385 HVEM_FreigabeBattHeizung 3;
BA_ "GenSigSwitchedByIgnition" SG_ 1385 HVEM_FreigabeBattHeizung 0;
BA_ "Fehlerwert" SG_ 1385 HVEM_FreigabeBattHeizung 3;
BA_ "GenSigSendType" SG_ 1385 HVEM_FreigabeKlimatisierung 3;
BA_ "GenSigStartValue" SG_ 1385 HVEM_FreigabeKlimatisierung 2;
BA_ "GenSigSwitchedByIgnition" SG_ 1385 HVEM_FreigabeKlimatisierung 0;
BA_ "Fehlerwert" SG_ 1385 HVEM_FreigabeKlimatisierung 3;
BA_ "GenSigSendType" SG_ 1385 HVEM_KlimaMaxHVStrom 3;
BA_ "GenSigSwitchedByIgnition" SG_ 1385 HVEM_KlimaMaxHVStrom 0;
BA_ "GenSigSendType" SG_ 1385 HVEM_Ladesteckerentr_Anf 3;
BA_ "GenSigSwitchedByIgnition" SG_ 1385 HVEM_Ladesteckerentr_Anf 0;
BA_ "GenSigSendType" SG_ 1385 HVEM_Leistung_Bat_Kond_Vorgabe 0;
BA_ "GenSigStartValue" SG_ 1385 HVEM_Leistung_Bat_Kond_Vorgabe 254;
BA_ "GenSigSwitchedByIgnition" SG_ 1385 HVEM_Leistung_Bat_Kond_Vorgabe 0;
BA_ "GenSigSendType" SG_ 1385 HVEM_LeistungsAnf 3;
BA_ "GenSigSwitchedByIgnition" SG_ 1385 HVEM_LeistungsAnf 0;
BA_ "GenSigSendType" SG_ 1385 HVEM_MinLeistungNA_Anf 3;
BA_ "GenSigStartValue" SG_ 1385 HVEM_MinLeistungNA_Anf 510;
BA_ "GenSigSwitchedByIgnition" SG_ 1385 HVEM_MinLeistungNA_Anf 0;
BA_ "GenSigSendType" SG_ 1385 HVEM_Nachlad_Status 3;
BA_ "GenSigStartValue" SG_ 1385 HVEM_Nachlad_Status 3;
BA_ "GenSigSwitchedByIgnition" SG_ 1385 HVEM_Nachlad_Status 0;
BA_ "GenSigSendType" SG_ 1385 HVEM_Nachladen_Anf 3;
BA_ "GenSigSwitchedByIgnition" SG_ 1385 HVEM_Nachladen_Anf 0;
BA_ "GenSigSendType" SG_ 1385 HVEM_NVLeistungEmpf 3;
BA_ "GenSigSwitchedByIgnition" SG_ 1385 HVEM_NVLeistungEmpf 0;
BA_ "GenSigSendType" SG_ 1385 HVEM_Text_1 3;
BA_ "GenSigSwitchedByIgnition" SG_ 1385 HVEM_Text_1 0;
BA_ "GenSigSendType" SG_ 1385 HVEM_WunschLeistungNA_Anf 3;
BA_ "GenSigStartValue" SG_ 1385 HVEM_WunschLeistungNA_Anf 510;
BA_ "GenSigSwitchedByIgnition" SG_ 1385 HVEM_WunschLeistungNA_Anf 0;
BA_ "GenSigSendType" SG_ 1385 HVEM_ZusatzMinLeistungNA_Anf 3;
BA_ "GenSigStartValue" SG_ 1385 HVEM_ZusatzMinLeistungNA_Anf 510;
BA_ "GenSigSwitchedByIgnition" SG_ 1385 HVEM_ZusatzMinLeistungNA_Anf 0;
BA_ "GenSigSendType" SG_ 1283 HV_Bordnetz_aktiv 3;
BA_ "GenSigSwitchedByIgnition" SG_ 1283 HV_Bordnetz_aktiv 0;
BA_ "GenSigSendType" SG_ 1283 HV_Bordnetz_Fehler 3;
BA_ "GenSigSwitchedByIgnition" SG_ 1283 HV_Bordnetz_Fehler 0;
BA_ "Fehlerwert" SG_ 1283 HV_Bordnetz_Fehler 1;
BA_ "GenSigSendType" SG_ 1283 HVK_01_BZ 0;
BA_ "GenSigFuncType" SG_ 1283 HVK_01_BZ 1;
BA_ "GenSigSwitchedByIgnition" SG_ 1283 HVK_01_BZ 0;
BA_ "GenSigSendType" SG_ 1283 HVK_01_CRC 0;
BA_ "GenSigFuncType" SG_ 1283 HVK_01_CRC 2;
BA_ "GenSigSwitchedByIgnition" SG_ 1283 HVK_01_CRC 0;
BA_ "GenSigSendType" SG_ 1283 HVK_AktiveEntladung_Anf 3;
BA_ "GenSigSwitchedByIgnition" SG_ 1283 HVK_AktiveEntladung_Anf 0;
BA_ "GenSigSendType" SG_ 1283 HVK_BMS_Sollmodus 3;
BA_ "GenSigStartValue" SG_ 1283 HVK_BMS_Sollmodus 7;
BA_ "GenSigSwitchedByIgnition" SG_ 1283 HVK_BMS_Sollmodus 0;
BA_ "GenSigSendType" SG_ 1283 HVK_DCDC_Sollmodus 3;
BA_ "GenSigStartValue" SG_ 1283 HVK_DCDC_Sollmodus 7;
BA_ "GenSigSwitchedByIgnition" SG_ 1283 HVK_DCDC_Sollmodus 0;
BA_ "GenSigSendType" SG_ 1283 HVK_EKK_Sollmodus 3;
BA_ "GenSigStartValue" SG_ 1283 HVK_EKK_Sollmodus 7;
BA_ "GenSigSwitchedByIgnition" SG_ 1283 HVK_EKK_Sollmodus 0;
BA_ "GenSigSendType" SG_ 1283 HVK_Gesamtst_Spgfreiheit 0;
BA_ "GenSigSwitchedByIgnition" SG_ 1283 HVK_Gesamtst_Spgfreiheit 0;
BA_ "Fehlerwert" SG_ 1283 HVK_Gesamtst_Spgfreiheit 3;
BA_ "GenSigSendType" SG_ 1283 HVK_HV_Netz_Warnungen 3;
BA_ "GenSigSwitchedByIgnition" SG_ 1283 HVK_HV_Netz_Warnungen 0;
BA_ "GenSigSendType" SG_ 1283 HVK_HVEM_Freigabe 3;
BA_ "GenSigStartValue" SG_ 1283 HVK_HVEM_Freigabe 2;
BA_ "GenSigSwitchedByIgnition" SG_ 1283 HVK_HVEM_Freigabe 0;
BA_ "GenSigSendType" SG_ 1283 HVK_HVLM_Sollmodus 3;
BA_ "GenSigStartValue" SG_ 1283 HVK_HVLM_Sollmodus 7;
BA_ "GenSigSwitchedByIgnition" SG_ 1283 HVK_HVLM_Sollmodus 0;
BA_ "GenSigSendType" SG_ 1283 HVK_HVPTC_Sollmodus 3;
BA_ "GenSigStartValue" SG_ 1283 HVK_HVPTC_Sollmodus 7;
BA_ "GenSigSwitchedByIgnition" SG_ 1283 HVK_HVPTC_Sollmodus 0;
BA_ "GenSigSendType" SG_ 1283 HVK_Iso_Messung_Start 0;
BA_ "GenSigSwitchedByIgnition" SG_ 1283 HVK_Iso_Messung_Start 0;
BA_ "GenSigSendType" SG_ 1283 HVK_Istmodus_Anf 3;
BA_ "GenSigSwitchedByIgnition" SG_ 1283 HVK_Istmodus_Anf 0;
BA_ "GenSigSendType" SG_ 1283 HVK_Ladebereit 3;
BA_ "GenSigSwitchedByIgnition" SG_ 1283 HVK_Ladebereit 0;
BA_ "GenSigSendType" SG_ 1283 HVK_Notabschaltung_Anf 3;
BA_ "GenSigSwitchedByIgnition" SG_ 1283 HVK_Notabschaltung_Anf 0;
BA_ "GenSigSendType" SG_ 1283 HVK_PPulsFreigabe 0;
BA_ "GenSigStartValue" SG_ 1283 HVK_PPulsFreigabe 3;
BA_ "GenSigSwitchedByIgnition" SG_ 1283 HVK_PPulsFreigabe 0;
BA_ "GenSigSendType" SG_ 1283 HVK_TN1_Sollmodus 3;
BA_ "GenSigStartValue" SG_ 1283 HVK_TN1_Sollmodus 3;
BA_ "GenSigSwitchedByIgnition" SG_ 1283 HVK_TN1_Sollmodus 0;
BA_ "GenSigSendType" SG_ 1283 HVK_Vorladung_aktiv 3;
BA_ "GenSigSwitchedByIgnition" SG_ 1283 HVK_Vorladung_aktiv 0;
BA_ "GenSigSendType" SG_ 2331595857 HVK_BMS_DC_Ladeschuetze_Soll 0;
BA_ "GenSigStartValue" SG_ 2331595857 HVK_BMS_DC_Ladeschuetze_Soll 6;
BA_ "GenSigSwitchedByIgnition" SG_ 2331595857 HVK_BMS_DC_Ladeschuetze_Soll 0;
BA_ "GenSigSendType" SG_ 2331595857 HVK_BMS_Hauptschuetze_Soll 0;
BA_ "GenSigStartValue" SG_ 2331595857 HVK_BMS_Hauptschuetze_Soll 6;
BA_ "GenSigSwitchedByIgnition" SG_ 2331595857 HVK_BMS_Hauptschuetze_Soll 0;
BA_ "GenSigSendType" SG_ 2331595857 HVK_DC_PruefpulsStatus 3;
BA_ "GenSigStartValue" SG_ 2331595857 HVK_DC_PruefpulsStatus 3;
BA_ "GenSigSwitchedByIgnition" SG_ 2331595857 HVK_DC_PruefpulsStatus 0;
BA_ "GenSigSendType" SG_ 1428 HVLM_Anzeigetexte 0;
BA_ "GenSigSwitchedByIgnition" SG_ 1428 HVLM_Anzeigetexte 0;
BA_ "Fehlerwert" SG_ 1428 HVLM_Anzeigetexte 7;
BA_ "GenSigSendType" SG_ 1428 HVLM_Bat_Konditionierung_Anf 0;
BA_ "GenSigSwitchedByIgnition" SG_ 1428 HVLM_Bat_Konditionierung_Anf 0;
BA_ "GenSigSendType" SG_ 1428 HVLM_Bat_laden_aktiv 0;
BA_ "GenSigSwitchedByIgnition" SG_ 1428 HVLM_Bat_laden_aktiv 0;
BA_ "GenSigSendType" SG_ 1428 HVLM_Fehler_Ladestecker 0;
BA_ "GenSigSwitchedByIgnition" SG_ 1428 HVLM_Fehler_Ladestecker 0;
BA_ "Fehlerwert" SG_ 1428 HVLM_Fehler_Ladestecker 1;
BA_ "GenSigSendType" SG_ 1428 HVLM_Fehler_Verriegelung 0;
BA_ "GenSigSwitchedByIgnition" SG_ 1428 HVLM_Fehler_Verriegelung 0;
BA_ "Fehlerwert" SG_ 1428 HVLM_Fehler_Verriegelung 1;
BA_ "GenSigSendType" SG_ 1428 HVLM_FSH_Anf 0;
BA_ "GenSigSwitchedByIgnition" SG_ 1428 HVLM_FSH_Anf 0;
BA_ "GenSigSendType" SG_ 1428 HVLM_HSH_Anf 0;
BA_ "GenSigSwitchedByIgnition" SG_ 1428 HVLM_HSH_Anf 0;
BA_ "GenSigSendType" SG_ 1428 HVLM_HV_Anf 3;
BA_ "GenSigSwitchedByIgnition" SG_ 1428 HVLM_HV_Anf 0;
BA_ "GenSigSendType" SG_ 1428 HVLM_HVEM_MaxLeistung 0;
BA_ "GenSigStartValue" SG_ 1428 HVLM_HVEM_MaxLeistung 510;
BA_ "GenSigSwitchedByIgnition" SG_ 1428 HVLM_HVEM_MaxLeistung 0;
BA_ "Fehlerwert" SG_ 1428 HVLM_HVEM_MaxLeistung 511;
BA_ "GenSigSendType" SG_ 1428 HVLM_Klima_Temp 0;
BA_ "GenSigStartValue" SG_ 1428 HVLM_Klima_Temp 30;
BA_ "GenSigSwitchedByIgnition" SG_ 1428 HVLM_Klima_Temp 0;
BA_ "Fehlerwert" SG_ 1428 HVLM_Klima_Temp 31;
BA_ "GenSigSendType" SG_ 1428 HVLM_Ladeart 0;
BA_ "GenSigSwitchedByIgnition" SG_ 1428 HVLM_Ladeart 0;
BA_ "GenSigSendType" SG_ 1428 HVLM_Lademodus_HV_Bat 0;
BA_ "GenSigSwitchedByIgnition" SG_ 1428 HVLM_Lademodus_HV_Bat 0;
BA_ "GenSigSendType" SG_ 1428 HVLM_Ladesystemhinweise 0;
BA_ "GenSigSwitchedByIgnition" SG_ 1428 HVLM_Ladesystemhinweise 0;
BA_ "GenSigSendType" SG_ 1428 HVLM_Langzeit_Laden 0;
BA_ "GenSigSwitchedByIgnition" SG_ 1428 HVLM_Langzeit_Laden 0;
BA_ "Fehlerwert" SG_ 1428 HVLM_Langzeit_Laden 3;
BA_ "GenSigSendType" SG_ 1428 HVLM_Restladezeit_HV_Bat_02 0;
BA_ "GenSigStartValue" SG_ 1428 HVLM_Restladezeit_HV_Bat_02 510;
BA_ "GenSigSwitchedByIgnition" SG_ 1428 HVLM_Restladezeit_HV_Bat_02 0;
BA_ "Fehlerwert" SG_ 1428 HVLM_Restladezeit_HV_Bat_02 511;
BA_ "GenSigSendType" SG_ 1428 HVLM_Standklima_Timer_Status 3;
BA_ "GenSigSwitchedByIgnition" SG_ 1428 HVLM_Standklima_Timer_Status 0;
BA_ "GenSigSendType" SG_ 1428 HVLM_Status_Netz 0;
BA_ "GenSigSwitchedByIgnition" SG_ 1428 HVLM_Status_Netz 0;
BA_ "GenSigSendType" SG_ 1428 HVLM_Stecker_Status 0;
BA_ "GenSigSwitchedByIgnition" SG_ 1428 HVLM_Stecker_Status 0;
BA_ "GenSigSendType" SG_ 1428 HVLM_VK_Anf 0;
BA_ "GenSigSwitchedByIgnition" SG_ 1428 HVLM_VK_Anf 0;
BA_ "GenSigSendType" SG_ 1428 HVLM_VK_Modus 0;
BA_ "GenSigSwitchedByIgnition" SG_ 1428 HVLM_VK_Modus 0;
BA_ "Fehlerwert" SG_ 1428 HVLM_VK_Modus 3;
BA_ "GenSigSendType" SG_ 1428 HVLM_VK_STH_Einsatz 0;
BA_ "GenSigStartValue" SG_ 1428 HVLM_VK_STH_Einsatz 6;
BA_ "GenSigSwitchedByIgnition" SG_ 1428 HVLM_VK_STH_Einsatz 0;
BA_ "Fehlerwert" SG_ 1428 HVLM_VK_STH_Einsatz 7;
BA_ "GenSigSendType" SG_ 1428 HVLM_Warnmeldungen 3;
BA_ "GenSigSwitchedByIgnition" SG_ 1428 HVLM_Warnmeldungen 0;
BA_ "GenSigSendType" SG_ 2463978689 HVLM_BCAM_Aktiv 0;
BA_ "GenSigSwitchedByIgnition" SG_ 2463978689 HVLM_BCAM_Aktiv 0;
BA_ "GenSigSendType" SG_ 2463978689 HVLM_BCCM_SoC 0;
BA_ "GenSigStartValue" SG_ 2463978689 HVLM_BCCM_SoC 6;
BA_ "GenSigSwitchedByIgnition" SG_ 2463978689 HVLM_BCCM_SoC 0;
BA_ "Fehlerwert" SG_ 2463978689 HVLM_BCCM_SoC 15;
BA_ "GenSigSendType" SG_ 2463978689 HVLM_BCCMKundenfreigabe_Status 0;
BA_ "GenSigSwitchedByIgnition" SG_ 2463978689 HVLM_BCCMKundenfreigabe_Status 0;
BA_ "GenSigSendType" SG_ 2463978689 HVLM_FreigabeLeistungNebenverbr 0;
BA_ "GenSigStartValue" SG_ 2463978689 HVLM_FreigabeLeistungNebenverbr 510;
BA_ "GenSigSwitchedByIgnition" SG_ 2463978689 HVLM_FreigabeLeistungNebenverbr 0;
BA_ "Fehlerwert" SG_ 2463978689 HVLM_FreigabeLeistungNebenverbr 511;
BA_ "GenSigSendType" SG_ 2463978689 HVLM_IstKonsWunschHVBat 0;
BA_ "GenSigSwitchedByIgnition" SG_ 2463978689 HVLM_IstKonsWunschHVBat 0;
BA_ "GenSigSendType" SG_ 2463978689 HVLM_IstStrom_02 0;
BA_ "GenSigStartValue" SG_ 2463978689 HVLM_IstStrom_02 8190;
BA_ "GenSigSwitchedByIgnition" SG_ 2463978689 HVLM_IstStrom_02 0;
BA_ "Fehlerwert" SG_ 2463978689 HVLM_IstStrom_02 8191;
BA_ "GenSigSendType" SG_ 2463978689 HVLM_SollSoCKonservierung 0;
BA_ "GenSigStartValue" SG_ 2463978689 HVLM_SollSoCKonservierung 126;
BA_ "GenSigSwitchedByIgnition" SG_ 2463978689 HVLM_SollSoCKonservierung 0;
BA_ "Fehlerwert" SG_ 2463978689 HVLM_SollSoCKonservierung 127;
BA_ "GenSigSendType" SG_ 625 HVLM_13_BZ 0;
BA_ "GenSigFuncType" SG_ 625 HVLM_13_BZ 1;
BA_ "GenSigSwitchedByIgnition" SG_ 625 HVLM_13_BZ 0;
BA_ "GenSigSendType" SG_ 625 HVLM_13_CRC 0;
BA_ "GenSigFuncType" SG_ 625 HVLM_13_CRC 2;
BA_ "GenSigSwitchedByIgnition" SG_ 625 HVLM_13_CRC 0;
BA_ "GenSigSendType" SG_ 625 HVLM_CP_Fehlerzustand_A 0;
BA_ "GenSigSwitchedByIgnition" SG_ 625 HVLM_CP_Fehlerzustand_A 0;
BA_ "GenSigSendType" SG_ 625 HVLM_CP_Fehlerzustand_B 0;
BA_ "GenSigSwitchedByIgnition" SG_ 625 HVLM_CP_Fehlerzustand_B 0;
BA_ "GenSigSendType" SG_ 625 HVLM_CP_KommProtokoll_A 0;
BA_ "GenSigSwitchedByIgnition" SG_ 625 HVLM_CP_KommProtokoll_A 0;
BA_ "GenSigSendType" SG_ 625 HVLM_CP_KommProtokoll_B 0;
BA_ "GenSigSwitchedByIgnition" SG_ 625 HVLM_CP_KommProtokoll_B 0;
BA_ "GenSigSendType" SG_ 625 HVLM_CP_MaxStrom_A 0;
BA_ "GenSigStartValue" SG_ 625 HVLM_CP_MaxStrom_A 1022;
BA_ "GenSigSwitchedByIgnition" SG_ 625 HVLM_CP_MaxStrom_A 0;
BA_ "GenSigSendType" SG_ 625 HVLM_CP_MaxStrom_B 0;
BA_ "GenSigStartValue" SG_ 625 HVLM_CP_MaxStrom_B 1022;
BA_ "GenSigSwitchedByIgnition" SG_ 625 HVLM_CP_MaxStrom_B 0;
BA_ "GenSigSendType" SG_ 625 HVLM_CP_State_A 0;
BA_ "GenSigSwitchedByIgnition" SG_ 625 HVLM_CP_State_A 0;
BA_ "GenSigSendType" SG_ 625 HVLM_CP_State_B 0;
BA_ "GenSigSwitchedByIgnition" SG_ 625 HVLM_CP_State_B 0;
BA_ "GenSigSendType" SG_ 625 HVLM_DC_SollStrom 0;
BA_ "GenSigStartValue" SG_ 625 HVLM_DC_SollStrom 2046;
BA_ "GenSigSwitchedByIgnition" SG_ 625 HVLM_DC_SollStrom 0;
BA_ "Fehlerwert" SG_ 625 HVLM_DC_SollStrom 2047;
BA_ "GenSigSendType" SG_ 625 HVLM_elektrLk_Kommandierung_Lk1 0;
BA_ "GenSigSwitchedByIgnition" SG_ 625 HVLM_elektrLk_Kommandierung_Lk1 0;
BA_ "GenSigSendType" SG_ 625 HVLM_elektrLk_Kommandierung_Lk2 0;
BA_ "GenSigSwitchedByIgnition" SG_ 625 HVLM_elektrLk_Kommandierung_Lk2 0;
BA_ "GenSigSendType" SG_ 625 HVLM_elektrLk_Kommandierung_Lk3 0;
BA_ "GenSigStartValue" SG_ 625 HVLM_elektrLk_Kommandierung_Lk3 7;
BA_ "GenSigSwitchedByIgnition" SG_ 625 HVLM_elektrLk_Kommandierung_Lk3 0;
BA_ "GenSigSendType" SG_ 625 HVLM_LadedosenSuchlicht 3;
BA_ "GenSigSwitchedByIgnition" SG_ 625 HVLM_LadedosenSuchlicht 0;
BA_ "GenSigSendType" SG_ 625 HVLM_Ladeklappe_VerEntriegeAnf_1 3;
BA_ "GenSigSwitchedByIgnition" SG_ 625 HVLM_Ladeklappe_VerEntriegeAnf_1 0;
BA_ "GenSigSendType" SG_ 625 HVLM_Ladeklappe_VerEntriegeAnf_2 3;
BA_ "GenSigSwitchedByIgnition" SG_ 625 HVLM_Ladeklappe_VerEntriegeAnf_2 0;
BA_ "GenSigSendType" SG_ 625 HVLM_Ladeklappe_VerEntriegeAnf_3 3;
BA_ "GenSigSwitchedByIgnition" SG_ 625 HVLM_Ladeklappe_VerEntriegeAnf_3 0;
BA_ "GenSigSendType" SG_ 625 HVLM_Max_Strom_Netz_L1 0;
BA_ "GenSigStartValue" SG_ 625 HVLM_Max_Strom_Netz_L1 1022;
BA_ "GenSigSwitchedByIgnition" SG_ 625 HVLM_Max_Strom_Netz_L1 0;
BA_ "Fehlerwert" SG_ 625 HVLM_Max_Strom_Netz_L1 1023;
BA_ "GenSigSendType" SG_ 625 HVLM_Max_Strom_Netz_L2 0;
BA_ "GenSigStartValue" SG_ 625 HVLM_Max_Strom_Netz_L2 1022;
BA_ "GenSigSwitchedByIgnition" SG_ 625 HVLM_Max_Strom_Netz_L2 0;
BA_ "Fehlerwert" SG_ 625 HVLM_Max_Strom_Netz_L2 1023;
BA_ "GenSigSendType" SG_ 625 HVLM_Max_Strom_Netz_L3 0;
BA_ "GenSigStartValue" SG_ 625 HVLM_Max_Strom_Netz_L3 1022;
BA_ "GenSigSwitchedByIgnition" SG_ 625 HVLM_Max_Strom_Netz_L3 0;
BA_ "Fehlerwert" SG_ 625 HVLM_Max_Strom_Netz_L3 1023;
BA_ "GenSigSendType" SG_ 625 HVLM_MaxSpannung_OBG_HV 3;
BA_ "GenSigStartValue" SG_ 625 HVLM_MaxSpannung_OBG_HV 1022;
BA_ "GenSigSwitchedByIgnition" SG_ 625 HVLM_MaxSpannung_OBG_HV 0;
BA_ "Fehlerwert" SG_ 625 HVLM_MaxSpannung_OBG_HV 1023;
BA_ "GenSigSendType" SG_ 625 HVLM_OBG_SollModus 0;
BA_ "GenSigSwitchedByIgnition" SG_ 625 HVLM_OBG_SollModus 0;
BA_ "GenSigSendType" SG_ 625 HVLM_ReversierenFreigabe_Lk1 0;
BA_ "GenSigSwitchedByIgnition" SG_ 625 HVLM_ReversierenFreigabe_Lk1 0;
BA_ "GenSigSendType" SG_ 625 HVLM_ReversierenFreigabe_Lk2 0;
BA_ "GenSigSwitchedByIgnition" SG_ 625 HVLM_ReversierenFreigabe_Lk2 0;
BA_ "GenSigSendType" SG_ 625 HVLM_ReversierenFreigabe_Lk3 0;
BA_ "GenSigSwitchedByIgnition" SG_ 625 HVLM_ReversierenFreigabe_Lk3 0;
BA_ "GenSigSendType" SG_ 625 HVLM_S2SchliessenAnf_A 3;
BA_ "GenSigSwitchedByIgnition" SG_ 625 HVLM_S2SchliessenAnf_A 0;
BA_ "GenSigSendType" SG_ 625 HVLM_S2SchliessenAnf_B 3;
BA_ "GenSigSwitchedByIgnition" SG_ 625 HVLM_S2SchliessenAnf_B 0;
BA_ "GenSigSendType" SG_ 625 HVLM_SchnellladeVokoAuto_Anf 0;
BA_ "GenSigSwitchedByIgnition" SG_ 625 HVLM_SchnellladeVokoAuto_Anf 0;
BA_ "GenSigSendType" SG_ 625 HVLM_SchnellladeVokoManuell_Anf 0;
BA_ "GenSigSwitchedByIgnition" SG_ 625 HVLM_SchnellladeVokoManuell_Anf 0;
BA_ "GenSigSendType" SG_ 625 HVLM_SF4OeffnenAnf_A 3;
BA_ "GenSigSwitchedByIgnition" SG_ 625 HVLM_SF4OeffnenAnf_A 0;
BA_ "GenSigSendType" SG_ 625 HVLM_SF4OeffnenAnf_B 3;
BA_ "GenSigSwitchedByIgnition" SG_ 625 HVLM_SF4OeffnenAnf_B 0;
BA_ "GenSigSendType" SG_ 625 HVLM_Stecker_Notentriegeln_Anf_A 3;
BA_ "GenSigSwitchedByIgnition" SG_ 625 HVLM_Stecker_Notentriegeln_Anf_A 0;
BA_ "GenSigSendType" SG_ 625 HVLM_Stecker_Notentriegeln_Anf_B 3;
BA_ "GenSigSwitchedByIgnition" SG_ 625 HVLM_Stecker_Notentriegeln_Anf_B 0;
BA_ "GenSigSendType" SG_ 625 HVLM_Stecker_Notentriegeln_Anf_C 3;
BA_ "GenSigSwitchedByIgnition" SG_ 625 HVLM_Stecker_Notentriegeln_Anf_C 0;
BA_ "GenSigSendType" SG_ 625 HVLM_Stecker_VerEntriegelnAnf_A 3;
BA_ "GenSigSwitchedByIgnition" SG_ 625 HVLM_Stecker_VerEntriegelnAnf_A 0;
BA_ "GenSigSendType" SG_ 625 HVLM_Stecker_VerEntriegelnAnf_B 3;
BA_ "GenSigSwitchedByIgnition" SG_ 625 HVLM_Stecker_VerEntriegelnAnf_B 0;
BA_ "GenSigSendType" SG_ 625 HVLM_Stecker_VerEntriegelnAnf_C 3;
BA_ "GenSigSwitchedByIgnition" SG_ 625 HVLM_Stecker_VerEntriegelnAnf_C 0;
BA_ "GenSigSendType" SG_ 625 LVB_Ladegeschw 0;
BA_ "GenSigStartValue" SG_ 625 LVB_Ladegeschw 8190;
BA_ "GenSigSwitchedByIgnition" SG_ 625 LVB_Ladegeschw 0;
BA_ "GenSigSendType" SG_ 625 LVB_Ladegeschw_VZ 0;
BA_ "GenSigStartValue" SG_ 625 LVB_Ladegeschw_VZ 1;
BA_ "GenSigSwitchedByIgnition" SG_ 625 LVB_Ladegeschw_VZ 0;
BA_ "GenSigSendType" SG_ 625 LVB_LadegeschwEinheit 0;
BA_ "GenSigSwitchedByIgnition" SG_ 625 LVB_LadegeschwEinheit 0;
BA_ "GenSigSendType" SG_ 625 LVB_Restladezeit 0;
BA_ "GenSigStartValue" SG_ 625 LVB_Restladezeit 4094;
BA_ "GenSigSwitchedByIgnition" SG_ 625 LVB_Restladezeit 0;
BA_ "Fehlerwert" SG_ 625 LVB_Restladezeit 4095;
BA_ "GenSigSendType" SG_ 625 LVB_StatusLadegeschw 0;
BA_ "GenSigStartValue" SG_ 625 LVB_StatusLadegeschw 2;
BA_ "GenSigSwitchedByIgnition" SG_ 625 LVB_StatusLadegeschw 0;
BA_ "GenSigSendType" SG_ 625 LVB_StatusRestladezeit 0;
BA_ "GenSigStartValue" SG_ 625 LVB_StatusRestladezeit 2;
BA_ "GenSigSwitchedByIgnition" SG_ 625 LVB_StatusRestladezeit 0;
BA_ "GenSigSendType" SG_ 805 SOK_HVLM_13_Signatur 0;
BA_ "GenSigFuncType" SG_ 805 SOK_HVLM_13_Signatur 15;
BA_ "GenSigSwitchedByIgnition" SG_ 805 SOK_HVLM_13_Signatur 0;
BA_ "GenSigSendType" SG_ 626 HVLM_Aktive_Ladeart 3;
BA_ "GenSigSwitchedByIgnition" SG_ 626 HVLM_Aktive_Ladeart 0;
BA_ "Fehlerwert" SG_ 626 HVLM_Aktive_Ladeart 7;
BA_ "GenSigSendType" SG_ 626 HVLM_Anforderung_HMS 0;
BA_ "GenSigSwitchedByIgnition" SG_ 626 HVLM_Anforderung_HMS 0;
BA_ "GenSigSendType" SG_ 626 HVLM_AWC_VerbautStatus 0;
BA_ "GenSigSwitchedByIgnition" SG_ 626 HVLM_AWC_VerbautStatus 0;
BA_ "Fehlerwert" SG_ 626 HVLM_AWC_VerbautStatus 3;
BA_ "GenSigSendType" SG_ 626 HVLM_DC_Aufstartmodus 0;
BA_ "GenSigSwitchedByIgnition" SG_ 626 HVLM_DC_Aufstartmodus 0;
BA_ "GenSigSendType" SG_ 626 HVLM_Intensitaet_Lk1 3;
BA_ "GenSigStartValue" SG_ 626 HVLM_Intensitaet_Lk1 126;
BA_ "GenSigSwitchedByIgnition" SG_ 626 HVLM_Intensitaet_Lk1 0;
BA_ "Fehlerwert" SG_ 626 HVLM_Intensitaet_Lk1 127;
BA_ "GenSigSendType" SG_ 626 HVLM_Intensitaet_Lk2 3;
BA_ "GenSigStartValue" SG_ 626 HVLM_Intensitaet_Lk2 126;
BA_ "GenSigSwitchedByIgnition" SG_ 626 HVLM_Intensitaet_Lk2 0;
BA_ "Fehlerwert" SG_ 626 HVLM_Intensitaet_Lk2 127;
BA_ "GenSigSendType" SG_ 626 HVLM_Laden_ISO_Messung_Anf 0;
BA_ "GenSigStartValue" SG_ 626 HVLM_Laden_ISO_Messung_Anf 1;
BA_ "GenSigSwitchedByIgnition" SG_ 626 HVLM_Laden_ISO_Messung_Anf 0;
BA_ "GenSigSendType" SG_ 626 HVLM_Ladeszenario 3;
BA_ "GenSigStartValue" SG_ 626 HVLM_Ladeszenario 30;
BA_ "GenSigSwitchedByIgnition" SG_ 626 HVLM_Ladeszenario 0;
BA_ "Fehlerwert" SG_ 626 HVLM_Ladeszenario 31;
BA_ "GenSigSendType" SG_ 626 HVLM_Ladevorgang_Anf 0;
BA_ "GenSigSwitchedByIgnition" SG_ 626 HVLM_Ladevorgang_Anf 0;
BA_ "GenSigSendType" SG_ 626 HVLM_Parken_beibehalten_HMS 0;
BA_ "GenSigStartValue" SG_ 626 HVLM_Parken_beibehalten_HMS 2;
BA_ "GenSigSwitchedByIgnition" SG_ 626 HVLM_Parken_beibehalten_HMS 0;
BA_ "Fehlerwert" SG_ 626 HVLM_Parken_beibehalten_HMS 3;
BA_ "GenSigSendType" SG_ 626 HVLM_Pulsierstufe 3;
BA_ "GenSigSwitchedByIgnition" SG_ 626 HVLM_Pulsierstufe 0;
BA_ "GenSigSendType" SG_ 626 HVLM_Start_Pulserkennung 0;
BA_ "GenSigSwitchedByIgnition" SG_ 626 HVLM_Start_Pulserkennung 0;
BA_ "GenSigSendType" SG_ 626 HVLM_Steckerstatus_A 3;
BA_ "GenSigSwitchedByIgnition" SG_ 626 HVLM_Steckerstatus_A 0;
BA_ "Fehlerwert" SG_ 626 HVLM_Steckerstatus_A 7;
BA_ "GenSigSendType" SG_ 626 HVLM_Steckerstatus_B 3;
BA_ "GenSigSwitchedByIgnition" SG_ 626 HVLM_Steckerstatus_B 0;
BA_ "Fehlerwert" SG_ 626 HVLM_Steckerstatus_B 7;
BA_ "GenSigSendType" SG_ 626 HVLM_WakeUpZaehlerResetAnf 0;
BA_ "GenSigSwitchedByIgnition" SG_ 626 HVLM_WakeUpZaehlerResetAnf 0;
BA_ "GenSigSendType" SG_ 626 HVLM_ZustandLadeablauf 0;
BA_ "GenSigSwitchedByIgnition" SG_ 626 HVLM_ZustandLadeablauf 0;
BA_ "Fehlerwert" SG_ 626 HVLM_ZustandLadeablauf 3;
BA_ "GenSigSendType" SG_ 2463978708 HVLM_CDO_DynamischLaden_Status 0;
BA_ "GenSigSwitchedByIgnition" SG_ 2463978708 HVLM_CDO_DynamischLaden_Status 0;
BA_ "GenSigSendType" SG_ 2463978708 HVLM_CDO_Fehler_Fahrzeug 0;
BA_ "GenSigSwitchedByIgnition" SG_ 2463978708 HVLM_CDO_Fehler_Fahrzeug 0;
BA_ "Fehlerwert" SG_ 2463978708 HVLM_CDO_Fehler_Fahrzeug 1;
BA_ "GenSigSendType" SG_ 2463978708 HVLM_CDO_Fehler_HVBatSpgDiffFzg 0;
BA_ "GenSigSwitchedByIgnition" SG_ 2463978708 HVLM_CDO_Fehler_HVBatSpgDiffFzg 0;
BA_ "GenSigSendType" SG_ 2463978708 HVLM_CDO_Fehler_HVBatUeberspgFzg 0;
BA_ "GenSigSwitchedByIgnition" SG_ 2463978708 HVLM_CDO_Fehler_HVBatUeberspgFzg 0;
BA_ "GenSigSendType" SG_ 2463978708 HVLM_CDO_Fehler_HVBatUebertemp 0;
BA_ "GenSigSwitchedByIgnition" SG_ 2463978708 HVLM_CDO_Fehler_HVBatUebertemp 0;
BA_ "GenSigSendType" SG_ 2463978708 HVLM_CDO_Fehler_HVBatUnterspFzg 0;
BA_ "GenSigSwitchedByIgnition" SG_ 2463978708 HVLM_CDO_Fehler_HVBatUnterspFzg 0;
BA_ "GenSigSendType" SG_ 2463978708 HVLM_CDO_Fehler_HVStromDiffFzg 0;
BA_ "GenSigSwitchedByIgnition" SG_ 2463978708 HVLM_CDO_Fehler_HVStromDiffFzg 0;
BA_ "GenSigSendType" SG_ 2463978708 HVLM_CDO_GesamtKapazitaetHvBatt 0;
BA_ "GenSigSwitchedByIgnition" SG_ 2463978708 HVLM_CDO_GesamtKapazitaetHvBatt 0;
BA_ "GenSigSendType" SG_ 2463978708 HVLM_CDO_HvBatIstLadezustandFzg 0;
BA_ "GenSigSwitchedByIgnition" SG_ 2463978708 HVLM_CDO_HvBatIstLadezustandFzg 0;
BA_ "GenSigSendType" SG_ 2463978708 HVLM_CDO_HvMaxSpannungFzg 0;
BA_ "GenSigSwitchedByIgnition" SG_ 2463978708 HVLM_CDO_HvMaxSpannungFzg 0;
BA_ "GenSigSendType" SG_ 2463978708 HVLM_CDO_HvMinSpannungFzg 0;
BA_ "GenSigSwitchedByIgnition" SG_ 2463978708 HVLM_CDO_HvMinSpannungFzg 0;
BA_ "GenSigSendType" SG_ 2463978708 HVLM_CDO_HvMinStromFzg 0;
BA_ "GenSigStartValue" SG_ 2463978708 HVLM_CDO_HvMinStromFzg 1;
BA_ "GenSigSwitchedByIgnition" SG_ 2463978708 HVLM_CDO_HvMinStromFzg 0;
BA_ "GenSigSendType" SG_ 2463978708 HVLM_CDO_LadebereitFzg 0;
BA_ "GenSigSwitchedByIgnition" SG_ 2463978708 HVLM_CDO_LadebereitFzg 0;
BA_ "GenSigSendType" SG_ 2463978708 HVLM_CDO_LadeerlaubnisLm 0;
BA_ "GenSigSwitchedByIgnition" SG_ 2463978708 HVLM_CDO_LadeerlaubnisLm 0;
BA_ "GenSigSendType" SG_ 2463978708 HVLM_CDO_LadenBeendenAnfFzg 0;
BA_ "GenSigSwitchedByIgnition" SG_ 2463978708 HVLM_CDO_LadenBeendenAnfFzg 0;
BA_ "GenSigSendType" SG_ 2463978708 HVLM_CDO_LsNachrichtSendenAnf 6;
BA_ "GenSigSwitchedByIgnition" SG_ 2463978708 HVLM_CDO_LsNachrichtSendenAnf 0;
BA_ "GenSigSendType" SG_ 2463978708 HVLM_CDO_MaxLadezeitFzg 0;
BA_ "GenSigSwitchedByIgnition" SG_ 2463978708 HVLM_CDO_MaxLadezeitFzg 0;
BA_ "GenSigSendType" SG_ 2463978708 HVLM_CDO_MaxLadezeitFzg_ext 0;
BA_ "GenSigSwitchedByIgnition" SG_ 2463978708 HVLM_CDO_MaxLadezeitFzg_ext 0;
BA_ "GenSigSendType" SG_ 2463978708 HVLM_CDO_ProtokollVersionFzg 0;
BA_ "GenSigSwitchedByIgnition" SG_ 2463978708 HVLM_CDO_ProtokollVersionFzg 0;
BA_ "GenSigSendType" SG_ 2463978708 HVLM_CDO_ReferenzLadezustandFzg 0;
BA_ "GenSigSwitchedByIgnition" SG_ 2463978708 HVLM_CDO_ReferenzLadezustandFzg 0;
BA_ "GenSigSendType" SG_ 2463978708 HVLM_CDO_RestLadedauerFzg 0;
BA_ "GenSigSwitchedByIgnition" SG_ 2463978708 HVLM_CDO_RestLadedauerFzg 0;
BA_ "GenSigSendType" SG_ 2463978708 HVLM_CDO_SollStromFzg 0;
BA_ "GenSigSwitchedByIgnition" SG_ 2463978708 HVLM_CDO_SollStromFzg 0;
BA_ "GenSigSendType" SG_ 2463978708 HVLM_CDO_SollStromFzg_ext 0;
BA_ "GenSigSwitchedByIgnition" SG_ 2463978708 HVLM_CDO_SollStromFzg_ext 0;
BA_ "GenSigSendType" SG_ 2463978708 HVLM_CDO_SpannungExt_Status 0;
BA_ "GenSigSwitchedByIgnition" SG_ 2463978708 HVLM_CDO_SpannungExt_Status 0;
BA_ "GenSigSendType" SG_ 2463978708 HVLM_CDO_Status_Fahrzeug 0;
BA_ "GenSigSwitchedByIgnition" SG_ 2463978708 HVLM_CDO_Status_Fahrzeug 0;
BA_ "GenSigSendType" SG_ 2463978708 HVLM_CDO_SteckerVerEntr_Status 3;
BA_ "GenSigSwitchedByIgnition" SG_ 2463978708 HVLM_CDO_SteckerVerEntr_Status 0;
BA_ "GenSigSendType" SG_ 2463978708 HVLM_CDO_StromExt_Status 0;
BA_ "GenSigSwitchedByIgnition" SG_ 2463978708 HVLM_CDO_StromExt_Status 0;
BA_ "GenSigSendType" SG_ 2463978708 HVLM_CDO_WahlhebelPosition_P_Fzg 0;
BA_ "GenSigSwitchedByIgnition" SG_ 2463978708 HVLM_CDO_WahlhebelPosition_P_Fzg 0;
BA_ "GenSigSendType" SG_ 2463978708 HVLM_CDO_ZielLadespannungFzg 0;
BA_ "GenSigSwitchedByIgnition" SG_ 2463978708 HVLM_CDO_ZielLadespannungFzg 0;
BA_ "GenSigSendType" SG_ 2331596000 HVLM_CdoCj_S2UmschaltenAnf 3;
BA_ "GenSigSwitchedByIgnition" SG_ 2331596000 HVLM_CdoCj_S2UmschaltenAnf 0;
BA_ "GenSigSendType" SG_ 2331596000 HVLM_CdoCj_SvSchliessenAnf 3;
BA_ "GenSigSwitchedByIgnition" SG_ 2331596000 HVLM_CdoCj_SvSchliessenAnf 0;
BA_ "GenSigSendType" SG_ 2331596000 HVLM_CdoCj_SvsSchliessenAnf 3;
BA_ "GenSigSwitchedByIgnition" SG_ 2331596000 HVLM_CdoCj_SvsSchliessenAnf 0;
BA_ "GenSigActiveRepetitions" SG_ 2331596000 HVLM_CJ_01_Sendestatus 5;
BA_ "GenSigSendType" SG_ 2331596000 HVLM_CJ_01_Sendestatus 6;
BA_ "GenSigSwitchedByIgnition" SG_ 2331596000 HVLM_CJ_01_Sendestatus 0;
BA_ "GenSigSendType" SG_ 2331596000 HVLM_CJ_CanTypFzg 0;
BA_ "GenSigStartValue" SG_ 2331596000 HVLM_CJ_CanTypFzg 255;
BA_ "GenSigSwitchedByIgnition" SG_ 2331596000 HVLM_CJ_CanTypFzg 0;
BA_ "GenSigSendType" SG_ 2331596000 HVLM_CJ_CheckcodeFzg 0;
BA_ "GenSigSwitchedByIgnition" SG_ 2331596000 HVLM_CJ_CheckcodeFzg 0;
BA_ "GenSigSendType" SG_ 2331596000 HVLM_CJ_FC1_FDC_Selection 0;
BA_ "GenSigSwitchedByIgnition" SG_ 2331596000 HVLM_CJ_FC1_FDC_Selection 0;
BA_ "GenSigSendType" SG_ 2331596000 HVLM_CJ_FC2_FDC_Selection 0;
BA_ "GenSigSwitchedByIgnition" SG_ 2331596000 HVLM_CJ_FC2_FDC_Selection 0;
BA_ "GenSigSendType" SG_ 2331596000 HVLM_CJ_FC3_FDC_Selection 0;
BA_ "GenSigSwitchedByIgnition" SG_ 2331596000 HVLM_CJ_FC3_FDC_Selection 0;
BA_ "GenSigSendType" SG_ 2331596000 HVLM_CJ_FC4_FDC_Selection 0;
BA_ "GenSigSwitchedByIgnition" SG_ 2331596000 HVLM_CJ_FC4_FDC_Selection 0;
BA_ "GenSigSendType" SG_ 2331596000 HVLM_CJ_FC5_FDC_Selection 0;
BA_ "GenSigSwitchedByIgnition" SG_ 2331596000 HVLM_CJ_FC5_FDC_Selection 0;
BA_ "GenSigSendType" SG_ 2331596000 HVLM_CJ_FC6_FDC_Selection 0;
BA_ "GenSigSwitchedByIgnition" SG_ 2331596000 HVLM_CJ_FC6_FDC_Selection 0;
BA_ "GenSigSendType" SG_ 2331596000 HVLM_CJ_FCFDC_CheckFzg 0;
BA_ "GenSigStartValue" SG_ 2331596000 HVLM_CJ_FCFDC_CheckFzg 255;
BA_ "GenSigSwitchedByIgnition" SG_ 2331596000 HVLM_CJ_FCFDC_CheckFzg 0;
BA_ "GenSigSendType" SG_ 2331596000 HVLM_CJ_GrundLadeendeFzg 0;
BA_ "GenSigStartValue" SG_ 2331596000 HVLM_CJ_GrundLadeendeFzg 255;
BA_ "GenSigSwitchedByIgnition" SG_ 2331596000 HVLM_CJ_GrundLadeendeFzg 0;
BA_ "GenSigSendType" SG_ 2331596000 HVLM_CJ_IstSOC 0;
BA_ "GenSigStartValue" SG_ 2331596000 HVLM_CJ_IstSOC 65534;
BA_ "GenSigSwitchedByIgnition" SG_ 2331596000 HVLM_CJ_IstSOC 0;
BA_ "Fehlerwert" SG_ 2331596000 HVLM_CJ_IstSOC 65535;
BA_ "GenSigSendType" SG_ 2331596000 HVLM_CJ_IstSpannungFzg 0;
BA_ "GenSigStartValue" SG_ 2331596000 HVLM_CJ_IstSpannungFzg 65534;
BA_ "GenSigSwitchedByIgnition" SG_ 2331596000 HVLM_CJ_IstSpannungFzg 0;
BA_ "Fehlerwert" SG_ 2331596000 HVLM_CJ_IstSpannungFzg 65535;
BA_ "GenSigSendType" SG_ 2331596000 HVLM_CJ_LadebereitschaftFzg 0;
BA_ "GenSigSwitchedByIgnition" SG_ 2331596000 HVLM_CJ_LadebereitschaftFzg 0;
BA_ "GenSigSendType" SG_ 2331596000 HVLM_CJ_LadeendeFehlerFzg 0;
BA_ "GenSigStartValue" SG_ 2331596000 HVLM_CJ_LadeendeFehlerFzg 255;
BA_ "GenSigSwitchedByIgnition" SG_ 2331596000 HVLM_CJ_LadeendeFehlerFzg 0;
BA_ "GenSigSendType" SG_ 2331596000 HVLM_CJ_LadeendeFzg 0;
BA_ "GenSigStartValue" SG_ 2331596000 HVLM_CJ_LadeendeFzg 255;
BA_ "GenSigSwitchedByIgnition" SG_ 2331596000 HVLM_CJ_LadeendeFzg 0;
BA_ "GenSigSendType" SG_ 2331596000 HVLM_CJ_LadeendeTimeoutFzg 0;
BA_ "GenSigStartValue" SG_ 2331596000 HVLM_CJ_LadeendeTimeoutFzg 255;
BA_ "GenSigSwitchedByIgnition" SG_ 2331596000 HVLM_CJ_LadeendeTimeoutFzg 0;
BA_ "GenSigSendType" SG_ 2331596000 HVLM_CJ_Lademodus 0;
BA_ "GenSigStartValue" SG_ 2331596000 HVLM_CJ_Lademodus 255;
BA_ "GenSigSwitchedByIgnition" SG_ 2331596000 HVLM_CJ_Lademodus 0;
BA_ "GenSigSendType" SG_ 2331596000 HVLM_CJ_MaxLadeernergieFzg 0;
BA_ "GenSigStartValue" SG_ 2331596000 HVLM_CJ_MaxLadeernergieFzg 65534;
BA_ "GenSigSwitchedByIgnition" SG_ 2331596000 HVLM_CJ_MaxLadeernergieFzg 0;
BA_ "Fehlerwert" SG_ 2331596000 HVLM_CJ_MaxLadeernergieFzg 65535;
BA_ "GenSigSendType" SG_ 2331596000 HVLM_CJ_MaxLadestromFzg 0;
BA_ "GenSigStartValue" SG_ 2331596000 HVLM_CJ_MaxLadestromFzg 65534;
BA_ "GenSigSwitchedByIgnition" SG_ 2331596000 HVLM_CJ_MaxLadestromFzg 0;
BA_ "Fehlerwert" SG_ 2331596000 HVLM_CJ_MaxLadestromFzg 65535;
BA_ "GenSigSendType" SG_ 2331596000 HVLM_CJ_MaxLadspannungFzg 0;
BA_ "GenSigStartValue" SG_ 2331596000 HVLM_CJ_MaxLadspannungFzg 65534;
BA_ "GenSigSwitchedByIgnition" SG_ 2331596000 HVLM_CJ_MaxLadspannungFzg 0;
BA_ "Fehlerwert" SG_ 2331596000 HVLM_CJ_MaxLadspannungFzg 65535;
BA_ "GenSigSendType" SG_ 2331596000 HVLM_CJ_PgiFzg 0;
BA_ "GenSigStartValue" SG_ 2331596000 HVLM_CJ_PgiFzg 255;
BA_ "GenSigSwitchedByIgnition" SG_ 2331596000 HVLM_CJ_PgiFzg 0;
BA_ "GenSigSendType" SG_ 2331596000 HVLM_CJ_ProtokollVersionFzg 0;
BA_ "GenSigSwitchedByIgnition" SG_ 2331596000 HVLM_CJ_ProtokollVersionFzg 0;
BA_ "GenSigSendType" SG_ 2331596000 HVLM_CJ_Restladezeit 0;
BA_ "GenSigStartValue" SG_ 2331596000 HVLM_CJ_Restladezeit 65534;
BA_ "GenSigSwitchedByIgnition" SG_ 2331596000 HVLM_CJ_Restladezeit 0;
BA_ "Fehlerwert" SG_ 2331596000 HVLM_CJ_Restladezeit 65535;
BA_ "GenSigSendType" SG_ 2331596000 HVLM_CJ_SendeAnf_ACK 0;
BA_ "GenSigSwitchedByIgnition" SG_ 2331596000 HVLM_CJ_SendeAnf_ACK 0;
BA_ "GenSigSendType" SG_ 2331596000 HVLM_CJ_SendeAnf_EndACK 0;
BA_ "GenSigSwitchedByIgnition" SG_ 2331596000 HVLM_CJ_SendeAnf_EndACK 0;
BA_ "GenSigSendType" SG_ 2331596000 HVLM_CJ_SendeAnf_LongMessage 0;
BA_ "GenSigSwitchedByIgnition" SG_ 2331596000 HVLM_CJ_SendeAnf_LongMessage 0;
BA_ "GenSigSendType" SG_ 2331596000 HVLM_CJ_SendeAnf_Pausieren 0;
BA_ "GenSigSwitchedByIgnition" SG_ 2331596000 HVLM_CJ_SendeAnf_Pausieren 0;
BA_ "GenSigSendType" SG_ 2331596000 HVLM_CJ_SendeAnf_SMRM 0;
BA_ "GenSigSwitchedByIgnition" SG_ 2331596000 HVLM_CJ_SendeAnf_SMRM 0;
BA_ "GenSigSendType" SG_ 2331596000 HVLM_CJ_SendeAnf_SMURM 0;
BA_ "GenSigSwitchedByIgnition" SG_ 2331596000 HVLM_CJ_SendeAnf_SMURM 0;
BA_ "GenSigSendType" SG_ 2331596000 HVLM_CJ_SendeAnf_Stoppen 0;
BA_ "GenSigSwitchedByIgnition" SG_ 2331596000 HVLM_CJ_SendeAnf_Stoppen 0;
BA_ "GenSigSendType" SG_ 2331596000 HVLM_CJ_SollspannungFzg 0;
BA_ "GenSigStartValue" SG_ 2331596000 HVLM_CJ_SollspannungFzg 65534;
BA_ "GenSigSwitchedByIgnition" SG_ 2331596000 HVLM_CJ_SollspannungFzg 0;
BA_ "Fehlerwert" SG_ 2331596000 HVLM_CJ_SollspannungFzg 65535;
BA_ "GenSigSendType" SG_ 2331596000 HVLM_CJ_SollstromFzg 0;
BA_ "GenSigStartValue" SG_ 2331596000 HVLM_CJ_SollstromFzg 65534;
BA_ "GenSigSwitchedByIgnition" SG_ 2331596000 HVLM_CJ_SollstromFzg 0;
BA_ "Fehlerwert" SG_ 2331596000 HVLM_CJ_SollstromFzg 65535;
BA_ "GenSigSendType" SG_ 2331596000 HVLM_CJ_StatusProtokollVerh 0;
BA_ "GenSigStartValue" SG_ 2331596000 HVLM_CJ_StatusProtokollVerh 255;
BA_ "GenSigSwitchedByIgnition" SG_ 2331596000 HVLM_CJ_StatusProtokollVerh 0;
BA_ "GenSigSendType" SG_ 2331596000 HVLM_CJ_SteckerVerEntr_Status 0;
BA_ "GenSigSwitchedByIgnition" SG_ 2331596000 HVLM_CJ_SteckerVerEntr_Status 0;
BA_ "GenSigSendType" SG_ 2331596000 HVLM_CJ_VerbindungAnf 0;
BA_ "GenSigSwitchedByIgnition" SG_ 2331596000 HVLM_CJ_VerbindungAnf 0;
BA_REL_ "GenSigTimeoutTime" BU_SG_REL_ BMS_NV_12V SG_ 253 ESP_v_Signal 500;
BA_REL_ "GenSigTimeoutTime" BU_SG_REL_ Klima SG_ 253 ESP_v_Signal 500;
BA_REL_ "GenSigTimeoutTime" BU_SG_REL_ Klima SG_ 253 ESP_QBit_v_Signal 500;
BA_REL_ "GenSigTimeoutTime" BU_SG_REL_ Klima SG_ 2527679668 eTM_Ventil1_Status 5000;
BA_REL_ "GenSigTimeoutTime" BU_SG_REL_ Klima SG_ 2527679668 eTM_Ventil2_Status 5000;
BA_REL_ "GenSigTimeoutTime" BU_SG_REL_ Klima SG_ 2527679668 eTM_Ventil3_Status 5000;
BA_REL_ "GenSigTimeoutTime" BU_SG_REL_ Klima SG_ 2527679668 eTM_BMS_Pumpe1_SollAnsteuerung 5000;
BA_REL_ "GenSigTimeoutTime" BU_SG_REL_ Klima SG_ 2527679668 eTM_Pumpe2_Volumenstrom 5000;
BA_REL_ "GenSigTimeoutTime" BU_SG_REL_ Klima SG_ 2527679668 eTM_BMS_Ventil2_Befuellung 5000;
BA_REL_ "GenSigTimeoutTime" BU_SG_REL_ Klima SG_ 2527679668 eTM_Pumpe1_Volumenstrom 5000;
BA_REL_ "GenSigTimeoutTime" BU_SG_REL_ Klima SG_ 2527679668 eTM_BMS_Pumpe1_Befuellung 5000;
BA_REL_ "GenSigTimeoutTime" BU_SG_REL_ Klima SG_ 2527679668 eTM_BMS_Ventil1_Befuellung 5000;
BA_REL_ "GenSigTimeoutTime" BU_SG_REL_ Klima SG_ 2527679668 eTM_Pumpe1_Status 5000;
BA_REL_ "GenSigTimeoutTime" BU_SG_REL_ Klima SG_ 2527679668 eTM_Pumpe2_Status 5000;
BA_REL_ "GenSigTimeoutTime" BU_SG_REL_ Klima SG_ 2527679668 eTM_Temperatur_1 5000;
BA_REL_ "GenSigTimeoutTime" BU_SG_REL_ Klima SG_ 2527679668 eTM_Temperatur_2 5000;
BA_REL_ "GenSigTimeoutTime" BU_SG_REL_ Klima SG_ 888 GNSS_Ortung_Hoehe 5000;
BA_REL_ "GenSigTimeoutTime" BU_SG_REL_ Klima SG_ 2463978722 GNSS_DR_Breite_Ortung 1000;
BA_REL_ "GenSigTimeoutTime" BU_SG_REL_ Klima SG_ 2463978722 GNSS_DR_Richtung_Breite_Ortung 1000;
BA_REL_ "GenSigTimeoutTime" BU_SG_REL_ Klima SG_ 2463978722 GNSS_DR_Laenge_Ortung 1000;
BA_REL_ "GenSigTimeoutTime" BU_SG_REL_ Klima SG_ 2463978722 GNSS_DR_Richtung_Laenge_Ortung 1000;
BA_REL_ "GenSigTimeoutTime" BU_SG_REL_ Klima SG_ 2463978723 GNSS_DR_Ortung_Ausrichtung 1000;
BA_REL_ "GenSigTimeoutTime" BU_SG_REL_ Klima SG_ 2463978726 GNSS_DR_UTC_Zeit 1000;
BA_REL_ "GenSigTimeoutTime" BU_SG_REL_ Klima SG_ 1410 HDSG_Anf_Umluftklappe 2000;
BA_REL_ "GenSigTimeoutTime" BU_SG_REL_ Klima SG_ 1016 HLR_KRH_Freigabe_VL 5000;
BA_REL_ "GenSigTimeoutTime" BU_SG_REL_ Klima SG_ 1016 HLR_KRH_Freigabe_VR 5000;
BA_REL_ "GenSigTimeoutTime" BU_SG_REL_ Klima SG_ 1016 HLR_SIH_Freigabe_VL 5000;
BA_REL_ "GenSigTimeoutTime" BU_SG_REL_ Klima SG_ 1016 HLR_SIH_Freigabe_VR 5000;
BA_REL_ "GenSigTimeoutTime" BU_SG_REL_ Klima SG_ 1016 HLR_SIH_Freigabe_HL 5000;
BA_REL_ "GenSigTimeoutTime" BU_SG_REL_ Klima SG_ 1016 HLR_SIH_Freigabe_HR 5000;
BA_REL_ "GenSigTimeoutTime" BU_SG_REL_ Klima SG_ 1016 HLR_SIL_Freigabe_VL 5000;
BA_REL_ "GenSigTimeoutTime" BU_SG_REL_ Klima SG_ 1016 HLR_SIL_Freigabe_VR 5000;
BA_REL_ "GenSigTimeoutTime" BU_SG_REL_ Klima SG_ 1016 HLR_SIL_Freigabe_HL 5000;
BA_REL_ "GenSigTimeoutTime" BU_SG_REL_ Klima SG_ 1016 HLR_SIL_Freigabe_HR 5000;
BA_REL_ "GenSigTimeoutTime" BU_SG_REL_ Klima SG_ 1016 HLR_FSH_Freigabe 5000;
BA_REL_ "GenSigTimeoutTime" BU_SG_REL_ Klima SG_ 1016 HLR_HSH_Freigabe 5000;
BA_REL_ "GenSigTimeoutTime" BU_SG_REL_ Klima SG_ 1016 HLR_LRH_Freigabe 5000;
BA_REL_ "GenSigTimeoutTime" BU_SG_REL_ Klima SG_ 1016 HLR_PTC_linear_Freigabe 5000;
BA_REL_ "GenSigTimeoutTime" BU_SG_REL_ Klima SG_ 1016 HLR_PTC_Freigabe 5000;
BA_REL_ "GenSigTimeoutTime" BU_SG_REL_ Klima SG_ 1452 HVEM_Energie_Klima_Vorgabe_HighR 1000;
BA_REL_ "GenSigTimeoutTime" BU_SG_REL_ Klima SG_ 1452 HVEM_Leistung_Klima_Vorgabe 1000;
BA_REL_ "GenSigTimeoutTime" BU_SG_REL_ Klima SG_ 1452 HVEM_Nutzbare_Energie 1000;
BA_REL_ "GenSigTimeoutTime" BU_SG_REL_ Klima SG_ 1452 HVEM_Energie_Klima_Vorgabe 1000;
BA_REL_ "GenSigTimeoutTime" BU_SG_REL_ Klima SG_ 1452 HVEM_HV_Anf 1000;
BA_REL_ "GenSigTimeoutTime" BU_SG_REL_ Klima SG_ 1385 HVEM_FreigabeKlimatisierung 5000;
BA_REL_ "GenSigTimeoutTime" BU_SG_REL_ Klima SG_ 1385 HVEM_Leistung_Bat_Kond_Vorgabe 5000;
BA_REL_ "GenSigTimeoutTime" BU_SG_REL_ Klima SG_ 1283 HVK_01_CRC 1000;
BA_REL_ "GenSigTimeoutTime" BU_SG_REL_ Klima SG_ 1283 HVK_01_BZ 1000;
BA_REL_ "GenSigTimeoutTime" BU_SG_REL_ Klima SG_ 1283 HVK_Vorladung_aktiv 1000;
BA_REL_ "GenSigTimeoutTime" BU_SG_REL_ Klima SG_ 1283 HVK_HV_Netz_Warnungen 1000;
BA_REL_ "GenSigTimeoutTime" BU_SG_REL_ Klima SG_ 1283 HV_Bordnetz_aktiv 1000;
BA_REL_ "GenSigTimeoutTime" BU_SG_REL_ Klima SG_ 1283 HV_Bordnetz_Fehler 1000;
BA_REL_ "GenSigTimeoutTime" BU_SG_REL_ Klima SG_ 1283 HVK_AktiveEntladung_Anf 1000;
BA_REL_ "GenSigTimeoutTime" BU_SG_REL_ Klima SG_ 1283 HVK_Notabschaltung_Anf 1000;
BA_REL_ "GenSigTimeoutTime" BU_SG_REL_ Klima SG_ 1283 HVK_Iso_Messung_Start 1000;
BA_REL_ "GenSigTimeoutTime" BU_SG_REL_ Klima SG_ 1428 HVLM_Bat_laden_aktiv 5000;
BA_REL_ "GenSigTimeoutTime" BU_SG_REL_ Klima SG_ 1428 HVLM_Ladeart 5000;
BA_REL_ "GenSigTimeoutTime" BU_SG_REL_ Klima SG_ 1428 HVLM_VK_Anf 5000;
VAL_ 252 ESC_aktBR_Modus_02 0 "Aktivbremsung_Aus" 1 "Aktivbremsung_FastInit" 2 "Aktivbremsung_Aktiv" 3 "Aktivbremsung_NoLimitAktiv" ;
VAL_ 252 ESC_Blending_Solldruck 1022 "Init" 1023 "Fehler" ;
VAL_ 252 ESC_EBKV_Kraftblending_Modus 0 "Inactive" 1 "Hold" 2 "Active" ;
VAL_ 252 ESC_Bremsdruck_Modell 1022 "Init" 1023 "Fehler" ;
VAL_ 252 ESC_Bremsdruck_02 1023 "Fehler" ;
VAL_ 252 ESC_QBit_Bremsdruck_02 0 "gueltiger_Wert" 1 "Ersatz_Init_oder_Fehlerwert" ;
VAL_ 252 ESC_Allradverteilung_aktiv 0 "kein_Eingriff" 1 "Allradeingriff_aktiv" ;
VAL_ 252 ESP_HL_Radgeschw_02 65533 "Unterspannung" 65534 "Init" 65535 "Fehler" ;
VAL_ 252 ESP_HR_Radgeschw_02 65533 "Unterspannung" 65534 "Init" 65535 "Fehler" ;
VAL_ 252 ESP_VL_Radgeschw_02 65533 "Unterspannung" 65534 "Init" 65535 "Fehler" ;
VAL_ 252 ESP_VR_Radgeschw_02 65533 "Unterspannung" 65534 "Init" 65535 "Fehler" ;
VAL_ 252 ESP_FZR_uebersteuern 254 "Init" 255 "Fehler" ;
VAL_ 252 ESP_FZR_untersteuern 254 "Init" 255 "Fehler" ;
VAL_ 252 ESC_Anf_Mindestreku 0 "nicht_angefordert" 1 "angefordert" ;
VAL_ 252 ESC_GMV_aktiv 0 "keine_Aktivitaet" 1 "Aktivitaet_durch_AWA" ;
VAL_ 252 ESC_GMV_nicht_verfuegbar 0 "verfuegbar" 1 "nicht_verfuegbar" ;
VAL_ 252 ESC_Status_vRef_Stuetzeingriff 0 "kein_Eingriff" 1 "Stuetzungseingriff" ;
VAL_ 252 FDR_Allradverteilung_aktiv 0 "kein_Eingriff" 1 "Allradeingriff_aktiv" ;
VAL_ 252 FDR_Anf_Allradbetrieb 0 "keine_Anforderung" 1 "Kraftschluss_an_beiden_Achsen_herstellen" ;
VAL_ 252 ESP_HL_Bremsmoment 254 "Init" 255 "Fehler" ;
VAL_ 252 ESP_HR_Bremsmoment 254 "Init" 255 "Fehler" ;
VAL_ 252 ESP_VR_Bremsmoment 254 "Init" 255 "Fehler" ;
VAL_ 252 ESP_VL_Bremsmoment 254 "Init" 255 "Fehler" ;
VAL_ 252 ESP_FDR_uebersteuern 254 "Init" 255 "Fehler" ;
VAL_ 252 ESP_FDR_untersteuern 254 "Init" 255 "Fehler" ;
VAL_ 252 TSMomBegrenzung 4094 "Init" 4095 "Fehler" ;
VAL_ 252 ESC_Allrad_Anteil_max_sek 510 "Init" 511 "Fehler" ;
VAL_ 252 ESC_Allrad_Anteil_min_sek 510 "Init" 511 "Fehler" ;
VAL_ 252 ESC_Status_Eingriff 0 "kein Eingriff" 1 "ASR-Eingriff" 2 "MSR-Eingriff" 3 "nicht belegt " ;
VAL_ 252 ESC_Status_Eingriff_sek 0 "kein Eingriff" 1 "ASR-Eingriff" 2 "MSR-Eingriff" 3 "nicht belegt " ;
VAL_ 252 ESC_MomRad_Eingriff 8190 "Init" 8191 "Fehler" ;
VAL_ 252 ESC_MomRad_Eingriff_sek 8190 "Init" 8191 "Fehler" ;
VAL_ 252 ESC_Achsdrehzahl_Max 16382 "Init" 16383 "Fehler" ;
VAL_ 252 ESC_Achsdrehzahl_Min 16382 "Init" 16383 "Fehler" ;
VAL_ 252 ESC_Achsdrehzahl_Max_sek 16382 "Init" 16383 "Fehler" ;
VAL_ 252 ESC_Achsdrehzahl_Min_sek 16382 "Init" 16383 "Fehler" ;
VAL_ 253 BR_Eingriffsmoment 1022 "Init" 1023 "Fehler" ;
VAL_ 253 ESP_PLA_Bremseingriff 0 "inaktiv" 1 "aktiv" ;
VAL_ 253 ESP_Diagnose 0 "ESP_nicht_in_Diagnose" 1 "ESP_in_Diagnose" ;
VAL_ 253 ESC_Reku_Freigabe 0 "keine_Freigabe_der_Rekuperation" 1 "Freigabe_der_Rekuperation" ;
VAL_ 253 ESC_v_Signal_Qualifier_High_Low 0 "Gueteschwelle_kleiner_1kmh" 1 "Gueteschwelle_kleiner_3kmh" 2 "Gueteschwelle_kleiner_5kmh" 3 "Gueteschwelle_kleiner_10kmh" 4 "Gueteschwelle_kleiner_20kmh" 5 "Gueteschwelle_groessergleich_20kmh" 6 "Init" 7 "Fehler" ;
VAL_ 253 ESP_Vorsteuerung 0 "keine_Vorsteuerung_aktiv" 1 "Vorsteuerung_aktiv" ;
VAL_ 253 ESP_AWV3_Brems_aktiv 0 "inaktiv" 1 "aktiv" ;
VAL_ 253 OBD_Schlechtweg 0 "kein_Schlechtweg_erkannt" 1 "Schlechtweg_erkannt" ;
VAL_ 253 OBD_QBit_Schlechtweg 0 "gueltiger_Wert" 1 "Ersatz_Init_oder_Fehlerwert" ;
VAL_ 253 ESP_v_Signal 65533 "Unterspannung" 65534 "Init" 65535 "Fehler" ;
VAL_ 253 ASR_Tastung_passiv 0 "ASR_aktiviert" 1 "ASR_passiv_getastet_oder_Schwellen_geaendert" ;
VAL_ 253 ESP_Tastung_passiv 0 "ESP_aktiviert" 1 "ESP_passiv_getastet_oder_Schwellen_geaendert" ;
VAL_ 253 ESP_Systemstatus 0 "iO" 1 "Fehler" ;
VAL_ 253 ASR_Schalteingriff 0 "keine_Anforderung" 1 "ASR_Schaltkennfeld" 2 "Rueckschaltung" 3 "Schaltverbot" ;
VAL_ 253 ESP_Haltebestaetigung 0 "kein_sicheres_Halten" 1 "sicheres_Halten" ;
VAL_ 253 ESP_MKB_Abbruch_Geschw 0 "MKB_nicht_beendet_wg_v_Schwelle" 1 "MKB_beendet_wg_v_Schwelle" ;
VAL_ 253 ESP_QBit_v_Signal 0 "gueltiger_Wert" 1 "Ersatz_Init_oder_Fehlerwert" ;
VAL_ 253 ABS_Bremsung 0 "keine_ABS_Regelung" 1 "ABS_Regelung_aktiv" ;
VAL_ 253 ASR_Anf 0 "keine_Anforderung" 1 "ASR_Anforderung" ;
VAL_ 253 MSR_Anf 0 "keine Anfoderung" 1 "MSR-Anforderung" ;
VAL_ 253 EBV_Eingriff 0 "kein_EBV_Eingriff" 1 "EBV_Eingriff" ;
VAL_ 253 EDS_Eingriff 0 "kein_EDS_Eingriff" 1 "EDS_Eingriff" ;
VAL_ 253 ESP_Eingriff 0 "kein_ESP_Eingriff" 1 "ESP_Eingriff_aktiv" ;
VAL_ 253 ESP_ASP 0 "inaktiv" 1 "aktiv" ;
VAL_ 253 ESP_Anhaltevorgang_ACC_aktiv 0 "inaktiv" 1 "aktiv" ;
VAL_ 2527679668 eTM_Pumpe1_Volumenstromteilung 126 "Init" 127 "keine_Parallelschaltung" ;
VAL_ 2527679668 eTM_Ventil1_Status 0 "Ventil_nicht_angesteuert" 1 "Ventil_angesteuert" 5 "Ventil_nicht_verbaut" 6 "Init" 7 "Fehler" ;
VAL_ 2527679668 eTM_Ventil2_Status 0 "Ventil_nicht_angesteuert" 1 "Ventil_angesteuert" 5 "Ventil_nicht_verbaut" 6 "Init" 7 "Fehler" ;
VAL_ 2527679668 eTM_Ventil3_Status 0 "Ventil_nicht_angesteuert" 1 "Ventil_angesteuert" 5 "Ventil_nicht_verbaut" 6 "Init" 7 "Fehler" ;
VAL_ 2527679668 eTM_Pumpe3_Status 13 "nicht_verbaut" 14 "Init" 15 "Fehler" ;
VAL_ 2527679668 eTM_BMS_Pumpe1_SollAnsteuerung 14 "Init" 15 "Fehler" ;
VAL_ 2527679668 eTM_Pumpe2_Volumenstrom 61 "nicht_verbaut" 62 "Init" 63 "Fehler" ;
VAL_ 2527679668 eTM_BMS_Ventil2_Befuellung 0 "false" 1 "true" ;
VAL_ 2527679668 eTM_Pumpe1_Volumenstrom 61 "nicht_verbaut" 62 "Init" 63 "Fehler" ;
VAL_ 2527679668 eTM_BMS_Pumpe1_Befuellung 0 "false" 1 "true" ;
VAL_ 2527679668 eTM_BMS_Ventil1_Befuellung 0 "false" 1 "true" ;
VAL_ 2527679668 eTM_Pumpe1_Status 13 "nicht_verbaut" 14 "Init" 15 "Fehler" ;
VAL_ 2527679668 eTM_Pumpe2_Status 13 "nicht_verbaut" 14 "Init" 15 "Fehler" ;
VAL_ 2527679668 eTM_Temperatur_1 254 "Init" 255 "Fehler" ;
VAL_ 2527679668 eTM_Temperatur_2 253 "nicht_verbaut" 254 "Init" 255 "Fehler" ;
VAL_ 2589283684 GRA_FoD_Status 0 "Init" 1 "Funktion_inaktiv" 2 "Funktion_aktiv" ;
VAL_ 2589283684 FoD_Transmission_Info 0 "Initwert" 1 "start_transmission" 2 "finish_transmission" ;
VAL_ 888 GNSS_Ortung_Zeit_in_GPSWoche 1073741822 "Init" 1073741823 "Fehler" ;
VAL_ 888 GNSS_Ortung_Hoehe 4094 "Init" 4095 "Fehler" ;
VAL_ 2463978722 GNSS_DR_Breite_Ortung 134217726 "Init" 134217727 "Fehler" ;
VAL_ 2463978722 GNSS_DR_Richtung_Breite_Ortung 0 "Nord" 1 "Sued" ;
VAL_ 2463978722 GNSS_DR_Laenge_Ortung 268435454 "Init" 268435455 "Fehler" ;
VAL_ 2463978722 GNSS_DR_Richtung_Laenge_Ortung 0 "Ost" 1 "West" ;
VAL_ 2463978723 GNSS_DR_Ortung_Ausrichtung 4094 "Init" 4095 "Fehler" ;
VAL_ 2463978723 GNSS_DR_Ortung_2D_Geschw_u_Grund 510 "Init" 511 "Fehler" ;
VAL_ 2463978726 GNSS_DR_UTC_Zeit 0 "Init" ;
VAL_ 1410 HD_Endstellung_oben 1 "HD in Endstellung oben (offen)" ;
VAL_ 1410 HD_Endstellung_unten 0 "Init" 1 "HD in Endstellung unten (geschlossen)" ;
VAL_ 1410 HD_Bewegung_auf 0 "Init" 1 "HD in Bewegung auf" ;
VAL_ 1410 HD_Bewegung_zu 0 "Init" 1 "HD in Bewegung zu" ;
VAL_ 1410 HD_Innentaster_betaetigt 0 "HD_Innentaster_nicht_betaetigt" 1 "HD_Innentaster_betaetigt" ;
VAL_ 1410 HD_Kupp_Ma_aktiv 1 "Kupplung 1 ein" ;
VAL_ 1410 HD_Kupp_Sl_aktiv 1 "Kupplung 2 aktiv" ;
VAL_ 1410 HD_UeKB_erkannt 0 "Init" 1 "Einklemmschutz aktiv" ;
VAL_ 1410 HD_SG_MA_KD_Fehler 0 "SG_funktionsfaehig" 1 "SG_defekt" ;
VAL_ 1410 HD_SG_SL_KD_Fehler 0 "SG_funktionsfaehig" 1 "SG_defekt" ;
VAL_ 1410 HD_Taster_defekt 0 "Taster_funktionsfähig" 1 "Taster defekt" ;
VAL_ 1410 HD_Rueckmeld_prog 0 "keine Rueckmeldung" 1 "Rueckmeldung zur Programmierung Endstellung aktiv" ;
VAL_ 1410 HD_Verriegelungstaster_betaetigt 0 "Taster_nicht_betaetigt" 1 "Taster_betaetigt" ;
VAL_ 1410 HD_Verr_Taster_betaetigt_inv 0 "Taster_betaetigt" 1 "Taster_nicht_betaetigt" ;
VAL_ 1410 HD_ZZH_Schalter_S3 0 "nicht_betaetigt" 1 "betaetigt" ;
VAL_ 1410 HDSG_Anf_Umluftklappe 0 "aus" 1 "an" ;
VAL_ 1016 HLR_FlHz_Freigabe_Ruhesitz 0 "0_Prozent" 1 "33_Prozent" 2 "66_Prozent" 3 "100_Prozent" ;
VAL_ 1016 HLR_FlHz_Freigabe_VR 0 "0_Prozent" 1 "33_Prozent" 2 "66_Prozent" 3 "100_Prozent" ;
VAL_ 1016 HLR_FlHz_Freigabe_VL 0 "0_Prozent" 1 "33_Prozent" 2 "66_Prozent" 3 "100_Prozent" ;
VAL_ 1016 HLR_FlHz_Freigabe_HR 0 "0_Prozent" 1 "33_Prozent" 2 "66_Prozent" 3 "100_Prozent" ;
VAL_ 1016 HLR_FlHz_Freigabe_HL 0 "0_Prozent" 1 "33_Prozent" 2 "66_Prozent" 3 "100_Prozent" ;
VAL_ 1016 HLR_TCH_Freigabe 0 "keine_Freigabe" 1 "Freigabe" ;
VAL_ 1016 HLR_SIH_Freigabe_Fond 0 "keine_Freigabe" 1 "Freigabe" ;
VAL_ 1016 HLR_Sp_Heizung_Freigabe_BT 0 "keine_Freigabe" 1 "Freigabe" ;
VAL_ 1016 HLR_Sp_Heizung_Freigabe_FT 0 "keine_Freigabe" 1 "Freigabe" ;
VAL_ 1016 HLR_KRH_Freigabe_VL 0 "0_Prozent" 1 "33_Prozent" 2 "66_Prozent" 3 "100_Prozent" ;
VAL_ 1016 HLR_KRH_Freigabe_VR 0 "0_Prozent" 1 "33_Prozent" 2 "66_Prozent" 3 "100_Prozent" ;
VAL_ 1016 HLR_SIH_Freigabe_VL 0 "0_Prozent" 1 "33_Prozent" 2 "66_Prozent" 3 "100_Prozent" ;
VAL_ 1016 HLR_SIH_Freigabe_VR 0 "0_Prozent" 1 "33_Prozent" 2 "66_Prozent" 3 "100_Prozent" ;
VAL_ 1016 HLR_SIH_Freigabe_HL 0 "0_Prozent" 1 "33_Prozent" 2 "66_Prozent" 3 "100_Prozent" ;
VAL_ 1016 HLR_SIH_Freigabe_HR 0 "0_Prozent" 1 "33_Prozent" 2 "66_Prozent" 3 "100_Prozent" ;
VAL_ 1016 HLR_SIL_Freigabe_VL 0 "0_Prozent" 1 "33_Prozent" 2 "66_Prozent" 3 "100_Prozent" ;
VAL_ 1016 HLR_SIL_Freigabe_VR 0 "0_Prozent" 1 "33_Prozent" 2 "66_Prozent" 3 "100_Prozent" ;
VAL_ 1016 HLR_SIL_Freigabe_HL 0 "0_Prozent" 1 "33_Prozent" 2 "66_Prozent" 3 "100_Prozent" ;
VAL_ 1016 HLR_SIL_Freigabe_HR 0 "0_Prozent" 1 "33_Prozent" 2 "66_Prozent" 3 "100_Prozent" ;
VAL_ 1016 HLR_FSH_Freigabe 0 "AUS" 63 "Fehler" ;
VAL_ 1016 HLR_HSH_Freigabe 0 "keine_Freigabe" 1 "Freigabe" ;
VAL_ 1016 HLR_LRH_Freigabe 0 "keine_Freigabe" 1 "Freigabe" ;
VAL_ 1016 HLR_PTC_linear_Freigabe 63 "Fehler" ;
VAL_ 1016 HLR_PTC_Freigabe 0 "Aus" 1 "Stufe_1" 2 "Stufe_2" 3 "Stufe_3" ;
VAL_ 1452 HVEM_IstStrom_HVVerbraucher 4094 "Init" 4095 "Fehler" ;
VAL_ 1452 HVEM_Energie_Klima_Vorgabe_HighR 6 "Init" 7 "Fehler" ;
VAL_ 1452 HVEM_IstLeistungNA 510 "Init" 511 "Fehler" ;
VAL_ 1452 HVEM_Leistung_Klima_Vorgabe 254 "Init" 255 "Fehler" ;
VAL_ 1452 HVEM_Nutzbare_Energie 2045 "Max" 2046 "Init" 2047 "Fehler" ;
VAL_ 1452 HVEM_Energie_Klima_Vorgabe 254 "Init" 255 "Fehler" ;
VAL_ 1452 HVEM_HVK_Aktivitaet 0 "keine_Aktivitaet" 1 "Aktivitaet" 2 "Init" ;
VAL_ 1452 HVEM_Pruefpuls_Anf 0 "Keine_Anforderung" 1 "Anforderung" 2 "Reserved" 3 "Init" ;
VAL_ 1452 HVEM_NVEM_Leistungsvorgabe 126 "Init" 127 "Fehler" ;
VAL_ 1452 HVEM_HV_Anf 0 "keine_Anforderung" 1 "HV_angefordert" ;
VAL_ 1452 HVEM_MO_MaxLeistungIgnoriert 0 "Max_Leistung_nicht_ignoriert" 1 "Max_Leistung_ignoriert" ;
VAL_ 1385 HVEM_ZusatzMinLeistungNA_Anf 510 "Init" ;
VAL_ 1385 HVEM_Betriebsart 0 "Standby" 1 "HV_Aktiv" 3 "Fahrbereit" 4 "HV_Laden" 5 "Autonom" ;
VAL_ 1385 HVEM_DCDC_Freigabe 0 "keine_Freigabe" 1 "Freigabe" ;
VAL_ 1385 HVEM_Ladesteckerentr_Anf 0 "keine_Anforderung" 1 "Anf_Ladestecker_Entr" ;
VAL_ 1385 HVEM_LeistungsAnf 0 "nicht_angefordert" 1 "angefordert" ;
VAL_ 1385 HVEM_Nachlad_Status 0 "nicht_moeglich__Fehler" 1 "moeglich__begonnen" 2 "Beendet" 3 "Init" ;
VAL_ 1385 HVEM_Abschaltstatus 0 "100" 1 "75" 2 "50" 3 "25" 7 "Init" ;
VAL_ 1385 HVEM_Anf_ReichweiteNV 0 "keine_Massnahme_notwendig" 1 "Reduktion_Stufe_1" 2 "Reduktion_Stufe_2" 3 "Fehler" ;
VAL_ 1385 HVEM_WunschLeistungNA_Anf 510 "Init" ;
VAL_ 1385 HVEM_Text_1 0 "kein_Text" 1 "Text" ;
VAL_ 1385 HVEM_Nachladen_Anf 0 "keine_Anforderung" 1 "Nachladen_angefordert" ;
VAL_ 1385 HVEM_FreigabeKlimatisierung 0 "keine_Freigabe" 1 "Freigabe" 2 "Init" 3 "Fehler" ;
VAL_ 1385 HVEM_FreigabeBattHeizung 0 "keine_Freigabe" 1 "Freigabe" 2 "Init" 3 "Fehler" ;
VAL_ 1385 HVEM_MinLeistungNA_Anf 510 "Init" ;
VAL_ 1385 HVEM_Leistung_Bat_Kond_Vorgabe 254 "Init" ;
VAL_ 1283 HVK_Istmodus_Anf 0 "nicht_angefordert" 1 "angefordert" ;
VAL_ 1283 HVK_TN1_Sollmodus 0 "HV_Off" 1 "HV_On" 2 "reserviert" 3 "Initialisierung" ;
VAL_ 1283 HVK_Vorladung_aktiv 0 "Vorladung_nicht_aktiv" 1 "Vorladung_aktiv" ;
VAL_ 1283 HVK_BMS_Sollmodus 0 "HV_Off" 1 "HV_On" 3 "AC_Laden_erw" 4 "AC_Laden" 6 "DC_Laden" 7 "Init" ;
VAL_ 1283 HVK_DCDC_Sollmodus 0 "Standby" 1 "HV_On_Vorladen" 2 "Tiefsetzen" 3 "Hochsetzen" 4 "Pruefpuls_12V" 6 "Pruefpuls_DC_Laden" 7 "Initialisierung" ;
VAL_ 1283 HVK_EKK_Sollmodus 0 "Keine_Freigabe" 1 "Freigabe" 2 "Freigabe_ausgesetzt" 7 "Init" ;
VAL_ 1283 HVK_HVPTC_Sollmodus 0 "Keine_Freigabe" 1 "Freigabe" 2 "Freigabe_ausgesetzt" 7 "Init" ;
VAL_ 1283 HVK_HVLM_Sollmodus 0 "keine_Freigabe" 1 "Freigabe_Lademanager" 2 "Vorladung_AC_Pfad" 7 "Init" ;
VAL_ 1283 HVK_HV_Netz_Warnungen 0 "Keine_Warnung" 1 "Warntext_HV_Netz_Anf" 2 "Fehlertext_HV_Netz_Anf" 3 "Warnung_Kein_Wiederstart_moeglich" ;
VAL_ 1283 HV_Bordnetz_aktiv 0 "inaktiv" 1 "aktiv" ;
VAL_ 1283 HV_Bordnetz_Fehler 0 "kein_Fehler" 1 "Fehler" ;
VAL_ 1283 HVK_Gesamtst_Spgfreiheit 0 "Funktion_Init__ohne_Funktion" 1 "HV_System_spannungsfrei" 2 "HV_System_nicht_spannungsfrei" 3 "Fehler" ;
VAL_ 1283 HVK_AktiveEntladung_Anf 0 "nicht_angefordert" 1 "angefordert" ;
VAL_ 1283 HVK_HVEM_Freigabe 0 "keine_Freigabe" 1 "Freigabe" 2 "Init" ;
VAL_ 1283 HVK_Notabschaltung_Anf 0 "keine_Anforderung_Notabschaltung" 1 "Anforderung_Notabschaltung" 2 "Reserve" 3 "Init" ;
VAL_ 1283 HVK_Iso_Messung_Start 0 "keine_Messung" 1 "Messung_HV_Netz_1" 2 "Messung_HV_Netz_2" 4 "deaktiviert" ;
VAL_ 1283 HVK_Ladebereit 0 "Init_oder_nicht_Ladebereit" 1 "AC_Ladebereit" 2 "DC_Ladebereit" 3 "AC_und_DC_Ladebereit" 4 "Induktiv_Ladebereit" 5 "AC_und_Induktiv_Ladebereit" 6 "DC_und_Induktiv_Ladebereit" 7 "AC_DC_und_Induktiv_Ladebereit" ;
VAL_ 1283 HVK_PPulsFreigabe 0 "keine_Freigabe" 1 "Freigabe" 2 "Reserve" 3 "Init" ;
VAL_ 2331595857 HVK_BMS_DC_Ladeschuetze_Soll 0 "auf" 1 "zu" 2 "reserviert" 3 "reserviert" 4 "reserviert" 5 "reserviert" 6 "Init" 7 "reserviert" ;
VAL_ 2331595857 HVK_BMS_Hauptschuetze_Soll 0 "auf" 1 "zu" 2 "reserviert" 3 "reserviert" 4 "reserviert" 5 "reserviert" 6 "Init" 7 "reserviert" ;
VAL_ 2331595857 HVK_DC_PruefpulsStatus 0 "Pruefpuls_inaktiv" 1 "Pruefpuls_aktiv" 2 "Pruefspannung_erreicht" 3 "Init" ;
VAL_ 1428 HVLM_Warnmeldungen 0 "keine_Anzeige" 1 "Nachladewarnung_Batterieschutz" 2 "Vollst_Laden_nicht_moeglich" 3 "Ladeverlaengerung_Notladen" 4 "Fehler_Ladedose_Sensor_Temp" 5 "Fehler_Steckerverriegelung" 6 "Fehler_Ladesaeule" 7 "Hinweis_Ladestecker_Temp" 8 "Hinweis_Notentriegeln" 9 "Hinweis_Temperatur_niedrig" 10 "Hinweis_laden_klimatisieren" 11 "Fehler_kein_PnC_verfuegbar_Fzg" 12 "Fehler_kein_PnC_verfuegbar_LS" 13 "reserve" 14 "reserve" 15 "reserve" 16 "reserve" 17 "reserve" 18 "reserve" 19 "reserve" 20 "reserve" 21 "reserve" ;
VAL_ 1428 HVLM_Restladezeit_HV_Bat_02 510 "Init" 511 "Fehler" ;
VAL_ 1428 HVLM_Lademodus_HV_Bat 0 "Sofortlademodus" 1 "zeitversetztes_Laden" ;
VAL_ 1428 HVLM_VK_STH_Einsatz 0 "Verbrennerstandheizung verbieten" 1 "Automatik (Verbrennerstandheizung erlauben)" 2 "Verbrennerstandheizung erzwingen" 3 "reserviert" 4 "reserviert" 5 "reserviert" 6 "Init" 7 "Fehler" ;
VAL_ 1428 HVLM_Anzeigetexte 0 "keine_Anzeige" 1 "Klappe_hinten_offen" 2 "Klappe_vorn_offen" 3 "Klappe_hinten_und_vorn_offen" 4 "oeffnen_nicht_moeglich" 5 "Stoerung_Ladeklappe" 7 "Fehler" ;
VAL_ 1428 HVLM_Bat_laden_aktiv 0 "inaktiv" 1 "aktiv" ;
VAL_ 1428 HVLM_HVEM_MaxLeistung 510 "Init" 511 "Fehler" ;
VAL_ 1428 HVLM_Standklima_Timer_Status 0 "Standklimatimer_nicht_aktiv" 1 "Standklimatimer_aktiv" ;
VAL_ 1428 HVLM_Fehler_Ladestecker 0 "kein_Fehler" 1 "Fehler" ;
VAL_ 1428 HVLM_Fehler_Verriegelung 0 "kein_Fehler" 1 "Fehler" ;
VAL_ 1428 HVLM_Ladeart 0 "keine_Auswahl" 1 "AC_Laden" 2 "DC_Laden" 3 "Konditionierung" ;
VAL_ 1428 HVLM_Status_Netz 0 "Fzg_nicht_am_Netz" 1 "Fzg_ist_am_Stromnetz" ;
VAL_ 1428 HVLM_HV_Anf 0 "keine_Anforderung" 1 "Laden_angefordert" 2 "Batteriekonditionierung_angefordert" 3 "Standklimatisierung_angefordert" ;
VAL_ 1428 HVLM_VK_Anf 0 "nicht_angefordert" 1 "angefordert" ;
VAL_ 1428 HVLM_Ladesystemhinweise 0 "kein_Hinweis" 1 "Ladesystem_defekt" 2 "Ladesaeule_inkompatibel" 3 "DC_Laden_nicht_moeglich" ;
VAL_ 1428 HVLM_VK_Modus 0 "keine Vorkonditionierung" 1 "Sofort-Konditionierung" 2 "zeitversetzte Konditionierung" 3 "Fehler" ;
VAL_ 1428 HVLM_Stecker_Status 0 "Init" 1 "kein_Stecker_gesteckt" 2 "Stecker_erkannt_nicht_verriegelt" 3 "Stecker_erkannt_und_verriegelt" ;
VAL_ 1428 HVLM_Langzeit_Laden 0 "keine_Anforderung" 1 "Anforderung_Reduzierung_Batterie_SOC_auf_Stufe_1" 2 "Anforderung_Reduzierung_Batterie_SOC_auf_Stufe_2" 3 "Fehler" ;
VAL_ 1428 HVLM_Klima_Temp 29 "VW_high_30C" 30 "Init" 31 "Fehler" ;
VAL_ 1428 HVLM_HSH_Anf 0 "keine_Anforderung" 1 "Heckscheibenheizung_Anf" ;
VAL_ 1428 HVLM_Bat_Konditionierung_Anf 0 "keine_Anforderung" 1 "HV_Bat_Konditionierung_Anf" ;
VAL_ 1428 HVLM_FSH_Anf 0 "keine_Anforderung" 1 "Frontscheibenheizung_Anf" ;
VAL_ 2463978689 HVLM_SollSoCKonservierung 126 "Init" 127 "Fehler" ;
VAL_ 2463978689 HVLM_BCCMKundenfreigabe_Status 0 "keine_Freigabe" 1 "Freigabe_alle_Stufen" 2 "Freigabe_eine_Stufe" 3 "Freigabe_zwei_Stufen" 4 "Freigabe_drei_Stufen" 5 "Reserve" 6 "Reserve" 7 "In_Funktion_nicht_enthalten" ;
VAL_ 2463978689 HVLM_BCCM_SoC 14 "Init" 15 "Fehler" ;
VAL_ 2463978689 HVLM_IstKonsWunschHVBat 0 "kein_Konservierungswunsch" 1 "Konservierungswunsch" ;
VAL_ 2463978689 HVLM_BCAM_Aktiv 0 "inaktiv" 1 "aktiv" ;
VAL_ 2463978689 HVLM_FreigabeLeistungNebenverbr 511 "Fehler" ;
VAL_ 2463978689 HVLM_IstStrom_02 8190 "Init" 8191 "Fehler" ;
VAL_ 625 HVLM_Stecker_VerEntriegelnAnf_A 0 "keine_Anforderung" 1 "Ladestecker_verriegeln" 2 "Ladestecker_entriegeln" 3 "reserve" ;
VAL_ 625 HVLM_Stecker_VerEntriegelnAnf_B 0 "keine_Anforderung" 1 "Ladestecker_verriegeln" 2 "Ladestecker_entriegeln" 3 "reserve" ;
VAL_ 625 HVLM_DC_SollStrom 2046 "Init" 2047 "Fehler" ;
VAL_ 625 HVLM_OBG_SollModus 0 "Standby" 1 "Netzladung_Anforderung" 2 "Rueckspeisung_solo" 3 "Rueckspeisung_grid" 4 "Vorladen_Anforderung" ;
VAL_ 625 HVLM_SF4OeffnenAnf_A 0 "schliessen" 1 "oeffnen" ;
VAL_ 625 HVLM_SF4OeffnenAnf_B 0 "schliessen" 1 "oeffnen" ;
VAL_ 625 HVLM_S2SchliessenAnf_A 0 "oeffnen" 1 "schliessen" ;
VAL_ 625 HVLM_S2SchliessenAnf_B 0 "oeffnen" 1 "schliessen" ;
VAL_ 625 HVLM_CP_Fehlerzustand_A 0 "Init" 1 "kein_Fehler" 2 "Spannung_niO" 3 "Frequenz_niO" 4 "Tastgrad_niO" 5 "State_niO" ;
VAL_ 625 HVLM_CP_Fehlerzustand_B 0 "Init" 1 "kein_Fehler" 2 "Spannung_niO" 3 "Frequenz_niO" 4 "Tastgrad_niO" 5 "State_niO" ;
VAL_ 625 HVLM_CP_MaxStrom_A 1021 "nicht_bekannt" 1022 "Init" ;
VAL_ 625 HVLM_CP_KommProtokoll_A 0 "Init" 1 "Basis_PWM" 2 "HLC_Datenkommunikation" 3 "unbekannt" ;
VAL_ 625 HVLM_CP_State_A 0 "Init" 1 "A" 2 "B1" 3 "B2" 4 "C1" 5 "C2" 6 "E" 7 "F" 8 "kein_Zustand_erkannt" ;
VAL_ 625 HVLM_CP_MaxStrom_B 1021 "nicht_bekannt" 1022 "Init" ;
VAL_ 625 HVLM_CP_KommProtokoll_B 0 "Init" 1 "Basis_PWM" 2 "HLC_Datenkommunikation" 3 "unbekannt" ;
VAL_ 625 HVLM_CP_State_B 0 "Init" 1 "A" 2 "B1" 3 "B2" 4 "C1" 5 "C2" 6 "E" 7 "F" 8 "kein_Zustand_erkannt" ;
VAL_ 625 HVLM_Max_Strom_Netz_L1 1022 "Init" 1023 "Fehler" ;
VAL_ 625 HVLM_Max_Strom_Netz_L2 1022 "Init" 1023 "Fehler" ;
VAL_ 625 HVLM_Max_Strom_Netz_L3 1022 "Init" 1023 "Fehler" ;
VAL_ 625 HVLM_MaxSpannung_OBG_HV 1022 "Init" 1023 "Fehler" ;
VAL_ 625 HVLM_Stecker_Notentriegeln_Anf_A 0 "Init" 1 "keine_Notentriegelung" 2 "Ladestecker_notentriegeln" ;
VAL_ 625 HVLM_Stecker_Notentriegeln_Anf_B 0 "Init" 1 "keine_Notentriegelung" 2 "Ladestecker_notentriegeln" ;
VAL_ 625 HVLM_Ladeklappe_VerEntriegeAnf_1 0 "Init" 1 "Ladeklappe_verriegeln" 2 "Ladeklappe_entriegeln" 3 "keine_Anforderung" ;
VAL_ 625 HVLM_Ladeklappe_VerEntriegeAnf_2 0 "Init" 1 "Ladeklappe_verriegeln" 2 "Ladeklappe_entriegeln" 3 "keine_Anforderung" ;
VAL_ 625 LVB_Ladegeschw 8190 "Init" ;
VAL_ 625 LVB_LadegeschwEinheit 0 "Init" 1 "Kilometer_pro_Minute" 2 "Kilometer_pro_Stunde" 3 "Meilen_pro_Minute" 4 "Meilen_pro_Stunde" ;
VAL_ 625 LVB_StatusLadegeschw 0 "calculating" 1 "valid" 2 "invalid" ;
VAL_ 625 LVB_StatusRestladezeit 0 "calculating" 1 "valid" 2 "invalid" ;
VAL_ 625 LVB_Restladezeit 4094 "Init" 4095 "Fehler" ;
VAL_ 625 HVLM_LadedosenSuchlicht 0 "Suchlicht_aus" 1 "Suchlicht_an" 2 "Stecker_erkannt" ;
VAL_ 625 LVB_Ladegeschw_VZ 0 "Wertebereich_positiv" 1 "Wertebereich_negativ" ;
VAL_ 625 HVLM_ReversierenFreigabe_Lk1 0 "erlaubt" 1 "nicht_erlaubt" ;
VAL_ 625 HVLM_SchnellladeVokoManuell_Anf 0 "inaktiv" 1 "aktiv" ;
VAL_ 625 HVLM_SchnellladeVokoAuto_Anf 0 "inaktiv" 1 "aktiv" ;
VAL_ 625 HVLM_Ladeklappe_VerEntriegeAnf_3 0 "Init" 1 "Ladeklappe_verriegeln" 2 "Ladeklappe_entriegeln" 3 "keine_Anforderung" ;
VAL_ 625 HVLM_ReversierenFreigabe_Lk2 0 "erlaubt" 1 "nicht_erlaubt" ;
VAL_ 625 HVLM_elektrLk_Kommandierung_Lk2 0 "Sperren" 1 "Oeffnen" 2 "Schliessen" 3 "Referenzfahrt" 7 "Init" ;
VAL_ 625 HVLM_elektrLk_Kommandierung_Lk1 0 "Sperren" 1 "Oeffnen" 2 "Schliessen" 3 "Referenzfahrt" 7 "Init" ;
VAL_ 625 HVLM_elektrLk_Kommandierung_Lk3 0 "Sperren" 1 "Oeffnen" 2 "Schliessen" 3 "Referenzfahrt" 7 "Init" ;
VAL_ 625 HVLM_ReversierenFreigabe_Lk3 0 "erlaubt" 1 "nicht_erlaubt" ;
VAL_ 625 HVLM_Stecker_Notentriegeln_Anf_C 0 "Init" 1 "keine_Notentriegelung" 2 "Ladestecker_notentriegeln" ;
VAL_ 625 HVLM_Stecker_VerEntriegelnAnf_C 0 "keine_Anforderung" 1 "Ladestecker_verriegeln" 2 "Ladestecker_entriegeln" ;
VAL_ 626 HVLM_Aktive_Ladeart 0 "Kein_Laden_aktiv" 1 "AC_Laden_aktiv" 2 "DC_Laden_aktiv" 3 "AWC" 4 "Reserve" 5 "Reserve" 6 "Reserve" 7 "Fehler" ;
VAL_ 626 HVLM_Pulsierstufe 0 "keine_Anforderung" 1 "Stufe_0" 2 "Stufe_1" 3 "Stufe_2" 4 "Stufe_3" 5 "Stufe_4" 6 "Stufe_5" 7 "Stufe_6" ;
VAL_ 626 HVLM_Intensitaet_Lk2 126 "Init" 127 "Fehler" ;
VAL_ 626 HVLM_Anforderung_HMS 0 "keine_Anforderung" 1 "halten" 2 "parken" 3 "halten_Standby" 4 "anfahren" 5 "Loesen_ueber_Rampe" ;
VAL_ 626 HVLM_Parken_beibehalten_HMS 0 "Parken_nicht_beibehalten" 1 "Parken_beibehalten" 2 "Init" 3 "Fehler" ;
VAL_ 626 HVLM_WakeUpZaehlerResetAnf 0 "keine_Anforderung" 1 "Reset_Zaehler" ;
VAL_ 626 HVLM_AWC_VerbautStatus 0 "Init" 1 "nicht_verbaut" 2 "verbaut" 3 "Fehler" ;
VAL_ 626 HVLM_Steckerstatus_A 0 "Init" 1 "kein_Stecker_erkannt" 2 "Stecker_steckt_nicht_verriegelt" 3 "Stecker_steckt_und_verriegelt" 7 "Fehler" ;
VAL_ 626 HVLM_Steckerstatus_B 0 "Init" 1 "kein_Stecker_erkannt" 2 "Stecker_steckt_nicht_verriegelt" 3 "Stecker_steckt_und_verriegelt" 7 "Fehler" ;
VAL_ 626 HVLM_Start_Pulserkennung 0 "keine_Anforderung" 1 "Pulserkennung_starten" ;
VAL_ 626 HVLM_ZustandLadeablauf 0 "Init" 1 "Stby_Ladevorbed_erfuellt" 2 "Stby_Ladevorbed_nicht_erfuellt" 3 "Fehler" 4 "Laden_starten" 5 "Laden_beenden" 6 "HVBatterie_Laden" 7 "HVBatterie_Entladen" 8 "Erhaltungsladen" ;
VAL_ 626 HVLM_DC_Aufstartmodus 0 "keine_Anforderung" 1 "Angleich_Fahrzeug" 2 "Angleich_LS_1" 3 "Angleich_LS_2" ;
VAL_ 626 HVLM_Ladeszenario 0 "Aus" 1 "Timerladen_abgeschlossen" 2 "Sofortladen_abgeschlossen" 3 "Optimiertes_Laden_abgeschlossen" 4 "Timerladen_aktiv" 5 "Sofortladen_aktiv" 6 "Optimiertes_Laden_aktiv" 7 "Timerladen_warten" 8 "Optimiertes_Laden_warten" 9 "Keine_Netzspannung" 10 "Fehler_Verriegelung" 11 "Fehler_Ladesytem" 12 "Init_Ladekommunikation" 15 "Notladen" 16 "Ladeunterbrechung_Kunde" 17 "Stecker_abziehbar" 18 "Kompatibilitaets_Umschaltung_aktiv" 30 "Init" 31 "Fehler" ;
VAL_ 626 HVLM_Ladevorgang_Anf 0 "Laden_nicht_angefordert" 1 "AC_Laden_Angefordert" 2 "DC_Laden_Angefordert" 3 "AC_und_DC_Angefordert" 4 "Induktiv_Laden_Angef" 5 "AC_und_Induktiv_Angef" 6 "DC_und_Induktiv_Angef" 7 "AC_DC_und_Induktiv_Angef" ;
VAL_ 626 HVLM_Intensitaet_Lk1 126 "Init" 127 "Fehler" ;
VAL_ 626 HVLM_Laden_ISO_Messung_Anf 0 "Anforderung" 1 "keine_Anforderung" ;
VAL_ 2463978708 HVLM_CDO_LsNachrichtSendenAnf 0 "Keine_Anforderung_LCAN_Komm" 1 "Anforderung_LSCAN_Komm" ;
VAL_ 2463978708 HVLM_CDO_LadeerlaubnisLm 0 "LadenNichtErlaubt" 1 "LadenErlaubt" ;
VAL_ 2463978708 HVLM_CDO_SteckerVerEntr_Status 0 "nicht_verriegelt" 1 "verriegelt" ;
VAL_ 2463978708 HVLM_CDO_DynamischLaden_Status 0 "nicht_kompatibel" 1 "kompatibel" ;
VAL_ 2463978708 HVLM_CDO_StromExt_Status 0 "nicht_kompatibel" 1 "kompatibel" ;
VAL_ 2463978708 HVLM_CDO_SpannungExt_Status 0 "nicht_kompatibel" 1 "kompatibel" ;
VAL_ 2463978708 HVLM_CDO_HvMinStromFzg 0 "Leistung_eins_und_halb_kW" ;
VAL_ 2463978708 HVLM_CDO_RestLadedauerFzg 0 "Restladezeit_nicht_unterstuetzt" ;
VAL_ 2463978708 HVLM_CDO_ProtokollVersionFzg 0 "Version_vor_0_9" 1 "Version_0_9_und_0_9_1" 2 "Version_1_0_und_1_1_und_1_2" 3 "Version_2_0" 168 "Version_3_0" ;
VAL_ 2463978708 HVLM_CDO_Fehler_HVBatUeberspgFzg 0 "keine_Batterieueberspannung" 1 "Batterieueberspannung" ;
VAL_ 2463978708 HVLM_CDO_Fehler_HVBatUnterspFzg 0 "keine_Batterieunterspannung" 1 "Batterieunterspannung" ;
VAL_ 2463978708 HVLM_CDO_Fehler_HVStromDiffFzg 0 "keine_Bat_Iststromabweichung" 1 "Batterie_Iststromabweichung" ;
VAL_ 2463978708 HVLM_CDO_Fehler_HVBatUebertemp 0 "keine_Batterieuebertemperatur" 1 "Batterieuebertemperatur" ;
VAL_ 2463978708 HVLM_CDO_Fehler_HVBatSpgDiffFzg 0 "keine_Spannungsabweichung" 1 "Spannungsabweichung" ;
VAL_ 2463978708 HVLM_CDO_LadebereitFzg 0 "keine_Ladebereitschaft" 1 "Ladebereitschaft" ;
VAL_ 2463978708 HVLM_CDO_WahlhebelPosition_P_Fzg 0 "Wahlhebel_in_P" 1 "Wahlhebel_nicht_in_P" ;
VAL_ 2463978708 HVLM_CDO_Fehler_Fahrzeug 0 "keine_sonstigen_Fehler" 1 "Fehler" ;
VAL_ 2463978708 HVLM_CDO_Status_Fahrzeug 0 "HVSchuetze_geschl_o_Weld_Det" 1 "HVSchuetze_offen_o_Weld_Det" ;
VAL_ 2463978708 HVLM_CDO_LadenBeendenAnfFzg 0 "keine_Anforderung" 1 "Beenden_anfordern" ;
VAL_ 2331596000 HVLM_CJ_01_Sendestatus 0 "langsamer_Zyklus" 1 "schneller_Zyklus" ;
VAL_ 2331596000 HVLM_CdoCj_SvsSchliessenAnf 0 "oeffnen" 1 "schliessen" ;
VAL_ 2331596000 HVLM_CJ_SendeAnf_LongMessage 0 "keine_Anforderung" 1 "senden" ;
VAL_ 2331596000 HVLM_CJ_SendeAnf_Pausieren 0 "keine_Anforderung" 1 "Kommunikation_pausieren" ;
VAL_ 2331596000 HVLM_CJ_SendeAnf_Stoppen 0 "keine_Anforderung" 1 "Kommunikation_stoppen" ;
VAL_ 2331596000 HVLM_CJ_SendeAnf_EndACK 0 "keine_Anforderung" 1 "senden" ;
VAL_ 2331596000 HVLM_CJ_SendeAnf_SMURM 0 "keine_Anforderung" 1 "senden" ;
VAL_ 2331596000 HVLM_CJ_VerbindungAnf 0 "keine_Anforderung" 1 "Verbindung_anfragen" ;
VAL_ 2331596000 HVLM_CJ_SendeAnf_ACK 0 "keine_Anforderung" 1 "Senden_SM_ACK" 2 "Senden_LM_ACK" ;
VAL_ 2331596000 HVLM_CJ_SendeAnf_SMRM 0 "keine_Anforderung" 1 "senden" ;
VAL_ 2331596000 HVLM_CdoCj_SvSchliessenAnf 0 "oeffnen" 1 "schliessen" ;
VAL_ 2331596000 HVLM_CJ_SteckerVerEntr_Status 0 "nicht_verriegelt" 1 "verriegelt" ;
VAL_ 2331596000 HVLM_CJ_FCFDC_CheckFzg 0 "FC_FDC_nicht_bestaetigt" 1 "FC_FDC_bestaetigt" 255 "Init" ;
VAL_ 2331596000 HVLM_CJ_IstSOC 65534 "Init" 65535 "Fehler" ;
VAL_ 2331596000 HVLM_CJ_Lademodus 1 "Strom_konstant" 2 "Spannung_konstant" 255 "Init" ;
VAL_ 2331596000 HVLM_CJ_CanTypFzg 0 "CAN_2_0" 1 "CAN_FD" 2 "CAN_XL" 255 "Init" ;
VAL_ 2331596000 HVLM_CJ_Restladezeit 65534 "Init" 65535 "Fehler" ;
VAL_ 2331596000 HVLM_CJ_PgiFzg 2 "BestaetigungFunktionsmodule" 4 "FahrzeugParameter" 6 "FahrzeugSelbstcheck" 11 "FahrzeugLadebereitschaft" 12 "FahrzeugLadebedarf" 13 "FahrzeugInformationen" 14 "FahrzeugLadeende" 21 "FahrzeugLadestatistik" 32 "FahrzeugFCFDC_Bestaetigung" 58 "ErgebnisProtokollversion" 255 "Init" ;
VAL_ 2331596000 HVLM_CJ_GrundLadeendeFzg 1 "normalesLadeende" 2 "Kommunikationsfehler" 3 "LadeendeDuchFehler" 4 "LadeendeDurchLadesaeule" 255 "Init" ;
VAL_ 2331596000 HVLM_CJ_LadebereitschaftFzg 0 "not_ready" 1 "ready" ;
VAL_ 2331596000 HVLM_CJ_StatusProtokollVerh 0 "ongoing" 1 "erfolgreich" 2 "fehlgeschlagen" 255 "Init" ;
VAL_ 2331596000 HVLM_CJ_MaxLadestromFzg 65534 "Init" 65535 "Fehler" ;
VAL_ 2331596000 HVLM_CJ_SollspannungFzg 65534 "Init" 65535 "Fehler" ;
VAL_ 2331596000 HVLM_CJ_MaxLadeernergieFzg 65534 "Init" 65535 "Fehler" ;
VAL_ 2331596000 HVLM_CJ_IstSpannungFzg 65534 "Init" 65535 "Fehler" ;
VAL_ 2331596000 HVLM_CJ_MaxLadspannungFzg 65534 "Init" 65535 "Fehler" ;
VAL_ 2331596000 HVLM_CJ_SollstromFzg 65534 "Init" 65535 "Fehler" ;
VAL_ 2331596000 HVLM_CdoCj_S2UmschaltenAnf 0 "Postion_0" 1 "Postion_1" 2 "Postion_2" 3 "Postion_3" 4 "Position_4" ;
VAL_ 2331596000 HVLM_CJ_LadeendeTimeoutFzg 1 "Timeout_Function_negotiation" 2 "Timeout_Parameterconfig" 3 "Timeout_Aufthentication" 4 "Timeout_Scheduling" 5 "Timeout_Systemselbstcheck" 6 "Timeout_Powersupply" 7 "Timeout_Precharging_and_Charging" 8 "Timeout_Charging_termination" 255 "Init" ;
VAL_ 2331596000 HVLM_CJ_LadeendeFehlerFzg 1 "Function_negotiation_nicht_erfolgreich" 2 "Parameterconfig_nicht_erfolgreich" 3 "Aufthentication_nicht_erfolgreich" 4 "Scheduling_nicht_erfolgreich" 5 "System_Selbstcheck_nicht_erfolgreich" 6 "Powersupply_nicht_erfolgreich" 7 "Precharging_and_Charging_nicht_erfolgreich" 8 "Charging_termination_nicht_erfolgreich" 255 "Init" ;
VAL_ 2331596000 HVLM_CJ_LadeendeFzg 1 "Allgemeine_Ladeende" 2 "Funktionsmodul_Timeout" 3 "Funktionsmodul_nicht_erfolgreich" 4 "Andere_Gruende" 255 "Init" ;
